VERSION ""

NS_ :

BS_:

BU_: VMCU TPM RCIOM FCIOM FAS ECUspare4 EBS EAS CCIOM BPMU APM

BO_ 1934 Debug6_FCIOM_Chassi: 8 FCIOM
 SG_ Debug_6_FCIOM : 0|64@1+ (1,0) [0|0] "" Vector__XXX

BO_ 1938 Debug6_FAS_Chassi: 8 FAS
 SG_ Debug_6_FAS : 0|64@1+ (1,0) [0|0] "" Vector__XXX

BO_ 1939 Debug6_EAS_Chassi: 8 EAS
 SG_ Debug_6_EAS : 0|64@1+ (1,0) [0|0] "" Vector__XXX

BO_ 1933 Debug6_CCIOM_Chassi: 8 CCIOM
 SG_ Debug_6_CCIOM : 0|64@1+ (1,0) [0|0] "" Vector__XXX

BO_ 1932 Debug6_BPMU_Chassi: 8 BPMU
 SG_ Debug_6_BPMU : 0|64@1+ (1,0) [0|0] "" Vector__XXX

BO_ 1936 Debug6_APM_Chassi: 8 APM
 SG_ Debug_6_APM : 0|64@1+ (1,0) [0|0] "" Vector__XXX

BO_ 1929 Debug5_TPM_Chassi: 8 TPM
 SG_ Debug_5_TPM : 0|64@1+ (1,0) [0|0] "" Vector__XXX

BO_ 1927 Debug5_RCIOM_Chassi: 8 RCIOM
 SG_ Debug_5_RCIOM : 0|64@1+ (1,0) [0|0] "" Vector__XXX

BO_ 1926 Debug5_FCIOM_Chassi: 8 FCIOM
 SG_ Debug_5_FCIOM : 0|64@1+ (1,0) [0|0] "" Vector__XXX

BO_ 1930 Debug5_FAS_Chassi: 8 FAS
 SG_ Debug_5_FAS : 0|64@1+ (1,0) [0|0] "" Vector__XXX

BO_ 1931 Debug5_EAS_Chassi: 8 EAS
 SG_ Debug_5_EAS : 0|64@1+ (1,0) [0|0] "" Vector__XXX

BO_ 1925 Debug5_CCIOM_Chassi: 8 CCIOM
 SG_ Debug_5_CCIOM : 0|64@1+ (1,0) [0|0] "" Vector__XXX

BO_ 1924 Debug5_BPMU_Chassi: 8 BPMU
 SG_ Debug_5_BPMU : 0|64@1+ (1,0) [0|0] "" Vector__XXX

BO_ 1928 Debug5_APM_Chassi: 8 APM
 SG_ Debug_5_APM : 0|64@1+ (1,0) [0|0] "" Vector__XXX

BO_ 1921 Debug4_TPM_Chassi: 8 TPM
 SG_ Debug_4_TPM : 0|64@1+ (1,0) [0|0] "" Vector__XXX

BO_ 1919 Debug4_RCIOM_Chassi: 8 RCIOM
 SG_ Debug_4_RCIOM : 0|64@1+ (1,0) [0|0] "" Vector__XXX

BO_ 1918 Debug4_FCIOM_Chassi: 8 FCIOM
 SG_ Debug_4_FCIOM : 0|64@1+ (1,0) [0|0] "" Vector__XXX

BO_ 1922 Debug4_FAS_Chassi: 8 FAS
 SG_ Debug_4_FAS : 0|64@1+ (1,0) [0|0] "" Vector__XXX

BO_ 1923 Debug4_EAS_Chassi: 8 EAS
 SG_ Debug_4_EAS : 0|64@1+ (1,0) [0|0] "" Vector__XXX

BO_ 1917 Debug4_CCIOM_Chassi: 8 CCIOM
 SG_ Debug_4_CCIOM : 0|64@1+ (1,0) [0|0] "" Vector__XXX

BO_ 1916 Debug4_BPMU_Chassi: 8 BPMU
 SG_ Debug_4_BPMU : 0|64@1+ (1,0) [0|0] "" Vector__XXX

BO_ 1920 Debug4_APM_Chassi: 8 APM
 SG_ Debug_4_APM : 0|64@1+ (1,0) [0|0] "" Vector__XXX

BO_ 1913 Debug3_TPM_Chassi: 8 TPM
 SG_ Debug_3_TPM : 0|64@1+ (1,0) [0|0] "" Vector__XXX

BO_ 1911 Debug3_RCIOM_Chassi: 8 RCIOM
 SG_ Debug_3_RCIOM : 0|64@1+ (1,0) [0|0] "" Vector__XXX

BO_ 1910 Debug3_FCIOM_Chassi: 8 FCIOM
 SG_ Debug_3_FCIOM : 0|64@1+ (1,0) [0|0] "" Vector__XXX

BO_ 1914 Debug3_FAS_Chassi: 8 FAS
 SG_ Debug_3_FAS : 0|64@1+ (1,0) [0|0] "" Vector__XXX

BO_ 1915 Debug3_EAS_Chassi: 8 EAS
 SG_ Debug_3_EAS : 0|64@1+ (1,0) [0|0] "" Vector__XXX

BO_ 1909 Debug3_CCIOM_Chassi: 8 CCIOM
 SG_ Debug_3_CCIOM : 0|64@1+ (1,0) [0|0] "" Vector__XXX

BO_ 1908 Debug3_BPMU_Chassi: 8 BPMU
 SG_ Debug_3_BPMU : 0|64@1+ (1,0) [0|0] "" Vector__XXX

BO_ 1912 Debug3_APM_Chassi: 8 APM
 SG_ Debug_3_APM : 0|64@1+ (1,0) [0|0] "" Vector__XXX

BO_ 1905 Debug2_TPM_Chassi: 8 TPM
 SG_ Debug_2_TPM : 0|64@1+ (1,0) [0|0] "" Vector__XXX

BO_ 1903 Debug2_RCIOM_Chassi: 8 RCIOM
 SG_ Debug_2_RCIOM : 0|64@1+ (1,0) [0|0] "" Vector__XXX

BO_ 1902 Debug2_FCIOM_Chassi: 8 FCIOM
 SG_ Debug_2_FCIOM : 0|64@1+ (1,0) [0|0] "" Vector__XXX

BO_ 1906 Debug2_FAS_Chassi: 8 FAS
 SG_ Debug_2_FAS : 0|64@1+ (1,0) [0|0] "" Vector__XXX

BO_ 1907 Debug2_EAS_Chassi: 8 EAS
 SG_ Debug_2_EAS : 0|64@1+ (1,0) [0|0] "" Vector__XXX

BO_ 1901 Debug2_CCIOM_Chassi: 8 CCIOM
 SG_ Debug_2_CCIOM : 0|64@1+ (1,0) [0|0] "" Vector__XXX

BO_ 1900 Debug2_BPMU_Chassi: 8 BPMU
 SG_ Debug_2_BPMU : 0|64@1+ (1,0) [0|0] "" Vector__XXX

BO_ 1904 Debug2_APM_Chassi: 8 APM
 SG_ Debug_2_APM : 0|64@1+ (1,0) [0|0] "" Vector__XXX

BO_ 1885 Debug21_APM_Chassi: 8 APM
 SG_ Debug_21_APM : 0|64@1+ (1,0) [0|0] "" Vector__XXX

BO_ 1884 Debug20_APM_Chassi: 8 APM
 SG_ Debug_20_APM : 0|64@1+ (1,0) [0|0] "" Vector__XXX

BO_ 1897 Debug1_TPM_Chassi: 8 Vector__XXX
 SG_ Debug_1_TPM : 0|64@1+ (1,0) [0|0] ""  TPM

BO_ 1895 Debug1_RCIOM_Chassi: 8 Vector__XXX
 SG_ Debug_1_RCIOM : 0|64@1+ (1,0) [0|0] ""  RCIOM

BO_ 1894 Debug1_FCIOM_Chassi: 8 Vector__XXX
 SG_ Debug_1_FCIOM : 0|64@1+ (1,0) [0|0] ""  FCIOM

BO_ 1898 Debug1_FAS_Chassi: 8 Vector__XXX
 SG_ Debug_1_FAS : 0|64@1+ (1,0) [0|0] ""  FAS

BO_ 1899 Debug1_EAS_Chassi: 8 Vector__XXX
 SG_ Debug_1_EAS : 0|64@1+ (1,0) [0|0] ""  EAS

BO_ 1893 Debug1_CCIOM_Chassi: 8 Vector__XXX
 SG_ Debug_1_CCIOM : 0|64@1+ (1,0) [0|0] ""  CCIOM

BO_ 1892 Debug1_BPMU_Chassi: 8 Vector__XXX
 SG_ Debug_1_BPMU : 0|64@1+ (1,0) [0|0] ""  BPMU

BO_ 1896 Debug1_APM_Chassi: 8 Vector__XXX
 SG_ Debug_1_APM : 0|64@1+ (1,0) [0|0] ""  APM

BO_ 1883 Debug19_APM_Chassi: 8 APM
 SG_ Debug_19_APM : 0|64@1+ (1,0) [0|0] "" Vector__XXX

BO_ 1882 Debug18_APM_Chassi: 8 APM
 SG_ Debug_18_APM : 0|64@1+ (1,0) [0|0] "" Vector__XXX

BO_ 1881 Debug17_APM_Chassi: 8 APM
 SG_ Debug_17_APM : 0|64@1+ (1,0) [0|0] "" Vector__XXX

BO_ 1959 Debug16_FAS_Chassi: 8 FAS
 SG_ Debug_16_FAS : 0|64@1+ (1,0) [0|0] "" Vector__XXX

BO_ 1880 Debug16_APM_Chassi: 8 APM
 SG_ Debug_16_APM : 0|64@1+ (1,0) [0|0] "" Vector__XXX

BO_ 1891 Debug15_FAS_Chassi: 8 FAS
 SG_ Debug_15_FAS : 0|64@1+ (1,0) [0|0] "" Vector__XXX

BO_ 1983 Debug15_APM_Chassi: 8 APM
 SG_ Debug_15_APM : 0|64@1+ (1,0) [0|0] "" Vector__XXX

BO_ 1890 Debug14_FAS_Chassi: 8 FAS
 SG_ Debug_14_FAS : 0|64@1+ (1,0) [0|0] "" Vector__XXX

BO_ 1982 Debug14_APM_Chassi: 8 APM
 SG_ Debug_14_APM : 0|64@1+ (1,0) [0|0] "" Vector__XXX

BO_ 1889 Debug13_FAS_Chassi: 8 FAS
 SG_ Debug_13_FAS : 0|64@1+ (1,0) [0|0] "" Vector__XXX

BO_ 1981 Debug13_APM_Chassi: 8 APM
 SG_ Debug_13_APM : 0|64@1+ (1,0) [0|0] "" Vector__XXX

BO_ 1888 Debug12_FAS_Chassi: 8 FAS
 SG_ Debug_12_FAS : 0|64@1+ (1,0) [0|0] "" Vector__XXX

BO_ 1963 Debug12_CCIOM_Chassi: 8 CCIOM
 SG_ Debug_12_CCIOM : 0|64@1+ (1,0) [0|0] "" Vector__XXX

BO_ 1964 Debug12_APM_Chassi: 8 APM
 SG_ Debug_12_APM : 0|64@1+ (1,0) [0|0] "" Vector__XXX

BO_ 1961 Debug11_RCIOM_Chassi: 8 RCIOM
 SG_ Debug_11_RCIOM : 0|64@1+ (1,0) [0|0] "" Vector__XXX

BO_ 1887 Debug11_FAS_Chassi: 8 FAS
 SG_ Debug_11_FAS : 0|64@1+ (1,0) [0|0] "" Vector__XXX

BO_ 1960 Debug11_CCIOM_Chassi: 8 CCIOM
 SG_ Debug_11_CCIOM : 0|64@1+ (1,0) [0|0] "" Vector__XXX

BO_ 1962 Debug11_APM_Chassi: 8 APM
 SG_ Debug_11_APM : 0|64@1+ (1,0) [0|0] "" Vector__XXX

BO_ 1957 Debug10_RCIOM_Chassi: 8 RCIOM
 SG_ Debug_10_RCIOM : 0|64@1+ (1,0) [0|0] "" Vector__XXX

BO_ 1886 Debug10_FAS_Chassi: 8 FAS
 SG_ Debug_10_FAS : 0|64@1+ (1,0) [0|0] "" Vector__XXX

BO_ 1956 Debug10_CCIOM_Chassi: 8 CCIOM
 SG_ Debug_10_CCIOM : 0|64@1+ (1,0) [0|0] "" Vector__XXX

BO_ 1955 Debug10_BPMU_Chassi: 8 BPMU
 SG_ Debug_10_BPMU : 0|64@1+ (1,0) [0|0] "" Vector__XXX

BO_ 1958 Debug10_APM_Chassi: 8 APM
 SG_ Debug_10_APM : 0|64@1+ (1,0) [0|0] "" Vector__XXX

BO_ 2041 DSPTesterResp: 8 FAS
 SG_ DSPTesterRespSig : 0|64@1+ (1,0) [0|0] "" Vector__XXX

BO_ 2047 DSPTesterReq: 8 Vector__XXX
 SG_ DSPTesterReqSig : 0|64@1+ (1,0) [0|0] ""  FAS

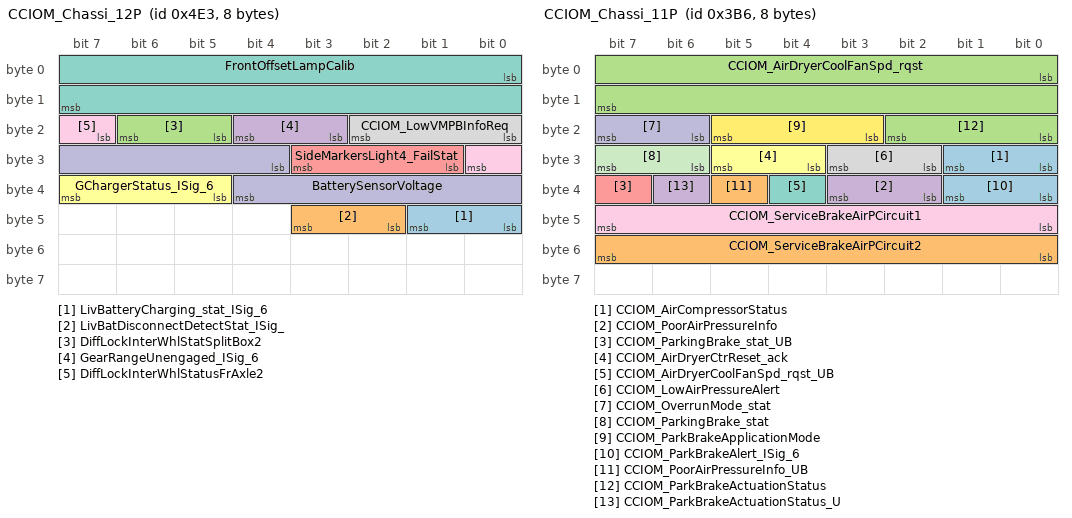
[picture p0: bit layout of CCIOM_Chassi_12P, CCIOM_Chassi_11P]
BO_ 1251 CCIOM_Chassi_12P: 8 CCIOM
 SG_ LivBatteryCharging_stat_ISig_6 : 40|2@1+ (1,0) [0|0] ""  BPMU,VMCU
 SG_ LivBatDisconnectDetectStat_ISig_ : 42|2@1+ (1,0) [0|0] ""  VMCU
 SG_ DiffLockInterWhlStatSplitBox2 : 21|2@1+ (1,0) [0|0] ""  VMCU
 SG_ GearRangeUnengaged_ISig_6 : 19|2@1+ (1,0) [0|0] ""  VMCU
 SG_ SideMarkersLight4_FailStat : 25|3@1+ (1,0) [0|0] ""  VMCU
 SG_ GChargerStatus_ISig_6 : 37|3@1+ (1,0) [0|0] ""  VMCU
 SG_ FrontOffsetLampCalib : 0|16@1+ (0.1,-3200) [-3200|3353.5] "mm"  RCIOM
 SG_ CCIOM_LowVMPBInfoReq : 16|3@1+ (1,0) [0|0] ""  EBS
 SG_ DiffLockInterWhlStatusFrAxle2 : 23|2@1+ (1,0) [0|0] ""  VMCU
 SG_ BatterySensorVoltage : 28|9@1+ (0.1,0) [0|51.1] "V"  BPMU

BO_ 950 CCIOM_Chassi_11P: 8 CCIOM
 SG_ CCIOM_AirCompressorStatus : 24|2@1+ (1,0) [0|0] ""  VMCU
 SG_ CCIOM_ServiceBrakeAirPCircuit2 : 48|8@1+ (8,0) [0|2040] "kPa"  RCIOM,VMCU
 SG_ CCIOM_AirDryerCoolFanSpd_rqst : 0|16@1+ (1,0) [0|65535] "rpm"  VMCU
 SG_ CCIOM_PoorAirPressureInfo : 34|2@1+ (1,0) [0|0] ""  VMCU
 SG_ CCIOM_ParkingBrake_stat_UB : 39|1@1+ (1,0) [0|0] ""  VMCU,RCIOM
 SG_ CCIOM_AirDryerCtrReset_ack : 28|2@1+ (1,0) [0|0] ""  VMCU
 SG_ CCIOM_AirDryerCoolFanSpd_rqst_UB : 36|1@1+ (1,0) [0|0] ""  VMCU
 SG_ CCIOM_LowAirPressureAlert : 26|2@1+ (1,0) [0|0] ""  EBS,VMCU
 SG_ CCIOM_ServiceBrakeAirPCircuit1 : 40|8@1+ (8,0) [0|2040] "kPa"  RCIOM,VMCU
 SG_ CCIOM_OverrunMode_stat : 22|2@1+ (1,0) [0|0] ""  VMCU
 SG_ CCIOM_ParkingBrake_stat : 30|2@1+ (1,0) [0|0] ""  VMCU,RCIOM
 SG_ CCIOM_ParkBrakeApplicationMode : 19|3@1+ (1,0) [0|0] ""  VMCU
 SG_ CCIOM_ParkBrakeAlert_ISig_6 : 32|2@1+ (1,0) [0|0] ""  VMCU
 SG_ CCIOM_PoorAirPressureInfo_UB : 37|1@1+ (1,0) [0|0] ""  VMCU
 SG_ CCIOM_ParkBrakeActuationStatus : 16|3@1+ (1,0) [0|0] ""  EBS,VMCU,RCIOM
 SG_ CCIOM_ParkBrakeActuationStatus_U : 38|1@1+ (1,0) [0|0] ""  EBS,RCIOM,VMCU

BO_ 1495 CCIOM_Chassi_10P: 8 CCIOM
 SG_ CCIOM_AirCtrMileagePrediction : 0|32@1+ (1,0) [0|4294967295] "km"  VMCU
 SG_ CCIOM_AirCtrWearingPercentage : 32|8@1+ (1,0) [0|255] "Percent"  VMCU

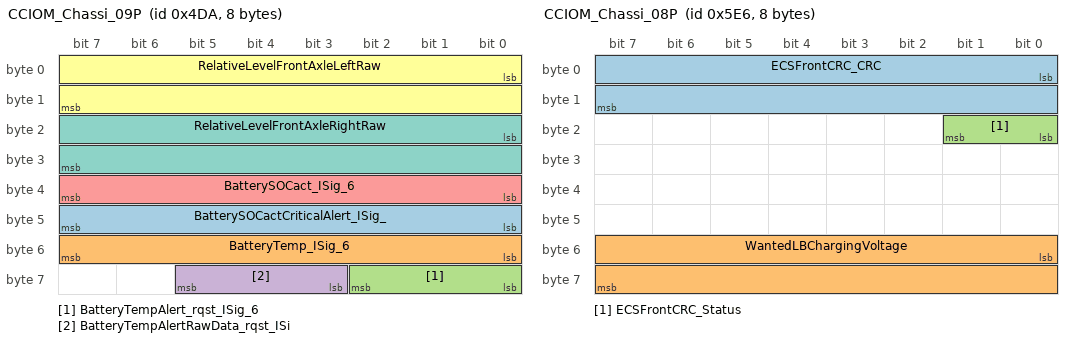
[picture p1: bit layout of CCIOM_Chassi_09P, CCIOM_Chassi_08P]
BO_ 1242 CCIOM_Chassi_09P: 8 CCIOM
 SG_ BatterySOCactCriticalAlert_ISig_ : 40|8@1+ (0.5,0) [0|127.5] "Percent"  VMCU
 SG_ BatteryTemp_ISig_6 : 48|8@1+ (1,-45) [-45|210] "DegreeC"  BPMU,VMCU
 SG_ BatteryTempAlert_rqst_ISig_6 : 56|3@1+ (1,0) [0|0] ""  VMCU
 SG_ BatteryTempAlertRawData_rqst_ISi : 59|3@1+ (1,0) [0|0] ""  VMCU
 SG_ BatterySOCact_ISig_6 : 32|8@1+ (0.5,0) [0|127.5] "Percent"  VMCU
 SG_ RelativeLevelFrontAxleLeftRaw : 0|16@1+ (0.1,-3200) [-3200|3353.5] "mm"  RCIOM
 SG_ RelativeLevelFrontAxleRightRaw : 16|16@1+ (0.1,-3200) [-3200|3353.5] "mm"  RCIOM

BO_ 1510 CCIOM_Chassi_08P: 8 CCIOM
 SG_ ECSFrontCRC_CRC : 0|16@1+ (1,0) [0|65535] ""  RCIOM
 SG_ WantedLBChargingVoltage : 48|16@1+ (0.01,0) [0|655.35] "V"  BPMU
 SG_ ECSFrontCRC_Status : 16|2@1+ (1,0) [0|0] ""  RCIOM

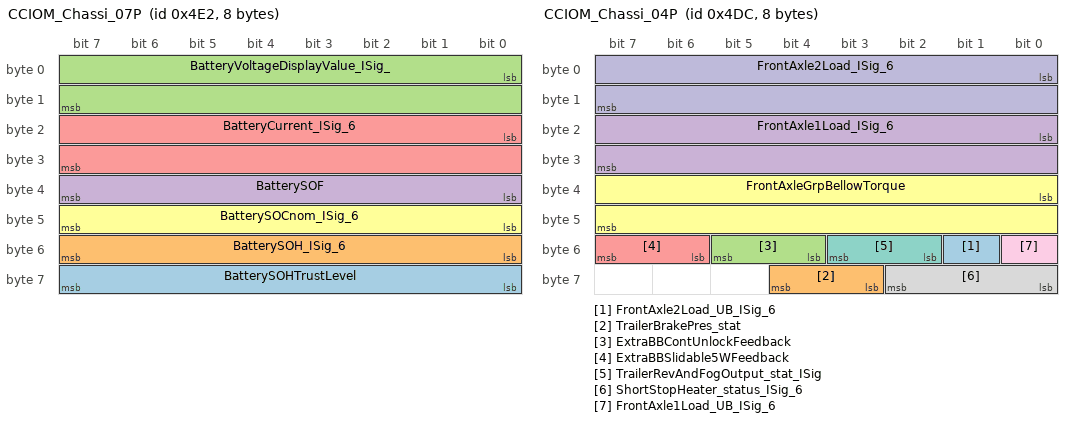
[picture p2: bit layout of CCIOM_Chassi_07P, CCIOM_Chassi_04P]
BO_ 1250 CCIOM_Chassi_07P: 8 CCIOM
 SG_ BatterySOHTrustLevel : 56|8@1+ (0.5,0) [0|127.5] "Percent"  VMCU
 SG_ BatterySOH_ISig_6 : 48|8@1+ (0.5,0) [0|127.5] "Percent"  VMCU
 SG_ BatteryVoltageDisplayValue_ISig_ : 0|16@1+ (0.05,0) [0|3276.75] "V"  VMCU
 SG_ BatterySOF : 32|8@1+ (1,0) [0|255] "h"  VMCU
 SG_ BatteryCurrent_ISig_6 : 16|16@1+ (0.05,-1600) [-1600|1676.75] "A"  VMCU
 SG_ BatterySOCnom_ISig_6 : 40|8@1+ (0.5,0) [0|127.5] "Percent"  BPMU,VMCU

BO_ 823 CCIOM_Chassi_06P: 8 CCIOM
 SG_ FifthWheelLockingInformation_ISi : 12|4@1+ (1,0) [0|0] ""  RCIOM,VMCU
 SG_ DoubleFrontAxleSteeringWarning_I : 2|2@1+ (1,0) [0|0] ""  VMCU
 SG_ DifferentialLockStateFrAxle1_ISi : 6|2@1+ (1,0) [0|0] ""  VMCU
 SG_ ElectricalLoadReduction_rqst_UB_ : 30|1@1+ (1,0) [0|0] ""  RCIOM,VMCU
 SG_ DirInd_MiddleSide_Status : 58|3@1+ (1,0) [0|0] ""  VMCU
 SG_ ExtendedTrailerBrakeValveStat : 61|2@1+ (1,0) [0|0] ""  VMCU
 SG_ DifferentialLockStateFrAxle1_UB_ : 31|1@1+ (1,0) [0|0] ""  VMCU
 SG_ TransmLowRangeSenseSwitch_ISig_6 : 8|2@1+ (1,0) [0|0] ""  VMCU
 SG_ ElectricalLoadReduction_rqst_ISi : 21|3@1+ (1,0) [0|0] ""  RCIOM,VMCU
 SG_ WrknLghtChassisOutpFalr_stat : 48|3@1+ (1,0) [0|0] ""  VMCU
 SG_ ManTransmiOilTemp_ISig_6 : 32|16@1+ (0.03125,-273) [-273|1774.96875] "DegreeC"  VMCU
 SG_ LoadCutOffIndication_cmd_ISig_6 : 4|2@1+ (1,0) [0|0] ""  VMCU
 SG_ TransmReverseDirectionSw_stat_IS : 56|2@1+ (1,0) [0|0] ""  VMCU
 SG_ BatterySOCAlert_rqst_ISig_6 : 16|3@1+ (1,0) [0|0] ""  VMCU
 SG_ GearSplit_Status_UB_ISig_6 : 52|1@1+ (1,0) [0|0] ""  VMCU
 SG_ BatteryCapacity_Ack : 19|2@1+ (1,0) [0|0] ""  VMCU
 SG_ ManTransmiOilTemp_UB_ISig_6 : 51|1@1+ (1,0) [0|0] ""  VMCU
 SG_ FrontLimpHomeTrigger : 24|3@1+ (1,0) [0|0] ""  RCIOM
 SG_ FifthWheelLockingInformation_UB_ : 53|1@1+ (1,0) [0|0] ""  RCIOM,VMCU
 SG_ GearSplit_Status_ISig_6 : 10|2@1+ (1,0) [0|0] ""  VMCU
 SG_ DiffLockInterWhlStatusSplitBox_I : 54|2@1+ (1,0) [0|0] ""  VMCU
 SG_ FifthWheelHandleLock_ind : 27|2@1+ (1,0) [0|0] ""  VMCU
 SG_ DifferentialLockStateCentral_ISi : 0|2@1+ (1,0) [0|0] ""  VMCU

BO_ 1244 CCIOM_Chassi_04P: 8 CCIOM
 SG_ FrontAxle2Load_UB_ISig_6 : 49|1@1+ (1,0) [0|0] ""  VMCU,EBS,FAS,APM,RCIOM
 SG_ TrailerBrakePres_stat : 59|2@1+ (1,0) [0|0] ""  VMCU
 SG_ ExtraBBContUnlockFeedback : 52|2@1+ (1,0) [0|0] ""  VMCU
 SG_ FrontAxle1Load_ISig_6 : 16|16@1+ (0.5,0) [0|32767.5] "kg"  RCIOM,VMCU,EBS,APM,FAS
 SG_ ExtraBBSlidable5WFeedback : 54|2@1+ (1,0) [0|0] ""  VMCU
 SG_ FrontAxleGrpBellowTorque : 32|16@1+ (1000,-10000000) [-10000000|55535000] "Nm"  RCIOM
 SG_ TrailerRevAndFogOutput_stat_ISig : 50|2@1+ (1,0) [0|0] ""  RCIOM,VMCU
 SG_ ShortStopHeater_status_ISig_6 : 56|3@1+ (1,0) [0|0] ""  VMCU
 SG_ FrontAxle1Load_UB_ISig_6 : 48|1@1+ (1,0) [0|0] ""  FAS,VMCU,APM,EBS,RCIOM
 SG_ FrontAxle2Load_ISig_6 : 0|16@1+ (0.5,0) [0|32767.5] "kg"  APM,FAS,VMCU,RCIOM,EBS

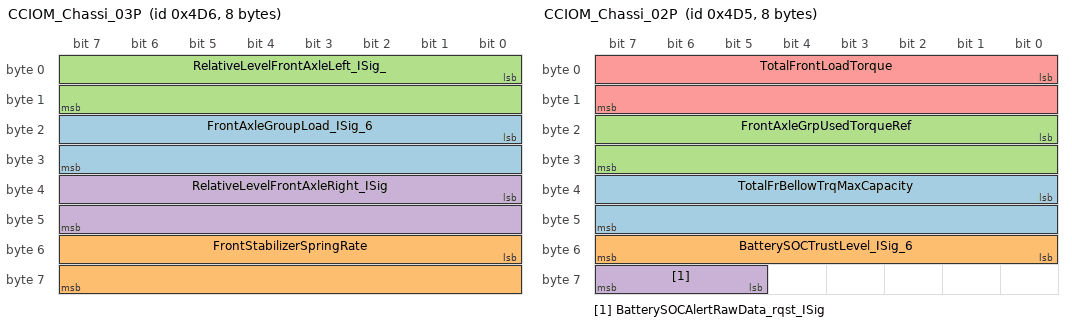
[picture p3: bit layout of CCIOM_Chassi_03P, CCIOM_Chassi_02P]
BO_ 1238 CCIOM_Chassi_03P: 8 CCIOM
 SG_ FrontAxleGroupLoad_ISig_6 : 16|16@1+ (2,0) [0|131070] "kg"  RCIOM,VMCU
 SG_ FrontStabilizerSpringRate : 48|16@1+ (1,0) [0|65535] "kNm_per_rad"  RCIOM
 SG_ RelativeLevelFrontAxleLeft_ISig_ : 0|16@1+ (0.1,-3200) [-3200|3353.5] "mm"  FAS,EBS,VMCU,RCIOM
 SG_ RelativeLevelFrontAxleRight_ISig : 32|16@1+ (0.1,-3200) [-3200|3353.5] "mm"  RCIOM,VMCU,EBS

BO_ 1237 CCIOM_Chassi_02P: 8 CCIOM
 SG_ TotalFrBellowTrqMaxCapacity : 32|16@1+ (1000,-10000000) [-10000000|55535000] "Nm"  RCIOM
 SG_ BatterySOCTrustLevel_ISig_6 : 48|8@1+ (0.5,0) [0|127.5] "Percent"  VMCU
 SG_ FrontAxleGrpUsedTorqueRef : 16|16@1+ (1000,-10000000) [-10000000|55535000] "Nm"  RCIOM
 SG_ BatterySOCAlertRawData_rqst_ISig : 61|3@1+ (1,0) [0|0] ""  BPMU,VMCU
 SG_ TotalFrontLoadTorque : 0|16@1+ (1000,-10000000) [-10000000|55535000] "Nm"  RCIOM

BO_ 774 CCIOM_Chassi_01P: 8 CCIOM
 SG_ FuelVolume_ISig_6 : 0|11@1+ (1,0) [0|2047] "l"  VMCU
 SG_ FuelVolume_UB_ISig_6 : 14|1@1+ (1,0) [0|0] ""  VMCU
 SG_ MainSwitch_Status : 28|2@1+ (1,0) [0|0] ""  APM,BPMU,VMCU
 SG_ Pto1FeedbackStatus_ISig_6 : 26|2@1+ (1,0) [0|0] ""  VMCU
 SG_ SWBrakeSwitch2 : 50|2@1+ (1,0) [0|0] ""  RCIOM
 SG_ ReverseGearEngaged_UB_ISig_6 : 38|1@1+ (1,0) [0|0] ""  FAS,VMCU,APM,RCIOM
 SG_ ReverseGearEngaged_ISig_6 : 36|2@1+ (1,0) [0|0] ""  VMCU,FAS,APM,RCIOM
 SG_ TransmissionNeutralSwitch_UB_ISi : 41|1@1+ (1,0) [0|0] ""  APM,VMCU
 SG_ SecuredNeutralPosition_ISig_6 : 34|2@1+ (1,0) [0|0] ""  VMCU,EBS,APM
 SG_ SecuredNeutralPosition_UB_ISig_6 : 40|1@1+ (1,0) [0|0] ""  APM,EBS,VMCU
 SG_ FuelLevel_ISig_6 : 16|8@1+ (0.4,0) [0|102] "Percent"  VMCU
 SG_ FuelLevel_UB_ISig_6 : 13|1@1+ (1,0) [0|0] ""  VMCU
 SG_ TransmSecuredForCrank_stat : 32|2@1+ (1,0) [0|0] ""  VMCU
 SG_ FrontTargetLevelReached : 11|2@1+ (1,0) [0|0] ""  RCIOM
 SG_ Pto1FeedbackStatus_UB_ISig_6 : 39|1@1+ (1,0) [0|0] ""  VMCU
 SG_ TransmissionNeutralSwitch_ISig_6 : 24|2@1+ (1,0) [0|0] ""  VMCU,APM
 SG_ BrakePressureSensorDemand2 : 42|8@1+ (1,0) [0|255] "Percent"  RCIOM

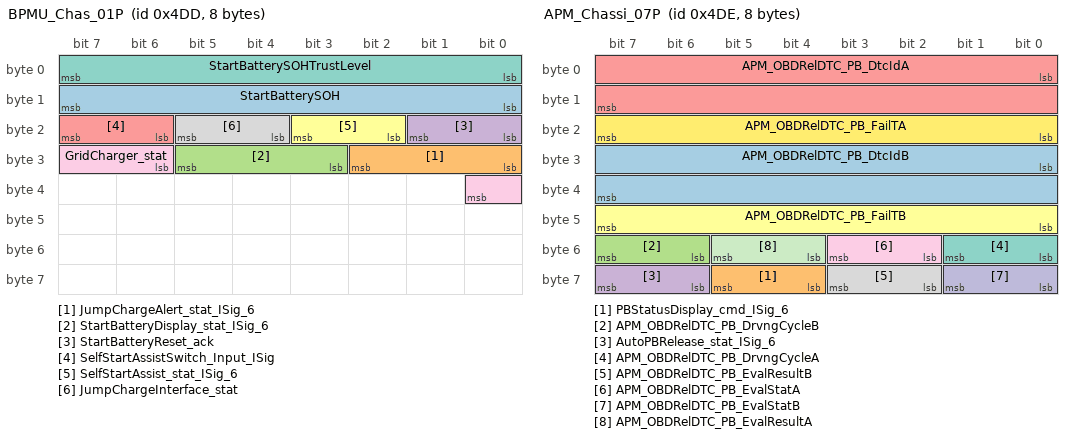
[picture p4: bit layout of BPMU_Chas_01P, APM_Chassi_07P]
BO_ 1245 BPMU_Chas_01P: 8 BPMU
 SG_ StartBatterySOH : 8|8@1+ (0.5,0) [0|127.5] "Percent"  VMCU
 SG_ JumpChargeAlert_stat_ISig_6 : 24|3@1+ (1,0) [0|0] ""  VMCU
 SG_ StartBatteryDisplay_stat_ISig_6 : 27|3@1+ (1,0) [0|0] ""  VMCU
 SG_ StartBatteryReset_ack : 16|2@1+ (1,0) [0|0] ""  VMCU
 SG_ SelfStartAssistSwitch_Input_ISig : 22|2@1+ (1,0) [0|0] ""  VMCU
 SG_ SelfStartAssist_stat_ISig_6 : 18|2@1+ (1,0) [0|0] ""  VMCU
 SG_ StartBatterySOHTrustLevel : 0|8@1+ (0.5,0) [0|127.5] "Percent"  VMCU
 SG_ JumpChargeInterface_stat : 20|2@1+ (1,0) [0|0] ""  CCIOM
 SG_ GridCharger_stat : 30|3@1+ (1,0) [0|0] ""  CCIOM

BO_ 1719 AnmMsg_VMCU_ChassisSubnet: 4 VMCU
 SG_ AnmSig_VMCU_ChassisSubnet : 0|32@1+ (1,0) [0|4294967295] ""  BPMU,RCIOM,APM,FCIOM,ECUspare4,TPM,EBS,CCIOM,EAS,FAS

BO_ 1718 AnmMsg_TPM_ChassisSubnet: 4 TPM
 SG_ AnmSig_TPM_ChassisSubnet : 0|32@1+ (1,0) [0|4294967295] ""  CCIOM,RCIOM,EBS,FCIOM,ECUspare4,FAS,BPMU,APM,EAS,VMCU

BO_ 1717 AnmMsg_RCIOM_ChassisSubnet: 4 RCIOM
 SG_ AnmSig_RCIOM_ChassisSubnet : 0|32@1+ (1,0) [0|4294967295] ""  APM,TPM,EBS,VMCU,BPMU,CCIOM,FAS,EAS,ECUspare4,FCIOM

BO_ 1716 AnmMsg_FCIOM_ChassisSubnet: 4 FCIOM
 SG_ AnmSig_FCIOM_ChassisSubnet : 0|32@1+ (1,0) [0|4294967295] ""  APM,BPMU,EBS,ECUspare4,FAS,RCIOM,CCIOM,VMCU,TPM,EAS

BO_ 1715 AnmMsg_FAS_ChassisSubnet: 4 FAS
 SG_ AnmSig_FAS_ChassisSubnet : 0|32@1+ (1,0) [0|4294967295] ""  ECUspare4,RCIOM,FCIOM,APM,CCIOM,TPM,EAS,EBS,BPMU,VMCU

BO_ 1721 AnmMsg_ECUspare4_ChassisSubnet: 4 ECUspare4
 SG_ AnmSig_ECUspare4_ChassisSubnet : 0|32@1+ (1,0) [0|4294967295] ""  EAS,APM,BPMU,EBS,TPM,FAS,FCIOM,VMCU,RCIOM,CCIOM

BO_ 1714 AnmMsg_EBS_ChassisSubnet: 4 EBS
 SG_ AnmSig_EBS_ChassisSubnet : 0|32@1+ (1,0) [0|4294967295] ""  RCIOM,FAS,ECUspare4,VMCU,EAS,FCIOM,APM,CCIOM,TPM,BPMU

BO_ 1722 AnmMsg_EAS_ChassisSubnet: 4 EAS
 SG_ AnmSig_EAS_ChassisSubnet : 0|32@1+ (1,0) [0|4294967295] ""  ECUspare4,EBS,VMCU,FAS,BPMU,FCIOM,APM,CCIOM,TPM,RCIOM

BO_ 1713 AnmMsg_CCIOM_ChassisSubnet: 4 CCIOM
 SG_ AnmSig_CCIOM_ChassisSubnet : 0|32@1+ (1,0) [0|4294967295] ""  TPM,APM,ECUspare4,RCIOM,FAS,FCIOM,EAS,EBS,BPMU,VMCU

BO_ 1720 AnmMsg_BPMU_ChassisSubnet: 4 BPMU
 SG_ AnmSig_BPMU_ChassisSubnet : 0|32@1+ (1,0) [0|4294967295] ""  CCIOM,APM,ECUspare4,VMCU,EAS,EBS,FCIOM,RCIOM,FAS,TPM

BO_ 1712 AnmMsg_APM_ChassisSubnet: 4 APM
 SG_ AnmSig_APM_ChassisSubnet : 0|32@1+ (1,0) [0|4294967295] ""  CCIOM,RCIOM,EAS,FCIOM,EBS,VMCU,ECUspare4,BPMU,TPM,FAS

BO_ 1246 APM_Chassi_07P: 8 APM
 SG_ APM_OBDRelDTC_PB_DtcIdB : 24|16@1+ (1,0) [0|65535] ""  VMCU
 SG_ PBStatusDisplay_cmd_ISig_6 : 60|2@1+ (1,0) [0|0] ""  VMCU
 SG_ APM_OBDRelDTC_PB_DrvngCycleB : 54|2@1+ (1,0) [0|0] ""  VMCU
 SG_ AutoPBRelease_stat_ISig_6 : 62|2@1+ (1,0) [0|0] ""  VMCU
 SG_ APM_OBDRelDTC_PB_DtcIdA : 0|16@1+ (1,0) [0|65535] ""  VMCU
 SG_ APM_OBDRelDTC_PB_FailTB : 40|8@1+ (1,0) [0|255] ""  VMCU
 SG_ APM_OBDRelDTC_PB_DrvngCycleA : 48|2@1+ (1,0) [0|0] ""  VMCU
 SG_ APM_OBDRelDTC_PB_EvalResultB : 58|2@1+ (1,0) [0|0] ""  VMCU
 SG_ APM_OBDRelDTC_PB_EvalStatA : 50|2@1+ (1,0) [0|0] ""  VMCU
 SG_ APM_OBDRelDTC_PB_EvalStatB : 56|2@1+ (1,0) [0|0] ""  VMCU
 SG_ APM_OBDRelDTC_PB_EvalResultA : 52|2@1+ (1,0) [0|0] ""  VMCU
 SG_ APM_OBDRelDTC_PB_FailTA : 16|8@1+ (1,0) [0|255] ""  VMCU

BO_ 1492 APM_Chassi_06P: 8 APM
 SG_ APM_AirCtrMileagePrediction : 0|32@1+ (1,0) [0|4294967295] "km"  VMCU
 SG_ APM_AirCtrWearingPercentage : 32|8@1+ (1,0) [0|255] "Percent"  VMCU

BO_ 1347 APM_Chassi_05S_FCM: 8 VMCU
 SG_ APM_Chassi_05S_FCS : 0|64@1+ (1,0) [0|0] ""  APM

BO_ 1346 APM_Chassi_05S: 11 APM
 SG_ ECU2VIN_stat_ISig_6 : 0|88@1+ (1,0) [0|0] ""  VMCU

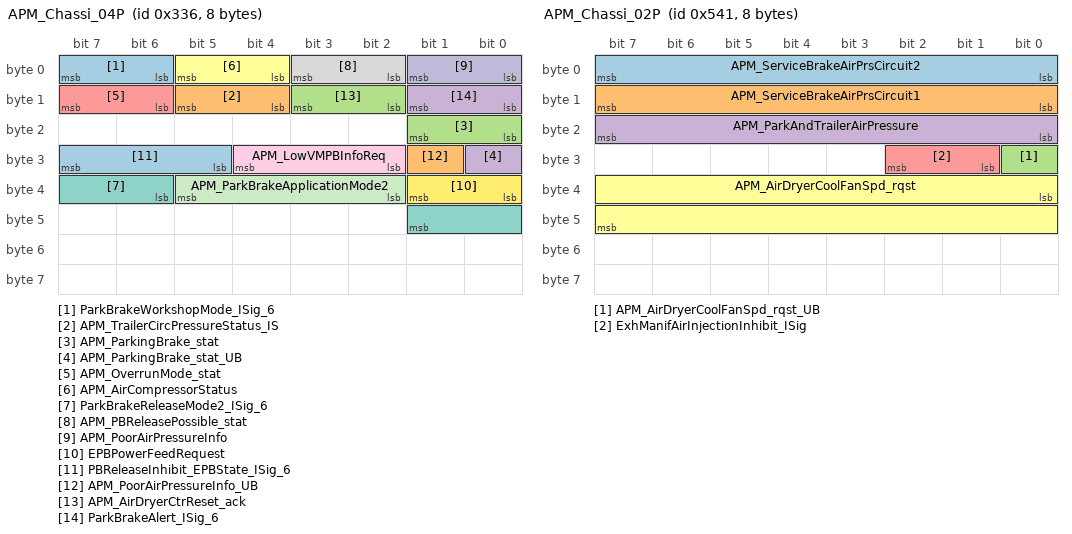
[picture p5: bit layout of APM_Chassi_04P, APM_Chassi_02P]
BO_ 822 APM_Chassi_04P: 8 APM
 SG_ ParkBrakeWorkshopMode_ISig_6 : 6|2@1+ (1,0) [0|0] ""  VMCU
 SG_ APM_TrailerCircPressureStatus_IS : 12|2@1+ (1,0) [0|0] ""  EBS,VMCU
 SG_ APM_ParkingBrake_stat : 16|2@1+ (1,0) [0|0] ""  EBS,VMCU,RCIOM,FAS
 SG_ APM_ParkingBrake_stat_UB : 24|1@1+ (1,0) [0|0] ""  EBS,RCIOM,FAS,VMCU
 SG_ APM_OverrunMode_stat : 14|2@1+ (1,0) [0|0] ""  VMCU
 SG_ APM_AirCompressorStatus : 4|2@1+ (1,0) [0|0] ""  VMCU
 SG_ ParkBrakeReleaseMode2_ISig_6 : 38|4@1+ (1,0) [0|0] ""  EBS,VMCU
 SG_ APM_PBReleasePossible_stat : 2|2@1+ (1,0) [0|0] ""  VMCU
 SG_ APM_LowVMPBInfoReq : 26|3@1+ (1,0) [0|0] ""  EBS
 SG_ APM_PoorAirPressureInfo : 0|2@1+ (1,0) [0|0] ""  VMCU
 SG_ APM_ParkBrakeApplicationMode2 : 34|4@1+ (1,0) [0|0] ""  VMCU,EBS
 SG_ EPBPowerFeedRequest : 32|2@1+ (1,0) [0|0] ""  CCIOM
 SG_ PBReleaseInhibit_EPBState_ISig_6 : 29|3@1+ (1,0) [0|0] ""  VMCU
 SG_ APM_PoorAirPressureInfo_UB : 25|1@1+ (1,0) [0|0] ""  VMCU
 SG_ APM_AirDryerCtrReset_ack : 10|2@1+ (1,0) [0|0] ""  VMCU
 SG_ ParkBrakeAlert_ISig_6 : 8|2@1+ (1,0) [0|0] ""  VMCU

BO_ 1345 APM_Chassi_02P: 8 APM
 SG_ APM_ServiceBrakeAirPrsCircuit2 : 0|8@1+ (8,0) [0|2040] "kPa"  RCIOM,EAS,VMCU
 SG_ APM_ServiceBrakeAirPrsCircuit1 : 8|8@1+ (8,0) [0|2040] "kPa"  RCIOM,VMCU,EAS
 SG_ APM_AirDryerCoolFanSpd_rqst_UB : 24|1@1+ (1,0) [0|0] ""  VMCU
 SG_ APM_ParkAndTrailerAirPressure : 16|8@1+ (8,0) [0|2040] "kPa"  VMCU
 SG_ ExhManifAirInjectionInhibit_ISig : 25|2@1+ (1,0) [0|0] ""  VMCU
 SG_ APM_AirDryerCoolFanSpd_rqst : 32|16@1+ (1,0) [0|65535] "rpm"  VMCU

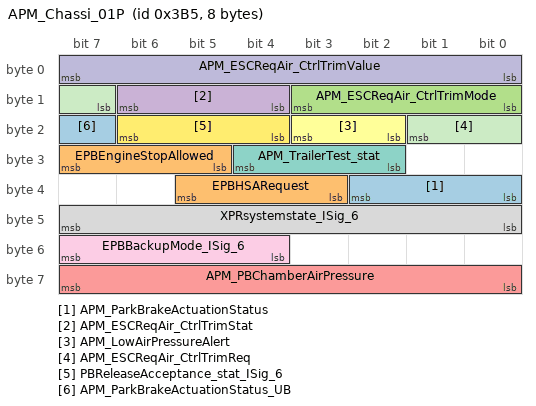
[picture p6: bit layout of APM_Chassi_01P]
BO_ 949 APM_Chassi_01P: 8 APM
 SG_ APM_ParkBrakeActuationStatus : 32|3@1+ (1,0) [0|0] ""  CCIOM,VMCU,RCIOM,EBS,EAS
 SG_ EPBEngineStopAllowed : 29|3@1+ (1,0) [0|0] ""  VMCU
 SG_ APM_ESCReqAir_CtrlTrimMode : 8|4@1+ (1,0) [0|0] ""  VMCU
 SG_ APM_ESCReqAir_CtrlTrimStat : 12|3@1+ (1,0) [0|0] ""  VMCU
 SG_ APM_PBChamberAirPressure : 56|8@1+ (8,0) [0|2040] "kPa"  EBS
 SG_ APM_LowAirPressureAlert : 18|2@1+ (1,0) [0|0] ""  VMCU,EBS
 SG_ APM_TrailerTest_stat : 26|3@1+ (1,0) [0|0] ""  VMCU
 SG_ XPRsystemstate_ISig_6 : 40|8@1+ (1,0) [0|255] "NotApplicable"  EBS,VMCU
 SG_ EPBBackupMode_ISig_6 : 52|4@1+ (1,0) [0|0] ""  CCIOM,VMCU
 SG_ APM_ESCReqAir_CtrlTrimValue : 0|8@1+ (10,0) [0|2550] ""  VMCU
 SG_ APM_ESCReqAir_CtrlTrimReq : 15|3@1+ (1,0) [0|0] ""  VMCU
 SG_ PBReleaseAcceptance_stat_ISig_6 : 20|3@1+ (1,0) [0|0] ""  VMCU
 SG_ APM_ParkBrakeActuationStatus_UB : 23|1@1+ (1,0) [0|0] ""  EAS,CCIOM,VMCU,RCIOM,EBS
 SG_ EPBHSARequest : 35|3@1+ (1,0) [0|0] ""  EBS

CM_ BO_ 2041 "This message is used only for supplier production test.";
CM_ BO_ 2047 "This message is used only for supplier production test.";
CM_ SG_ 1250 BatterySOHTrustLevel "254 Error ; 255 Not available";
CM_ SG_ 1250 BatterySOH_ISig_6 "254 Error ; 255 Not available";
CM_ SG_ 1250 BatteryVoltageDisplayValue_ISig_ "65024 - 65279 Error ; 65280 - 65535 Not available";
CM_ SG_ 1250 BatterySOF "254 Error ; 255 Not Available";
CM_ SG_ 1250 BatteryCurrent_ISig_6 "65024 - 65279 Error ; 65280 - 65535 Not available";
CM_ SG_ 1250 BatterySOCnom_ISig_6 "254 Error ; 255 Not available";
CM_ SG_ 823 ManTransmiOilTemp_ISig_6 "65024 - 65279 Error ; 65280 - 65535 Not available";
CM_ SG_ 1244 FrontAxle1Load_ISig_6 "65024 - 65279 Error ; 65280 - 65535 Not available";
CM_ SG_ 1244 FrontAxleGrpBellowTorque "65024 - 65279 Error ; 65280 - 65535 Not Available";
CM_ SG_ 1244 FrontAxle2Load_ISig_6 "65024 - 65279 Error ; 65280 - 65535 Not available";
CM_ SG_ 1238 FrontAxleGroupLoad_ISig_6 "65024 - 65279 Error ; 65280 - 65535 Not available";
CM_ SG_ 1238 FrontStabilizerSpringRate "65024 - 65279 Error ; 65280 - 65535 Not available";
CM_ SG_ 1238 RelativeLevelFrontAxleLeft_ISig_ "65024 - 65279 Error ; 65280 - 65535 Not available";
CM_ SG_ 1238 RelativeLevelFrontAxleRight_ISig "65024 - 65279 Error ; 65280 - 65535 Not available";
CM_ SG_ 1237 TotalFrBellowTrqMaxCapacity "65024-65279 Error ; 65280-65535 Not Available";
CM_ SG_ 1237 TotalFrontLoadTorque "65024-65279 Error ; 65280-65535 Not Available";
CM_ SG_ 774 FuelLevel_ISig_6 "254 Error ; 255 Not available";
BA_DEF_ BO_  "GenMsgStartDelayTime" INT 0 0;
BA_DEF_ BO_  "GenMsgDelayTime" INT 0 0;
BA_DEF_ BO_  "GenMsgCycleTime" INT 0 0;
BA_DEF_ BO_  "GenMsgSendType" ENUM  "Cyclic","NotUsed","NotUsed","NotUsed","NotUsed","NotUsed","NotUsed","IfActive","NoMsgSendType","NotUsed";
BA_DEF_ SG_  "GenSigStartValue" INT 0 0;
BA_DEF_ SG_  "GenSigInactiveValue" INT 0 0;
BA_DEF_ SG_  "GenSigCycleTimeActive" INT 0 0;
BA_DEF_ SG_  "GenSigCycleTime" INT 0 0;
BA_DEF_ SG_  "GenSigSendType" ENUM  "Cyclic","OnWrite","OnWriteWithRepetition","OnChange","OnChangeWithRepetition","IfActive","IfActiveWithRepetition","NoSigSendType","NotUsed","NotUsed","NotUsed","NotUsed","NotUsed";
BA_DEF_ BO_  "VFrameFormat" ENUM  "StandardCAN","ExtendedCAN","reserved","J1939PG";
BA_DEF_ SG_  "SigType" ENUM  "Default","Range","RangeSigned","ASCII","Discrete","Control","ReferencePGN","DTC","StringDelimiter","StringLength","StringLengthControl";
BA_DEF_ SG_  "SeToolVersion_SIGNAL" STRING ;
BA_DEF_ SG_  "SeToolUniqueID_SIGNAL" STRING ;
BA_DEF_ SG_  "SeToolName_SIGNAL" STRING ;
BA_DEF_ SG_  "SeToolItemID_SIGNAL" STRING ;
BA_DEF_ SG_  "SeToolAncestorID_SIGNAL" STRING ;
BA_DEF_ SG_  "Platform_VMCU1_Sig" ENUM  "No","Yes";
BA_DEF_ BO_  "NmAsrMessage" ENUM  "No","Yes";
BA_DEF_ SG_  "NeedsUpdateBit" ENUM  "No","Yes";
BA_DEF_ SG_  "MmAnSignal" ENUM  "No","Yes";
BA_DEF_ SG_  "GenSigMaxLatency" INT 0 65535;
BA_DEF_ SG_  "GenSigILSupport" ENUM  "Yes","No";
BA_DEF_ BO_  "GenMsgRequestable" INT 0 1;
BA_DEF_ BO_  "GenMsgILSupport" ENUM  "No","Yes";
BA_DEF_ BO_  "DiagUUDTResponse" ENUM  "No","Yes";
BA_DEF_ BO_  "DiagState" ENUM  "No","Yes";
BA_DEF_ BO_  "DiagResponse" ENUM  "No","Yes";
BA_DEF_ BO_  "DiagRequest" ENUM  "No","Yes";
BA_DEF_ BO_  "DiagConnection" HEX 0 65535;
BA_DEF_ BO_  "CanTpFcFrameId" HEX 0 2147483647;
BA_DEF_ BO_  "CanTpBs" INT 0 255;
BA_DEF_ SG_  "SystemSignalLongSymbol" STRING ;
BA_DEF_REL_ BU_SG_REL_  "GenSigTimeoutTime" INT 0 65535;
BA_DEF_REL_ BU_SG_REL_  "GenSigFirstTimeoutTime" INT 0 65535;
BA_DEF_DEF_  "GenMsgStartDelayTime" 0;
BA_DEF_DEF_  "GenMsgDelayTime" 0;
BA_DEF_DEF_  "GenMsgCycleTime" 0;
BA_DEF_DEF_  "GenMsgSendType" "Cyclic";
BA_DEF_DEF_  "GenSigStartValue" 0;
BA_DEF_DEF_  "GenSigInactiveValue" 0;
BA_DEF_DEF_  "GenSigCycleTimeActive" 0;
BA_DEF_DEF_  "GenSigCycleTime" 0;
BA_DEF_DEF_  "GenSigSendType" "Cyclic";
BA_DEF_DEF_  "VFrameFormat" "ExtendedCAN";
BA_DEF_DEF_  "SigType" "Default";
BA_DEF_DEF_  "SeToolVersion_SIGNAL" "";
BA_DEF_DEF_  "SeToolUniqueID_SIGNAL" "";
BA_DEF_DEF_  "SeToolName_SIGNAL" "";
BA_DEF_DEF_  "SeToolItemID_SIGNAL" "";
BA_DEF_DEF_  "SeToolAncestorID_SIGNAL" "";
BA_DEF_DEF_  "Platform_VMCU1_Sig" "No";
BA_DEF_DEF_  "NmAsrMessage" "No";
BA_DEF_DEF_  "NeedsUpdateBit" "No";
BA_DEF_DEF_  "MmAnSignal" "No";
BA_DEF_DEF_  "GenSigMaxLatency" 0;
BA_DEF_DEF_  "GenSigILSupport" "Yes";
BA_DEF_DEF_  "GenMsgRequestable" 1;
BA_DEF_DEF_  "GenMsgILSupport" "Yes";
BA_DEF_DEF_  "DiagUUDTResponse" "No";
BA_DEF_DEF_  "DiagState" "No";
BA_DEF_DEF_  "DiagResponse" "No";
BA_DEF_DEF_  "DiagRequest" "No";
BA_DEF_DEF_  "DiagConnection" 0;
BA_DEF_DEF_  "CanTpFcFrameId" 2147483647;
BA_DEF_DEF_  "CanTpBs" 255;
BA_DEF_DEF_REL_ "GenSigTimeoutTime" 0;
BA_DEF_DEF_REL_ "GenSigFirstTimeoutTime" 0;
BA_DEF_DEF_  "SystemSignalLongSymbol" "";
BA_ "VFrameFormat" BO_ 1934 0;
BA_ "GenMsgSendType" BO_ 1934 8;
BA_ "GenMsgDelayTime" BO_ 1934 50;
BA_ "GenMsgStartDelayTime" BO_ 1934 50;
BA_ "VFrameFormat" BO_ 1938 0;
BA_ "GenMsgSendType" BO_ 1938 8;
BA_ "GenMsgDelayTime" BO_ 1938 50;
BA_ "GenMsgStartDelayTime" BO_ 1938 50;
BA_ "VFrameFormat" BO_ 1939 0;
BA_ "GenMsgSendType" BO_ 1939 8;
BA_ "GenMsgDelayTime" BO_ 1939 50;
BA_ "VFrameFormat" BO_ 1933 0;
BA_ "GenMsgSendType" BO_ 1933 8;
BA_ "GenMsgDelayTime" BO_ 1933 50;
BA_ "GenMsgStartDelayTime" BO_ 1933 50;
BA_ "VFrameFormat" BO_ 1932 0;
BA_ "GenMsgSendType" BO_ 1932 8;
BA_ "VFrameFormat" BO_ 1936 0;
BA_ "GenMsgSendType" BO_ 1936 8;
BA_ "GenMsgDelayTime" BO_ 1936 50;
BA_ "GenMsgStartDelayTime" BO_ 1936 50;
BA_ "VFrameFormat" BO_ 1929 0;
BA_ "GenMsgSendType" BO_ 1929 8;
BA_ "GenMsgDelayTime" BO_ 1929 50;
BA_ "GenMsgStartDelayTime" BO_ 1929 50;
BA_ "VFrameFormat" BO_ 1927 0;
BA_ "GenMsgSendType" BO_ 1927 8;
BA_ "GenMsgDelayTime" BO_ 1927 50;
BA_ "GenMsgStartDelayTime" BO_ 1927 50;
BA_ "VFrameFormat" BO_ 1926 0;
BA_ "GenMsgSendType" BO_ 1926 8;
BA_ "GenMsgDelayTime" BO_ 1926 50;
BA_ "GenMsgStartDelayTime" BO_ 1926 50;
BA_ "VFrameFormat" BO_ 1930 0;
BA_ "GenMsgSendType" BO_ 1930 8;
BA_ "VFrameFormat" BO_ 1931 0;
BA_ "GenMsgSendType" BO_ 1931 8;
BA_ "GenMsgDelayTime" BO_ 1931 50;
BA_ "VFrameFormat" BO_ 1925 0;
BA_ "GenMsgSendType" BO_ 1925 8;
BA_ "GenMsgDelayTime" BO_ 1925 50;
BA_ "GenMsgStartDelayTime" BO_ 1925 50;
BA_ "VFrameFormat" BO_ 1924 0;
BA_ "GenMsgSendType" BO_ 1924 8;
BA_ "VFrameFormat" BO_ 1928 0;
BA_ "GenMsgSendType" BO_ 1928 8;
BA_ "GenMsgDelayTime" BO_ 1928 50;
BA_ "GenMsgStartDelayTime" BO_ 1928 50;
BA_ "VFrameFormat" BO_ 1921 0;
BA_ "GenMsgSendType" BO_ 1921 8;
BA_ "GenMsgDelayTime" BO_ 1921 50;
BA_ "GenMsgStartDelayTime" BO_ 1921 50;
BA_ "VFrameFormat" BO_ 1919 0;
BA_ "GenMsgSendType" BO_ 1919 8;
BA_ "GenMsgDelayTime" BO_ 1919 50;
BA_ "GenMsgStartDelayTime" BO_ 1919 50;
BA_ "VFrameFormat" BO_ 1918 0;
BA_ "GenMsgSendType" BO_ 1918 8;
BA_ "GenMsgDelayTime" BO_ 1918 50;
BA_ "GenMsgStartDelayTime" BO_ 1918 50;
BA_ "VFrameFormat" BO_ 1922 0;
BA_ "GenMsgSendType" BO_ 1922 8;
BA_ "VFrameFormat" BO_ 1923 0;
BA_ "GenMsgSendType" BO_ 1923 8;
BA_ "GenMsgDelayTime" BO_ 1923 50;
BA_ "VFrameFormat" BO_ 1917 0;
BA_ "GenMsgSendType" BO_ 1917 8;
BA_ "GenMsgDelayTime" BO_ 1917 50;
BA_ "GenMsgStartDelayTime" BO_ 1917 50;
BA_ "VFrameFormat" BO_ 1916 0;
BA_ "GenMsgSendType" BO_ 1916 8;
BA_ "VFrameFormat" BO_ 1920 0;
BA_ "GenMsgSendType" BO_ 1920 8;
BA_ "GenMsgDelayTime" BO_ 1920 50;
BA_ "GenMsgStartDelayTime" BO_ 1920 50;
BA_ "VFrameFormat" BO_ 1913 0;
BA_ "GenMsgSendType" BO_ 1913 8;
BA_ "GenMsgDelayTime" BO_ 1913 50;
BA_ "GenMsgStartDelayTime" BO_ 1913 50;
BA_ "VFrameFormat" BO_ 1911 0;
BA_ "GenMsgSendType" BO_ 1911 8;
BA_ "GenMsgDelayTime" BO_ 1911 10;
BA_ "GenMsgStartDelayTime" BO_ 1911 50;
BA_ "VFrameFormat" BO_ 1910 0;
BA_ "GenMsgSendType" BO_ 1910 8;
BA_ "GenMsgDelayTime" BO_ 1910 50;
BA_ "GenMsgStartDelayTime" BO_ 1910 50;
BA_ "VFrameFormat" BO_ 1914 0;
BA_ "GenMsgSendType" BO_ 1914 8;
BA_ "VFrameFormat" BO_ 1915 0;
BA_ "GenMsgSendType" BO_ 1915 8;
BA_ "GenMsgDelayTime" BO_ 1915 50;
BA_ "VFrameFormat" BO_ 1909 0;
BA_ "GenMsgSendType" BO_ 1909 8;
BA_ "GenMsgDelayTime" BO_ 1909 10;
BA_ "GenMsgStartDelayTime" BO_ 1909 50;
BA_ "VFrameFormat" BO_ 1908 0;
BA_ "GenMsgSendType" BO_ 1908 8;
BA_ "VFrameFormat" BO_ 1912 0;
BA_ "GenMsgSendType" BO_ 1912 8;
BA_ "GenMsgDelayTime" BO_ 1912 50;
BA_ "GenMsgStartDelayTime" BO_ 1912 50;
BA_ "VFrameFormat" BO_ 1905 0;
BA_ "GenMsgSendType" BO_ 1905 8;
BA_ "GenMsgDelayTime" BO_ 1905 50;
BA_ "GenMsgStartDelayTime" BO_ 1905 50;
BA_ "VFrameFormat" BO_ 1903 0;
BA_ "GenMsgSendType" BO_ 1903 8;
BA_ "GenMsgDelayTime" BO_ 1903 10;
BA_ "GenMsgStartDelayTime" BO_ 1903 50;
BA_ "VFrameFormat" BO_ 1902 0;
BA_ "GenMsgSendType" BO_ 1902 8;
BA_ "GenMsgDelayTime" BO_ 1902 50;
BA_ "GenMsgStartDelayTime" BO_ 1902 50;
BA_ "VFrameFormat" BO_ 1906 0;
BA_ "GenMsgSendType" BO_ 1906 8;
BA_ "VFrameFormat" BO_ 1907 0;
BA_ "GenMsgSendType" BO_ 1907 8;
BA_ "GenMsgDelayTime" BO_ 1907 50;
BA_ "VFrameFormat" BO_ 1901 0;
BA_ "GenMsgSendType" BO_ 1901 8;
BA_ "GenMsgDelayTime" BO_ 1901 10;
BA_ "GenMsgStartDelayTime" BO_ 1901 50;
BA_ "VFrameFormat" BO_ 1900 0;
BA_ "GenMsgSendType" BO_ 1900 8;
BA_ "VFrameFormat" BO_ 1904 0;
BA_ "GenMsgSendType" BO_ 1904 8;
BA_ "GenMsgDelayTime" BO_ 1904 50;
BA_ "GenMsgStartDelayTime" BO_ 1904 50;
BA_ "VFrameFormat" BO_ 1885 0;
BA_ "GenMsgSendType" BO_ 1885 8;
BA_ "GenMsgDelayTime" BO_ 1885 50;
BA_ "VFrameFormat" BO_ 1884 0;
BA_ "GenMsgSendType" BO_ 1884 8;
BA_ "GenMsgDelayTime" BO_ 1884 50;
BA_ "VFrameFormat" BO_ 1897 0;
BA_ "VFrameFormat" BO_ 1895 0;
BA_ "VFrameFormat" BO_ 1894 0;
BA_ "VFrameFormat" BO_ 1898 0;
BA_ "VFrameFormat" BO_ 1899 0;
BA_ "VFrameFormat" BO_ 1893 0;
BA_ "VFrameFormat" BO_ 1892 0;
BA_ "VFrameFormat" BO_ 1896 0;
BA_ "VFrameFormat" BO_ 1883 0;
BA_ "GenMsgSendType" BO_ 1883 8;
BA_ "GenMsgDelayTime" BO_ 1883 50;
BA_ "VFrameFormat" BO_ 1882 0;
BA_ "GenMsgSendType" BO_ 1882 8;
BA_ "GenMsgDelayTime" BO_ 1882 50;
BA_ "VFrameFormat" BO_ 1881 0;
BA_ "GenMsgSendType" BO_ 1881 8;
BA_ "GenMsgDelayTime" BO_ 1881 50;
BA_ "VFrameFormat" BO_ 1959 0;
BA_ "GenMsgSendType" BO_ 1959 8;
BA_ "VFrameFormat" BO_ 1880 0;
BA_ "GenMsgSendType" BO_ 1880 8;
BA_ "GenMsgDelayTime" BO_ 1880 50;
BA_ "VFrameFormat" BO_ 1891 0;
BA_ "GenMsgSendType" BO_ 1891 8;
BA_ "VFrameFormat" BO_ 1983 0;
BA_ "GenMsgSendType" BO_ 1983 8;
BA_ "GenMsgDelayTime" BO_ 1983 50;
BA_ "VFrameFormat" BO_ 1890 0;
BA_ "GenMsgSendType" BO_ 1890 8;
BA_ "VFrameFormat" BO_ 1982 0;
BA_ "GenMsgSendType" BO_ 1982 8;
BA_ "GenMsgDelayTime" BO_ 1982 50;
BA_ "VFrameFormat" BO_ 1889 0;
BA_ "GenMsgSendType" BO_ 1889 8;
BA_ "VFrameFormat" BO_ 1981 0;
BA_ "GenMsgSendType" BO_ 1981 8;
BA_ "GenMsgDelayTime" BO_ 1981 50;
BA_ "VFrameFormat" BO_ 1888 0;
BA_ "GenMsgSendType" BO_ 1888 8;
BA_ "VFrameFormat" BO_ 1963 0;
BA_ "GenMsgSendType" BO_ 1963 8;
BA_ "GenMsgDelayTime" BO_ 1963 10;
BA_ "GenMsgStartDelayTime" BO_ 1963 50;
BA_ "VFrameFormat" BO_ 1964 0;
BA_ "GenMsgSendType" BO_ 1964 8;
BA_ "GenMsgDelayTime" BO_ 1964 50;
BA_ "VFrameFormat" BO_ 1961 0;
BA_ "GenMsgSendType" BO_ 1961 8;
BA_ "GenMsgDelayTime" BO_ 1961 50;
BA_ "GenMsgStartDelayTime" BO_ 1961 50;
BA_ "VFrameFormat" BO_ 1887 0;
BA_ "GenMsgSendType" BO_ 1887 8;
BA_ "VFrameFormat" BO_ 1960 0;
BA_ "GenMsgSendType" BO_ 1960 8;
BA_ "GenMsgDelayTime" BO_ 1960 50;
BA_ "GenMsgStartDelayTime" BO_ 1960 50;
BA_ "VFrameFormat" BO_ 1962 0;
BA_ "GenMsgSendType" BO_ 1962 8;
BA_ "GenMsgDelayTime" BO_ 1962 50;
BA_ "GenMsgStartDelayTime" BO_ 1962 50;
BA_ "VFrameFormat" BO_ 1957 0;
BA_ "GenMsgSendType" BO_ 1957 8;
BA_ "GenMsgDelayTime" BO_ 1957 50;
BA_ "GenMsgStartDelayTime" BO_ 1957 50;
BA_ "VFrameFormat" BO_ 1886 0;
BA_ "GenMsgSendType" BO_ 1886 8;
BA_ "GenMsgStartDelayTime" BO_ 1886 50;
BA_ "VFrameFormat" BO_ 1956 0;
BA_ "GenMsgSendType" BO_ 1956 8;
BA_ "GenMsgDelayTime" BO_ 1956 50;
BA_ "GenMsgStartDelayTime" BO_ 1956 50;
BA_ "VFrameFormat" BO_ 1955 0;
BA_ "GenMsgSendType" BO_ 1955 8;
BA_ "VFrameFormat" BO_ 1958 0;
BA_ "GenMsgSendType" BO_ 1958 8;
BA_ "GenMsgDelayTime" BO_ 1958 50;
BA_ "GenMsgStartDelayTime" BO_ 1958 50;
BA_ "VFrameFormat" BO_ 2041 0;
BA_ "GenMsgSendType" BO_ 2041 8;
BA_ "GenMsgDelayTime" BO_ 2041 50;
BA_ "GenMsgStartDelayTime" BO_ 2041 50;
BA_ "VFrameFormat" BO_ 2047 0;
BA_ "VFrameFormat" BO_ 1251 0;
BA_ "GenMsgCycleTime" BO_ 1251 100;
BA_ "GenMsgStartDelayTime" BO_ 1251 40;
BA_ "VFrameFormat" BO_ 950 0;
BA_ "GenMsgCycleTime" BO_ 950 50;
BA_ "GenMsgStartDelayTime" BO_ 950 10;
BA_ "VFrameFormat" BO_ 1495 0;
BA_ "GenMsgCycleTime" BO_ 1495 2000;
BA_ "GenMsgStartDelayTime" BO_ 1495 345;
BA_ "VFrameFormat" BO_ 1242 0;
BA_ "GenMsgCycleTime" BO_ 1242 50;
BA_ "GenMsgStartDelayTime" BO_ 1242 25;
BA_ "VFrameFormat" BO_ 1510 0;
BA_ "GenMsgCycleTime" BO_ 1510 2000;
BA_ "GenMsgStartDelayTime" BO_ 1510 230;
BA_ "VFrameFormat" BO_ 1250 0;
BA_ "GenMsgCycleTime" BO_ 1250 100;
BA_ "GenMsgStartDelayTime" BO_ 1250 30;
BA_ "VFrameFormat" BO_ 823 0;
BA_ "GenMsgCycleTime" BO_ 823 30;
BA_ "VFrameFormat" BO_ 1244 0;
BA_ "GenMsgCycleTime" BO_ 1244 100;
BA_ "GenMsgStartDelayTime" BO_ 1244 10;
BA_ "VFrameFormat" BO_ 1238 0;
BA_ "GenMsgCycleTime" BO_ 1238 50;
BA_ "GenMsgStartDelayTime" BO_ 1238 15;
BA_ "VFrameFormat" BO_ 1237 0;
BA_ "GenMsgCycleTime" BO_ 1237 50;
BA_ "GenMsgStartDelayTime" BO_ 1237 5;
BA_ "VFrameFormat" BO_ 774 0;
BA_ "GenMsgCycleTime" BO_ 774 25;
BA_ "GenMsgStartDelayTime" BO_ 774 5;
BA_ "VFrameFormat" BO_ 1245 0;
BA_ "GenMsgCycleTime" BO_ 1245 100;
BA_ "GenMsgStartDelayTime" BO_ 1245 5;
BA_ "VFrameFormat" BO_ 1719 0;
BA_ "GenMsgCycleTime" BO_ 1719 100;
BA_ "VFrameFormat" BO_ 1718 0;
BA_ "GenMsgCycleTime" BO_ 1718 100;
BA_ "VFrameFormat" BO_ 1717 0;
BA_ "GenMsgCycleTime" BO_ 1717 100;
BA_ "VFrameFormat" BO_ 1716 0;
BA_ "GenMsgCycleTime" BO_ 1716 100;
BA_ "VFrameFormat" BO_ 1715 0;
BA_ "GenMsgCycleTime" BO_ 1715 100;
BA_ "VFrameFormat" BO_ 1721 0;
BA_ "GenMsgCycleTime" BO_ 1721 100;
BA_ "VFrameFormat" BO_ 1714 0;
BA_ "GenMsgCycleTime" BO_ 1714 100;
BA_ "GenMsgStartDelayTime" BO_ 1714 25;
BA_ "VFrameFormat" BO_ 1722 0;
BA_ "GenMsgCycleTime" BO_ 1722 100;
BA_ "GenMsgStartDelayTime" BO_ 1722 5;
BA_ "VFrameFormat" BO_ 1713 0;
BA_ "GenMsgCycleTime" BO_ 1713 100;
BA_ "VFrameFormat" BO_ 1720 0;
BA_ "GenMsgCycleTime" BO_ 1720 100;
BA_ "VFrameFormat" BO_ 1712 0;
BA_ "GenMsgCycleTime" BO_ 1712 100;
BA_ "VFrameFormat" BO_ 1246 0;
BA_ "GenMsgCycleTime" BO_ 1246 100;
BA_ "VFrameFormat" BO_ 1492 0;
BA_ "GenMsgCycleTime" BO_ 1492 2000;
BA_ "GenMsgILSupport" BO_ 1347 0;
BA_ "VFrameFormat" BO_ 1347 0;
BA_ "GenMsgSendType" BO_ 1347 8;
BA_ "CanTpFcFrameId" BO_ 1346 1347;
BA_ "VFrameFormat" BO_ 1346 0;
BA_ "GenMsgSendType" BO_ 1346 8;
BA_ "GenMsgDelayTime" BO_ 1346 75;
BA_ "VFrameFormat" BO_ 822 0;
BA_ "GenMsgCycleTime" BO_ 822 30;
BA_ "VFrameFormat" BO_ 1345 0;
BA_ "GenMsgCycleTime" BO_ 1345 250;
BA_ "GenMsgStartDelayTime" BO_ 1345 20;
BA_ "VFrameFormat" BO_ 949 0;
BA_ "GenMsgCycleTime" BO_ 949 50;
BA_ "GenMsgStartDelayTime" BO_ 949 10;
BA_ "GenSigSendType" SG_ 1934 Debug_6_FCIOM 1;
BA_ "GenSigMaxLatency" SG_ 1934 Debug_6_FCIOM 58;
BA_ "Platform_VMCU1_Sig" SG_ 1934 Debug_6_FCIOM 1;
BA_ "GenSigSendType" SG_ 1938 Debug_6_FAS 1;
BA_ "GenSigMaxLatency" SG_ 1938 Debug_6_FAS 59;
BA_ "Platform_VMCU1_Sig" SG_ 1938 Debug_6_FAS 1;
BA_ "GenSigSendType" SG_ 1939 Debug_6_EAS 1;
BA_ "Platform_VMCU1_Sig" SG_ 1939 Debug_6_EAS 1;
BA_ "GenSigSendType" SG_ 1933 Debug_6_CCIOM 1;
BA_ "GenSigMaxLatency" SG_ 1933 Debug_6_CCIOM 58;
BA_ "Platform_VMCU1_Sig" SG_ 1933 Debug_6_CCIOM 1;
BA_ "GenSigSendType" SG_ 1932 Debug_6_BPMU 1;
BA_ "Platform_VMCU1_Sig" SG_ 1932 Debug_6_BPMU 1;
BA_ "GenSigSendType" SG_ 1936 Debug_6_APM 1;
BA_ "GenSigMaxLatency" SG_ 1936 Debug_6_APM 58;
BA_ "Platform_VMCU1_Sig" SG_ 1936 Debug_6_APM 1;
BA_ "GenSigSendType" SG_ 1929 Debug_5_TPM 1;
BA_ "GenSigMaxLatency" SG_ 1929 Debug_5_TPM 59;
BA_ "Platform_VMCU1_Sig" SG_ 1929 Debug_5_TPM 1;
BA_ "GenSigSendType" SG_ 1927 Debug_5_RCIOM 1;
BA_ "GenSigMaxLatency" SG_ 1927 Debug_5_RCIOM 58;
BA_ "Platform_VMCU1_Sig" SG_ 1927 Debug_5_RCIOM 1;
BA_ "GenSigSendType" SG_ 1926 Debug_5_FCIOM 1;
BA_ "GenSigMaxLatency" SG_ 1926 Debug_5_FCIOM 58;
BA_ "Platform_VMCU1_Sig" SG_ 1926 Debug_5_FCIOM 1;
BA_ "GenSigSendType" SG_ 1930 Debug_5_FAS 1;
BA_ "GenSigMaxLatency" SG_ 1930 Debug_5_FAS 59;
BA_ "Platform_VMCU1_Sig" SG_ 1930 Debug_5_FAS 1;
BA_ "GenSigSendType" SG_ 1931 Debug_5_EAS 1;
BA_ "Platform_VMCU1_Sig" SG_ 1931 Debug_5_EAS 1;
BA_ "GenSigSendType" SG_ 1925 Debug_5_CCIOM 1;
BA_ "GenSigMaxLatency" SG_ 1925 Debug_5_CCIOM 58;
BA_ "Platform_VMCU1_Sig" SG_ 1925 Debug_5_CCIOM 1;
BA_ "GenSigSendType" SG_ 1924 Debug_5_BPMU 1;
BA_ "Platform_VMCU1_Sig" SG_ 1924 Debug_5_BPMU 1;
BA_ "GenSigSendType" SG_ 1928 Debug_5_APM 1;
BA_ "GenSigMaxLatency" SG_ 1928 Debug_5_APM 58;
BA_ "Platform_VMCU1_Sig" SG_ 1928 Debug_5_APM 1;
BA_ "GenSigSendType" SG_ 1921 Debug_4_TPM 1;
BA_ "GenSigMaxLatency" SG_ 1921 Debug_4_TPM 59;
BA_ "Platform_VMCU1_Sig" SG_ 1921 Debug_4_TPM 1;
BA_ "GenSigSendType" SG_ 1919 Debug_4_RCIOM 1;
BA_ "GenSigMaxLatency" SG_ 1919 Debug_4_RCIOM 58;
BA_ "Platform_VMCU1_Sig" SG_ 1919 Debug_4_RCIOM 1;
BA_ "GenSigSendType" SG_ 1918 Debug_4_FCIOM 1;
BA_ "GenSigMaxLatency" SG_ 1918 Debug_4_FCIOM 58;
BA_ "Platform_VMCU1_Sig" SG_ 1918 Debug_4_FCIOM 1;
BA_ "GenSigSendType" SG_ 1922 Debug_4_FAS 1;
BA_ "GenSigMaxLatency" SG_ 1922 Debug_4_FAS 59;
BA_ "Platform_VMCU1_Sig" SG_ 1922 Debug_4_FAS 1;
BA_ "GenSigSendType" SG_ 1923 Debug_4_EAS 1;
BA_ "Platform_VMCU1_Sig" SG_ 1923 Debug_4_EAS 1;
BA_ "GenSigSendType" SG_ 1917 Debug_4_CCIOM 1;
BA_ "GenSigMaxLatency" SG_ 1917 Debug_4_CCIOM 58;
BA_ "Platform_VMCU1_Sig" SG_ 1917 Debug_4_CCIOM 1;
BA_ "GenSigSendType" SG_ 1916 Debug_4_BPMU 1;
BA_ "Platform_VMCU1_Sig" SG_ 1916 Debug_4_BPMU 1;
BA_ "GenSigSendType" SG_ 1920 Debug_4_APM 1;
BA_ "GenSigMaxLatency" SG_ 1920 Debug_4_APM 58;
BA_ "Platform_VMCU1_Sig" SG_ 1920 Debug_4_APM 1;
BA_ "GenSigSendType" SG_ 1913 Debug_3_TPM 1;
BA_ "GenSigMaxLatency" SG_ 1913 Debug_3_TPM 59;
BA_ "Platform_VMCU1_Sig" SG_ 1913 Debug_3_TPM 1;
BA_ "GenSigSendType" SG_ 1911 Debug_3_RCIOM 1;
BA_ "GenSigMaxLatency" SG_ 1911 Debug_3_RCIOM 58;
BA_ "Platform_VMCU1_Sig" SG_ 1911 Debug_3_RCIOM 1;
BA_ "GenSigSendType" SG_ 1910 Debug_3_FCIOM 1;
BA_ "GenSigMaxLatency" SG_ 1910 Debug_3_FCIOM 58;
BA_ "Platform_VMCU1_Sig" SG_ 1910 Debug_3_FCIOM 1;
BA_ "GenSigSendType" SG_ 1914 Debug_3_FAS 1;
BA_ "GenSigMaxLatency" SG_ 1914 Debug_3_FAS 59;
BA_ "Platform_VMCU1_Sig" SG_ 1914 Debug_3_FAS 1;
BA_ "GenSigSendType" SG_ 1915 Debug_3_EAS 1;
BA_ "Platform_VMCU1_Sig" SG_ 1915 Debug_3_EAS 1;
BA_ "GenSigSendType" SG_ 1909 Debug_3_CCIOM 1;
BA_ "GenSigMaxLatency" SG_ 1909 Debug_3_CCIOM 58;
BA_ "Platform_VMCU1_Sig" SG_ 1909 Debug_3_CCIOM 1;
BA_ "GenSigSendType" SG_ 1908 Debug_3_BPMU 1;
BA_ "Platform_VMCU1_Sig" SG_ 1908 Debug_3_BPMU 1;
BA_ "GenSigSendType" SG_ 1912 Debug_3_APM 1;
BA_ "GenSigMaxLatency" SG_ 1912 Debug_3_APM 58;
BA_ "Platform_VMCU1_Sig" SG_ 1912 Debug_3_APM 1;
BA_ "GenSigSendType" SG_ 1905 Debug_2_TPM 1;
BA_ "GenSigMaxLatency" SG_ 1905 Debug_2_TPM 59;
BA_ "Platform_VMCU1_Sig" SG_ 1905 Debug_2_TPM 1;
BA_ "GenSigSendType" SG_ 1903 Debug_2_RCIOM 1;
BA_ "GenSigMaxLatency" SG_ 1903 Debug_2_RCIOM 58;
BA_ "Platform_VMCU1_Sig" SG_ 1903 Debug_2_RCIOM 1;
BA_ "GenSigSendType" SG_ 1902 Debug_2_FCIOM 1;
BA_ "GenSigMaxLatency" SG_ 1902 Debug_2_FCIOM 58;
BA_ "Platform_VMCU1_Sig" SG_ 1902 Debug_2_FCIOM 1;
BA_ "GenSigSendType" SG_ 1906 Debug_2_FAS 1;
BA_ "GenSigMaxLatency" SG_ 1906 Debug_2_FAS 59;
BA_ "Platform_VMCU1_Sig" SG_ 1906 Debug_2_FAS 1;
BA_ "GenSigSendType" SG_ 1907 Debug_2_EAS 1;
BA_ "Platform_VMCU1_Sig" SG_ 1907 Debug_2_EAS 1;
BA_ "GenSigSendType" SG_ 1901 Debug_2_CCIOM 1;
BA_ "GenSigMaxLatency" SG_ 1901 Debug_2_CCIOM 58;
BA_ "Platform_VMCU1_Sig" SG_ 1901 Debug_2_CCIOM 1;
BA_ "GenSigSendType" SG_ 1900 Debug_2_BPMU 1;
BA_ "Platform_VMCU1_Sig" SG_ 1900 Debug_2_BPMU 1;
BA_ "GenSigSendType" SG_ 1904 Debug_2_APM 1;
BA_ "GenSigMaxLatency" SG_ 1904 Debug_2_APM 58;
BA_ "Platform_VMCU1_Sig" SG_ 1904 Debug_2_APM 1;
BA_ "GenSigSendType" SG_ 1885 Debug_21_APM 1;
BA_ "Platform_VMCU1_Sig" SG_ 1885 Debug_21_APM 1;
BA_ "GenSigSendType" SG_ 1884 Debug_20_APM 1;
BA_ "Platform_VMCU1_Sig" SG_ 1884 Debug_20_APM 1;
BA_ "GenSigSendType" SG_ 1897 Debug_1_TPM 1;
BA_ "Platform_VMCU1_Sig" SG_ 1897 Debug_1_TPM 1;
BA_ "GenSigSendType" SG_ 1895 Debug_1_RCIOM 1;
BA_ "Platform_VMCU1_Sig" SG_ 1895 Debug_1_RCIOM 1;
BA_ "GenSigSendType" SG_ 1894 Debug_1_FCIOM 1;
BA_ "Platform_VMCU1_Sig" SG_ 1894 Debug_1_FCIOM 1;
BA_ "GenSigSendType" SG_ 1898 Debug_1_FAS 1;
BA_ "Platform_VMCU1_Sig" SG_ 1898 Debug_1_FAS 1;
BA_ "GenSigSendType" SG_ 1899 Debug_1_EAS 1;
BA_ "Platform_VMCU1_Sig" SG_ 1899 Debug_1_EAS 1;
BA_ "GenSigSendType" SG_ 1893 Debug_1_CCIOM 1;
BA_ "Platform_VMCU1_Sig" SG_ 1893 Debug_1_CCIOM 1;
BA_ "GenSigSendType" SG_ 1892 Debug_1_BPMU 1;
BA_ "Platform_VMCU1_Sig" SG_ 1892 Debug_1_BPMU 1;
BA_ "GenSigSendType" SG_ 1896 Debug_1_APM 1;
BA_ "Platform_VMCU1_Sig" SG_ 1896 Debug_1_APM 1;
BA_ "GenSigSendType" SG_ 1883 Debug_19_APM 1;
BA_ "Platform_VMCU1_Sig" SG_ 1883 Debug_19_APM 1;
BA_ "GenSigSendType" SG_ 1882 Debug_18_APM 1;
BA_ "Platform_VMCU1_Sig" SG_ 1882 Debug_18_APM 1;
BA_ "GenSigSendType" SG_ 1881 Debug_17_APM 1;
BA_ "Platform_VMCU1_Sig" SG_ 1881 Debug_17_APM 1;
BA_ "GenSigSendType" SG_ 1959 Debug_16_FAS 1;
BA_ "GenSigCycleTime" SG_ 1959 Debug_16_FAS 100;
BA_ "GenSigCycleTimeActive" SG_ 1959 Debug_16_FAS 100;
BA_ "Platform_VMCU1_Sig" SG_ 1959 Debug_16_FAS 1;
BA_ "GenSigSendType" SG_ 1880 Debug_16_APM 1;
BA_ "Platform_VMCU1_Sig" SG_ 1880 Debug_16_APM 1;
BA_ "GenSigSendType" SG_ 1891 Debug_15_FAS 1;
BA_ "GenSigCycleTime" SG_ 1891 Debug_15_FAS 100;
BA_ "GenSigCycleTimeActive" SG_ 1891 Debug_15_FAS 100;
BA_ "Platform_VMCU1_Sig" SG_ 1891 Debug_15_FAS 1;
BA_ "GenSigSendType" SG_ 1983 Debug_15_APM 1;
BA_ "Platform_VMCU1_Sig" SG_ 1983 Debug_15_APM 1;
BA_ "GenSigSendType" SG_ 1890 Debug_14_FAS 1;
BA_ "GenSigCycleTime" SG_ 1890 Debug_14_FAS 100;
BA_ "GenSigCycleTimeActive" SG_ 1890 Debug_14_FAS 100;
BA_ "Platform_VMCU1_Sig" SG_ 1890 Debug_14_FAS 1;
BA_ "GenSigSendType" SG_ 1982 Debug_14_APM 1;
BA_ "Platform_VMCU1_Sig" SG_ 1982 Debug_14_APM 1;
BA_ "GenSigSendType" SG_ 1889 Debug_13_FAS 1;
BA_ "GenSigCycleTime" SG_ 1889 Debug_13_FAS 100;
BA_ "GenSigCycleTimeActive" SG_ 1889 Debug_13_FAS 100;
BA_ "Platform_VMCU1_Sig" SG_ 1889 Debug_13_FAS 1;
BA_ "GenSigSendType" SG_ 1981 Debug_13_APM 1;
BA_ "Platform_VMCU1_Sig" SG_ 1981 Debug_13_APM 1;
BA_ "GenSigSendType" SG_ 1888 Debug_12_FAS 1;
BA_ "GenSigCycleTime" SG_ 1888 Debug_12_FAS 100;
BA_ "GenSigCycleTimeActive" SG_ 1888 Debug_12_FAS 100;
BA_ "Platform_VMCU1_Sig" SG_ 1888 Debug_12_FAS 1;
BA_ "GenSigSendType" SG_ 1963 Debug_12_CCIOM 1;
BA_ "GenSigMaxLatency" SG_ 1963 Debug_12_CCIOM 59;
BA_ "Platform_VMCU1_Sig" SG_ 1963 Debug_12_CCIOM 1;
BA_ "GenSigSendType" SG_ 1964 Debug_12_APM 1;
BA_ "Platform_VMCU1_Sig" SG_ 1964 Debug_12_APM 1;
BA_ "GenSigSendType" SG_ 1961 Debug_11_RCIOM 1;
BA_ "GenSigMaxLatency" SG_ 1961 Debug_11_RCIOM 59;
BA_ "Platform_VMCU1_Sig" SG_ 1961 Debug_11_RCIOM 1;
BA_ "GenSigSendType" SG_ 1887 Debug_11_FAS 1;
BA_ "GenSigCycleTime" SG_ 1887 Debug_11_FAS 100;
BA_ "GenSigCycleTimeActive" SG_ 1887 Debug_11_FAS 100;
BA_ "Platform_VMCU1_Sig" SG_ 1887 Debug_11_FAS 1;
BA_ "GenSigSendType" SG_ 1960 Debug_11_CCIOM 1;
BA_ "GenSigMaxLatency" SG_ 1960 Debug_11_CCIOM 59;
BA_ "Platform_VMCU1_Sig" SG_ 1960 Debug_11_CCIOM 1;
BA_ "GenSigSendType" SG_ 1962 Debug_11_APM 1;
BA_ "GenSigMaxLatency" SG_ 1962 Debug_11_APM 55;
BA_ "Platform_VMCU1_Sig" SG_ 1962 Debug_11_APM 1;
BA_ "GenSigSendType" SG_ 1957 Debug_10_RCIOM 1;
BA_ "GenSigMaxLatency" SG_ 1957 Debug_10_RCIOM 59;
BA_ "Platform_VMCU1_Sig" SG_ 1957 Debug_10_RCIOM 1;
BA_ "GenSigSendType" SG_ 1886 Debug_10_FAS 1;
BA_ "GenSigCycleTime" SG_ 1886 Debug_10_FAS 100;
BA_ "GenSigCycleTimeActive" SG_ 1886 Debug_10_FAS 100;
BA_ "Platform_VMCU1_Sig" SG_ 1886 Debug_10_FAS 1;
BA_ "GenSigSendType" SG_ 1956 Debug_10_CCIOM 1;
BA_ "GenSigMaxLatency" SG_ 1956 Debug_10_CCIOM 59;
BA_ "Platform_VMCU1_Sig" SG_ 1956 Debug_10_CCIOM 1;
BA_ "GenSigSendType" SG_ 1955 Debug_10_BPMU 1;
BA_ "Platform_VMCU1_Sig" SG_ 1955 Debug_10_BPMU 1;
BA_ "GenSigSendType" SG_ 1958 Debug_10_APM 1;
BA_ "GenSigMaxLatency" SG_ 1958 Debug_10_APM 55;
BA_ "Platform_VMCU1_Sig" SG_ 1958 Debug_10_APM 1;
BA_ "GenSigSendType" SG_ 2041 DSPTesterRespSig 1;
BA_ "GenSigCycleTimeActive" SG_ 2041 DSPTesterRespSig 100;
BA_ "Platform_VMCU1_Sig" SG_ 2041 DSPTesterRespSig 1;
BA_ "GenSigSendType" SG_ 2047 DSPTesterReqSig 1;
BA_ "GenSigCycleTime" SG_ 2047 DSPTesterReqSig 100;
BA_ "GenSigCycleTimeActive" SG_ 2047 DSPTesterReqSig 100;
BA_ "Platform_VMCU1_Sig" SG_ 2047 DSPTesterReqSig 1;
BA_ "GenSigCycleTime" SG_ 1251 LivBatteryCharging_stat_ISig_6 100;
BA_ "GenSigCycleTimeActive" SG_ 1251 LivBatteryCharging_stat_ISig_6 100;
BA_ "GenSigStartValue" SG_ 1251 LivBatteryCharging_stat_ISig_6 3;
BA_ "GenSigCycleTime" SG_ 1251 LivBatDisconnectDetectStat_ISig_ 100;
BA_ "GenSigCycleTimeActive" SG_ 1251 LivBatDisconnectDetectStat_ISig_ 100;
BA_ "GenSigStartValue" SG_ 1251 LivBatDisconnectDetectStat_ISig_ 3;
BA_ "SystemSignalLongSymbol" SG_ 1251 LivBatDisconnectDetectStat_ISig_ "LivBatDisconnectDetectStat_ISig_6";
BA_ "GenSigCycleTime" SG_ 1251 DiffLockInterWhlStatSplitBox2 100;
BA_ "GenSigCycleTimeActive" SG_ 1251 DiffLockInterWhlStatSplitBox2 100;
BA_ "GenSigStartValue" SG_ 1251 DiffLockInterWhlStatSplitBox2 3;
BA_ "Platform_VMCU1_Sig" SG_ 1251 DiffLockInterWhlStatSplitBox2 1;
BA_ "GenSigCycleTime" SG_ 1251 GearRangeUnengaged_ISig_6 100;
BA_ "GenSigCycleTimeActive" SG_ 1251 GearRangeUnengaged_ISig_6 100;
BA_ "GenSigStartValue" SG_ 1251 GearRangeUnengaged_ISig_6 3;
BA_ "Platform_VMCU1_Sig" SG_ 1251 GearRangeUnengaged_ISig_6 1;
BA_ "GenSigCycleTime" SG_ 1251 SideMarkersLight4_FailStat 100;
BA_ "GenSigCycleTimeActive" SG_ 1251 SideMarkersLight4_FailStat 100;
BA_ "GenSigStartValue" SG_ 1251 SideMarkersLight4_FailStat 7;
BA_ "Platform_VMCU1_Sig" SG_ 1251 SideMarkersLight4_FailStat 1;
BA_ "GenSigCycleTime" SG_ 1251 GChargerStatus_ISig_6 100;
BA_ "GenSigCycleTimeActive" SG_ 1251 GChargerStatus_ISig_6 100;
BA_ "GenSigStartValue" SG_ 1251 GChargerStatus_ISig_6 7;
BA_ "GenSigCycleTime" SG_ 1251 FrontOffsetLampCalib 100;
BA_ "GenSigCycleTimeActive" SG_ 1251 FrontOffsetLampCalib 100;
BA_ "GenSigStartValue" SG_ 1251 FrontOffsetLampCalib 65535;
BA_ "Platform_VMCU1_Sig" SG_ 1251 FrontOffsetLampCalib 1;
BA_ "GenSigCycleTime" SG_ 1251 CCIOM_LowVMPBInfoReq 100;
BA_ "GenSigCycleTimeActive" SG_ 1251 CCIOM_LowVMPBInfoReq 100;
BA_ "GenSigStartValue" SG_ 1251 CCIOM_LowVMPBInfoReq 7;
BA_ "Platform_VMCU1_Sig" SG_ 1251 CCIOM_LowVMPBInfoReq 1;
BA_ "GenSigCycleTime" SG_ 1251 DiffLockInterWhlStatusFrAxle2 100;
BA_ "GenSigCycleTimeActive" SG_ 1251 DiffLockInterWhlStatusFrAxle2 100;
BA_ "GenSigStartValue" SG_ 1251 DiffLockInterWhlStatusFrAxle2 3;
BA_ "Platform_VMCU1_Sig" SG_ 1251 DiffLockInterWhlStatusFrAxle2 1;
BA_ "GenSigCycleTime" SG_ 1251 BatterySensorVoltage 100;
BA_ "GenSigCycleTimeActive" SG_ 1251 BatterySensorVoltage 100;
BA_ "GenSigStartValue" SG_ 1251 BatterySensorVoltage 511;
BA_ "GenSigCycleTime" SG_ 950 CCIOM_AirCompressorStatus 100;
BA_ "GenSigCycleTimeActive" SG_ 950 CCIOM_AirCompressorStatus 100;
BA_ "GenSigStartValue" SG_ 950 CCIOM_AirCompressorStatus 3;
BA_ "Platform_VMCU1_Sig" SG_ 950 CCIOM_AirCompressorStatus 1;
BA_ "GenSigCycleTime" SG_ 950 CCIOM_ServiceBrakeAirPCircuit2 100;
BA_ "GenSigCycleTimeActive" SG_ 950 CCIOM_ServiceBrakeAirPCircuit2 100;
BA_ "GenSigStartValue" SG_ 950 CCIOM_ServiceBrakeAirPCircuit2 255;
BA_ "Platform_VMCU1_Sig" SG_ 950 CCIOM_ServiceBrakeAirPCircuit2 1;
BA_ "GenSigCycleTime" SG_ 950 CCIOM_AirDryerCoolFanSpd_rqst 100;
BA_ "GenSigCycleTimeActive" SG_ 950 CCIOM_AirDryerCoolFanSpd_rqst 100;
BA_ "GenSigStartValue" SG_ 950 CCIOM_AirDryerCoolFanSpd_rqst 65535;
BA_ "NeedsUpdateBit" SG_ 950 CCIOM_AirDryerCoolFanSpd_rqst 1;
BA_ "Platform_VMCU1_Sig" SG_ 950 CCIOM_AirDryerCoolFanSpd_rqst 1;
BA_ "GenSigCycleTime" SG_ 950 CCIOM_PoorAirPressureInfo 100;
BA_ "GenSigCycleTimeActive" SG_ 950 CCIOM_PoorAirPressureInfo 100;
BA_ "GenSigStartValue" SG_ 950 CCIOM_PoorAirPressureInfo 3;
BA_ "NeedsUpdateBit" SG_ 950 CCIOM_PoorAirPressureInfo 1;
BA_ "Platform_VMCU1_Sig" SG_ 950 CCIOM_PoorAirPressureInfo 1;
BA_ "GenSigSendType" SG_ 950 CCIOM_ParkingBrake_stat_UB 7;
BA_ "GenSigCycleTime" SG_ 950 CCIOM_ParkingBrake_stat_UB 100;
BA_ "GenSigCycleTimeActive" SG_ 950 CCIOM_ParkingBrake_stat_UB 100;
BA_ "Platform_VMCU1_Sig" SG_ 950 CCIOM_ParkingBrake_stat_UB 1;
BA_ "GenSigCycleTime" SG_ 950 CCIOM_AirDryerCtrReset_ack 100;
BA_ "GenSigCycleTimeActive" SG_ 950 CCIOM_AirDryerCtrReset_ack 100;
BA_ "GenSigStartValue" SG_ 950 CCIOM_AirDryerCtrReset_ack 3;
BA_ "Platform_VMCU1_Sig" SG_ 950 CCIOM_AirDryerCtrReset_ack 1;
BA_ "GenSigSendType" SG_ 950 CCIOM_AirDryerCoolFanSpd_rqst_UB 7;
BA_ "GenSigCycleTime" SG_ 950 CCIOM_AirDryerCoolFanSpd_rqst_UB 100;
BA_ "GenSigCycleTimeActive" SG_ 950 CCIOM_AirDryerCoolFanSpd_rqst_UB 100;
BA_ "Platform_VMCU1_Sig" SG_ 950 CCIOM_AirDryerCoolFanSpd_rqst_UB 1;
BA_ "GenSigCycleTime" SG_ 950 CCIOM_LowAirPressureAlert 100;
BA_ "GenSigCycleTimeActive" SG_ 950 CCIOM_LowAirPressureAlert 100;
BA_ "GenSigStartValue" SG_ 950 CCIOM_LowAirPressureAlert 3;
BA_ "Platform_VMCU1_Sig" SG_ 950 CCIOM_LowAirPressureAlert 1;
BA_ "GenSigCycleTime" SG_ 950 CCIOM_ServiceBrakeAirPCircuit1 100;
BA_ "GenSigCycleTimeActive" SG_ 950 CCIOM_ServiceBrakeAirPCircuit1 100;
BA_ "GenSigStartValue" SG_ 950 CCIOM_ServiceBrakeAirPCircuit1 255;
BA_ "Platform_VMCU1_Sig" SG_ 950 CCIOM_ServiceBrakeAirPCircuit1 1;
BA_ "GenSigCycleTime" SG_ 950 CCIOM_OverrunMode_stat 100;
BA_ "GenSigCycleTimeActive" SG_ 950 CCIOM_OverrunMode_stat 100;
BA_ "GenSigStartValue" SG_ 950 CCIOM_OverrunMode_stat 3;
BA_ "Platform_VMCU1_Sig" SG_ 950 CCIOM_OverrunMode_stat 1;
BA_ "GenSigCycleTime" SG_ 950 CCIOM_ParkingBrake_stat 100;
BA_ "GenSigCycleTimeActive" SG_ 950 CCIOM_ParkingBrake_stat 100;
BA_ "GenSigStartValue" SG_ 950 CCIOM_ParkingBrake_stat 3;
BA_ "NeedsUpdateBit" SG_ 950 CCIOM_ParkingBrake_stat 1;
BA_ "Platform_VMCU1_Sig" SG_ 950 CCIOM_ParkingBrake_stat 1;
BA_ "GenSigCycleTime" SG_ 950 CCIOM_ParkBrakeApplicationMode 100;
BA_ "GenSigCycleTimeActive" SG_ 950 CCIOM_ParkBrakeApplicationMode 100;
BA_ "GenSigStartValue" SG_ 950 CCIOM_ParkBrakeApplicationMode 7;
BA_ "Platform_VMCU1_Sig" SG_ 950 CCIOM_ParkBrakeApplicationMode 1;
BA_ "GenSigCycleTime" SG_ 950 CCIOM_ParkBrakeAlert_ISig_6 100;
BA_ "GenSigCycleTimeActive" SG_ 950 CCIOM_ParkBrakeAlert_ISig_6 100;
BA_ "GenSigStartValue" SG_ 950 CCIOM_ParkBrakeAlert_ISig_6 3;
BA_ "Platform_VMCU1_Sig" SG_ 950 CCIOM_ParkBrakeAlert_ISig_6 1;
BA_ "GenSigSendType" SG_ 950 CCIOM_PoorAirPressureInfo_UB 7;
BA_ "GenSigCycleTime" SG_ 950 CCIOM_PoorAirPressureInfo_UB 100;
BA_ "GenSigCycleTimeActive" SG_ 950 CCIOM_PoorAirPressureInfo_UB 100;
BA_ "Platform_VMCU1_Sig" SG_ 950 CCIOM_PoorAirPressureInfo_UB 1;
BA_ "GenSigCycleTime" SG_ 950 CCIOM_ParkBrakeActuationStatus 100;
BA_ "GenSigCycleTimeActive" SG_ 950 CCIOM_ParkBrakeActuationStatus 100;
BA_ "GenSigStartValue" SG_ 950 CCIOM_ParkBrakeActuationStatus 7;
BA_ "NeedsUpdateBit" SG_ 950 CCIOM_ParkBrakeActuationStatus 1;
BA_ "Platform_VMCU1_Sig" SG_ 950 CCIOM_ParkBrakeActuationStatus 1;
BA_ "GenSigSendType" SG_ 950 CCIOM_ParkBrakeActuationStatus_U 7;
BA_ "GenSigCycleTime" SG_ 950 CCIOM_ParkBrakeActuationStatus_U 100;
BA_ "GenSigCycleTimeActive" SG_ 950 CCIOM_ParkBrakeActuationStatus_U 100;
BA_ "Platform_VMCU1_Sig" SG_ 950 CCIOM_ParkBrakeActuationStatus_U 1;
BA_ "SystemSignalLongSymbol" SG_ 950 CCIOM_ParkBrakeActuationStatus_U "CCIOM_ParkBrakeActuationStatus_UB";
BA_ "GenSigCycleTime" SG_ 1495 CCIOM_AirCtrMileagePrediction 100;
BA_ "GenSigCycleTimeActive" SG_ 1495 CCIOM_AirCtrMileagePrediction 100;
BA_ "GenSigStartValue" SG_ 1495 CCIOM_AirCtrMileagePrediction 4294967295;
BA_ "Platform_VMCU1_Sig" SG_ 1495 CCIOM_AirCtrMileagePrediction 1;
BA_ "GenSigCycleTime" SG_ 1495 CCIOM_AirCtrWearingPercentage 100;
BA_ "GenSigCycleTimeActive" SG_ 1495 CCIOM_AirCtrWearingPercentage 100;
BA_ "GenSigStartValue" SG_ 1495 CCIOM_AirCtrWearingPercentage 255;
BA_ "Platform_VMCU1_Sig" SG_ 1495 CCIOM_AirCtrWearingPercentage 1;
BA_ "GenSigCycleTime" SG_ 1242 BatterySOCactCriticalAlert_ISig_ 100;
BA_ "GenSigCycleTimeActive" SG_ 1242 BatterySOCactCriticalAlert_ISig_ 100;
BA_ "GenSigStartValue" SG_ 1242 BatterySOCactCriticalAlert_ISig_ 255;
BA_ "Platform_VMCU1_Sig" SG_ 1242 BatterySOCactCriticalAlert_ISig_ 1;
BA_ "SystemSignalLongSymbol" SG_ 1242 BatterySOCactCriticalAlert_ISig_ "BatterySOCactCriticalAlert_ISig_6";
BA_ "GenSigCycleTime" SG_ 1242 BatteryTemp_ISig_6 100;
BA_ "GenSigCycleTimeActive" SG_ 1242 BatteryTemp_ISig_6 100;
BA_ "GenSigStartValue" SG_ 1242 BatteryTemp_ISig_6 255;
BA_ "Platform_VMCU1_Sig" SG_ 1242 BatteryTemp_ISig_6 1;
BA_ "GenSigCycleTime" SG_ 1242 BatteryTempAlert_rqst_ISig_6 100;
BA_ "GenSigCycleTimeActive" SG_ 1242 BatteryTempAlert_rqst_ISig_6 100;
BA_ "GenSigStartValue" SG_ 1242 BatteryTempAlert_rqst_ISig_6 7;
BA_ "Platform_VMCU1_Sig" SG_ 1242 BatteryTempAlert_rqst_ISig_6 1;
BA_ "GenSigCycleTime" SG_ 1242 BatteryTempAlertRawData_rqst_ISi 100;
BA_ "GenSigCycleTimeActive" SG_ 1242 BatteryTempAlertRawData_rqst_ISi 100;
BA_ "GenSigStartValue" SG_ 1242 BatteryTempAlertRawData_rqst_ISi 7;
BA_ "Platform_VMCU1_Sig" SG_ 1242 BatteryTempAlertRawData_rqst_ISi 1;
BA_ "SystemSignalLongSymbol" SG_ 1242 BatteryTempAlertRawData_rqst_ISi "BatteryTempAlertRawData_rqst_ISig_6";
BA_ "GenSigCycleTime" SG_ 1242 BatterySOCact_ISig_6 100;
BA_ "GenSigCycleTimeActive" SG_ 1242 BatterySOCact_ISig_6 100;
BA_ "GenSigStartValue" SG_ 1242 BatterySOCact_ISig_6 255;
BA_ "Platform_VMCU1_Sig" SG_ 1242 BatterySOCact_ISig_6 1;
BA_ "GenSigCycleTime" SG_ 1242 RelativeLevelFrontAxleLeftRaw 100;
BA_ "GenSigCycleTimeActive" SG_ 1242 RelativeLevelFrontAxleLeftRaw 100;
BA_ "GenSigStartValue" SG_ 1242 RelativeLevelFrontAxleLeftRaw 65535;
BA_ "Platform_VMCU1_Sig" SG_ 1242 RelativeLevelFrontAxleLeftRaw 1;
BA_ "GenSigCycleTime" SG_ 1242 RelativeLevelFrontAxleRightRaw 100;
BA_ "GenSigCycleTimeActive" SG_ 1242 RelativeLevelFrontAxleRightRaw 100;
BA_ "GenSigStartValue" SG_ 1242 RelativeLevelFrontAxleRightRaw 65535;
BA_ "Platform_VMCU1_Sig" SG_ 1242 RelativeLevelFrontAxleRightRaw 1;
BA_ "GenSigCycleTime" SG_ 1510 ECSFrontCRC_CRC 100;
BA_ "GenSigCycleTimeActive" SG_ 1510 ECSFrontCRC_CRC 100;
BA_ "GenSigStartValue" SG_ 1510 ECSFrontCRC_CRC 65535;
BA_ "Platform_VMCU1_Sig" SG_ 1510 ECSFrontCRC_CRC 1;
BA_ "GenSigCycleTime" SG_ 1510 WantedLBChargingVoltage 100;
BA_ "GenSigCycleTimeActive" SG_ 1510 WantedLBChargingVoltage 100;
BA_ "GenSigStartValue" SG_ 1510 WantedLBChargingVoltage 65535;
BA_ "Platform_VMCU1_Sig" SG_ 1510 WantedLBChargingVoltage 1;
BA_ "GenSigCycleTime" SG_ 1510 ECSFrontCRC_Status 100;
BA_ "GenSigCycleTimeActive" SG_ 1510 ECSFrontCRC_Status 100;
BA_ "GenSigStartValue" SG_ 1510 ECSFrontCRC_Status 3;
BA_ "Platform_VMCU1_Sig" SG_ 1510 ECSFrontCRC_Status 1;
BA_ "GenSigCycleTime" SG_ 1250 BatterySOHTrustLevel 100;
BA_ "GenSigCycleTimeActive" SG_ 1250 BatterySOHTrustLevel 100;
BA_ "GenSigStartValue" SG_ 1250 BatterySOHTrustLevel 255;
BA_ "GenSigMaxLatency" SG_ 1250 BatterySOHTrustLevel 35;
BA_ "Platform_VMCU1_Sig" SG_ 1250 BatterySOHTrustLevel 1;
BA_ "SeToolAncestorID_SIGNAL" SG_ 1250 BatterySOHTrustLevel "x0000001D04387DD4";
BA_ "SeToolItemID_SIGNAL" SG_ 1250 BatterySOHTrustLevel "x0000001D04387DD4";
BA_ "SeToolName_SIGNAL" SG_ 1250 BatterySOHTrustLevel "BatterySOHTrustLevel";
BA_ "SeToolVersion_SIGNAL" SG_ 1250 BatterySOHTrustLevel "1";
BA_ "GenSigCycleTime" SG_ 1250 BatterySOH_ISig_6 100;
BA_ "GenSigCycleTimeActive" SG_ 1250 BatterySOH_ISig_6 100;
BA_ "GenSigStartValue" SG_ 1250 BatterySOH_ISig_6 255;
BA_ "GenSigMaxLatency" SG_ 1250 BatterySOH_ISig_6 35;
BA_ "Platform_VMCU1_Sig" SG_ 1250 BatterySOH_ISig_6 1;
BA_ "SeToolAncestorID_SIGNAL" SG_ 1250 BatterySOH_ISig_6 "x0000001D041491DF";
BA_ "SeToolItemID_SIGNAL" SG_ 1250 BatterySOH_ISig_6 "x0000001D041491DF";
BA_ "SeToolName_SIGNAL" SG_ 1250 BatterySOH_ISig_6 "BatterySOH";
BA_ "SeToolVersion_SIGNAL" SG_ 1250 BatterySOH_ISig_6 "1";
BA_ "GenSigCycleTime" SG_ 1250 BatteryVoltageDisplayValue_ISig_ 100;
BA_ "GenSigCycleTimeActive" SG_ 1250 BatteryVoltageDisplayValue_ISig_ 100;
BA_ "GenSigStartValue" SG_ 1250 BatteryVoltageDisplayValue_ISig_ 65535;
BA_ "GenSigMaxLatency" SG_ 1250 BatteryVoltageDisplayValue_ISig_ 35;
BA_ "Platform_VMCU1_Sig" SG_ 1250 BatteryVoltageDisplayValue_ISig_ 1;
BA_ "SystemSignalLongSymbol" SG_ 1250 BatteryVoltageDisplayValue_ISig_ "BatteryVoltageDisplayValue_ISig_6";
BA_ "GenSigCycleTime" SG_ 1250 BatterySOF 100;
BA_ "GenSigCycleTimeActive" SG_ 1250 BatterySOF 100;
BA_ "GenSigStartValue" SG_ 1250 BatterySOF 255;
BA_ "Platform_VMCU1_Sig" SG_ 1250 BatterySOF 1;
BA_ "GenSigCycleTime" SG_ 1250 BatteryCurrent_ISig_6 100;
BA_ "GenSigCycleTimeActive" SG_ 1250 BatteryCurrent_ISig_6 100;
BA_ "GenSigStartValue" SG_ 1250 BatteryCurrent_ISig_6 65535;
BA_ "GenSigMaxLatency" SG_ 1250 BatteryCurrent_ISig_6 35;
BA_ "Platform_VMCU1_Sig" SG_ 1250 BatteryCurrent_ISig_6 1;
BA_ "SeToolAncestorID_SIGNAL" SG_ 1250 BatteryCurrent_ISig_6 "x0000001D041491E4";
BA_ "SeToolItemID_SIGNAL" SG_ 1250 BatteryCurrent_ISig_6 "x0000001D042E2456";
BA_ "SeToolName_SIGNAL" SG_ 1250 BatteryCurrent_ISig_6 "BatteryCurrent";
BA_ "SeToolVersion_SIGNAL" SG_ 1250 BatteryCurrent_ISig_6 "2";
BA_ "GenSigCycleTime" SG_ 1250 BatterySOCnom_ISig_6 100;
BA_ "GenSigCycleTimeActive" SG_ 1250 BatterySOCnom_ISig_6 100;
BA_ "GenSigStartValue" SG_ 1250 BatterySOCnom_ISig_6 255;
BA_ "GenSigMaxLatency" SG_ 1250 BatterySOCnom_ISig_6 35;
BA_ "Platform_VMCU1_Sig" SG_ 1250 BatterySOCnom_ISig_6 1;
BA_ "SeToolAncestorID_SIGNAL" SG_ 1250 BatterySOCnom_ISig_6 "x0000001D0431FB91";
BA_ "SeToolItemID_SIGNAL" SG_ 1250 BatterySOCnom_ISig_6 "x0000001D0431FB91";
BA_ "SeToolName_SIGNAL" SG_ 1250 BatterySOCnom_ISig_6 "BatterySOCnom";
BA_ "SeToolVersion_SIGNAL" SG_ 1250 BatterySOCnom_ISig_6 "1";
BA_ "GenSigCycleTime" SG_ 823 FifthWheelLockingInformation_ISi 100;
BA_ "GenSigCycleTimeActive" SG_ 823 FifthWheelLockingInformation_ISi 100;
BA_ "GenSigStartValue" SG_ 823 FifthWheelLockingInformation_ISi 15;
BA_ "GenSigMaxLatency" SG_ 823 FifthWheelLockingInformation_ISi 35;
BA_ "NeedsUpdateBit" SG_ 823 FifthWheelLockingInformation_ISi 1;
BA_ "Platform_VMCU1_Sig" SG_ 823 FifthWheelLockingInformation_ISi 1;
BA_ "SystemSignalLongSymbol" SG_ 823 FifthWheelLockingInformation_ISi "FifthWheelLockingInformation_ISig_6";
BA_ "GenSigCycleTime" SG_ 823 DoubleFrontAxleSteeringWarning_I 100;
BA_ "GenSigCycleTimeActive" SG_ 823 DoubleFrontAxleSteeringWarning_I 100;
BA_ "GenSigStartValue" SG_ 823 DoubleFrontAxleSteeringWarning_I 3;
BA_ "SystemSignalLongSymbol" SG_ 823 DoubleFrontAxleSteeringWarning_I "DoubleFrontAxleSteeringWarning_ISig_6";
BA_ "GenSigCycleTime" SG_ 823 DifferentialLockStateFrAxle1_ISi 100;
BA_ "GenSigCycleTimeActive" SG_ 823 DifferentialLockStateFrAxle1_ISi 100;
BA_ "GenSigStartValue" SG_ 823 DifferentialLockStateFrAxle1_ISi 3;
BA_ "GenSigMaxLatency" SG_ 823 DifferentialLockStateFrAxle1_ISi 35;
BA_ "NeedsUpdateBit" SG_ 823 DifferentialLockStateFrAxle1_ISi 1;
BA_ "Platform_VMCU1_Sig" SG_ 823 DifferentialLockStateFrAxle1_ISi 1;
BA_ "SystemSignalLongSymbol" SG_ 823 DifferentialLockStateFrAxle1_ISi "DifferentialLockStateFrAxle1_ISig_6";
BA_ "GenSigSendType" SG_ 823 ElectricalLoadReduction_rqst_UB_ 7;
BA_ "Platform_VMCU1_Sig" SG_ 823 ElectricalLoadReduction_rqst_UB_ 1;
BA_ "SystemSignalLongSymbol" SG_ 823 ElectricalLoadReduction_rqst_UB_ "ElectricalLoadReduction_rqst_UB_ISig_6";
BA_ "GenSigCycleTime" SG_ 823 DirInd_MiddleSide_Status 100;
BA_ "GenSigCycleTimeActive" SG_ 823 DirInd_MiddleSide_Status 100;
BA_ "GenSigStartValue" SG_ 823 DirInd_MiddleSide_Status 7;
BA_ "Platform_VMCU1_Sig" SG_ 823 DirInd_MiddleSide_Status 1;
BA_ "GenSigCycleTime" SG_ 823 ExtendedTrailerBrakeValveStat 100;
BA_ "GenSigCycleTimeActive" SG_ 823 ExtendedTrailerBrakeValveStat 100;
BA_ "GenSigStartValue" SG_ 823 ExtendedTrailerBrakeValveStat 3;
BA_ "GenSigSendType" SG_ 823 DifferentialLockStateFrAxle1_UB_ 7;
BA_ "Platform_VMCU1_Sig" SG_ 823 DifferentialLockStateFrAxle1_UB_ 1;
BA_ "SystemSignalLongSymbol" SG_ 823 DifferentialLockStateFrAxle1_UB_ "DifferentialLockStateFrAxle1_UB_ISig_6";
BA_ "GenSigCycleTime" SG_ 823 TransmLowRangeSenseSwitch_ISig_6 100;
BA_ "GenSigCycleTimeActive" SG_ 823 TransmLowRangeSenseSwitch_ISig_6 100;
BA_ "GenSigStartValue" SG_ 823 TransmLowRangeSenseSwitch_ISig_6 3;
BA_ "GenSigMaxLatency" SG_ 823 TransmLowRangeSenseSwitch_ISig_6 35;
BA_ "Platform_VMCU1_Sig" SG_ 823 TransmLowRangeSenseSwitch_ISig_6 1;
BA_ "GenSigCycleTime" SG_ 823 ElectricalLoadReduction_rqst_ISi 100;
BA_ "GenSigCycleTimeActive" SG_ 823 ElectricalLoadReduction_rqst_ISi 100;
BA_ "GenSigInactiveValue" SG_ 823 ElectricalLoadReduction_rqst_ISi 7;
BA_ "GenSigStartValue" SG_ 823 ElectricalLoadReduction_rqst_ISi 7;
BA_ "GenSigMaxLatency" SG_ 823 ElectricalLoadReduction_rqst_ISi 35;
BA_ "NeedsUpdateBit" SG_ 823 ElectricalLoadReduction_rqst_ISi 1;
BA_ "Platform_VMCU1_Sig" SG_ 823 ElectricalLoadReduction_rqst_ISi 1;
BA_ "SystemSignalLongSymbol" SG_ 823 ElectricalLoadReduction_rqst_ISi "ElectricalLoadReduction_rqst_ISig_6";
BA_ "GenSigCycleTime" SG_ 823 WrknLghtChassisOutpFalr_stat 100;
BA_ "GenSigCycleTimeActive" SG_ 823 WrknLghtChassisOutpFalr_stat 100;
BA_ "GenSigInactiveValue" SG_ 823 WrknLghtChassisOutpFalr_stat 7;
BA_ "GenSigStartValue" SG_ 823 WrknLghtChassisOutpFalr_stat 7;
BA_ "GenSigMaxLatency" SG_ 823 WrknLghtChassisOutpFalr_stat 35;
BA_ "Platform_VMCU1_Sig" SG_ 823 WrknLghtChassisOutpFalr_stat 1;
BA_ "GenSigCycleTime" SG_ 823 ManTransmiOilTemp_ISig_6 100;
BA_ "GenSigCycleTimeActive" SG_ 823 ManTransmiOilTemp_ISig_6 100;
BA_ "GenSigStartValue" SG_ 823 ManTransmiOilTemp_ISig_6 65535;
BA_ "GenSigMaxLatency" SG_ 823 ManTransmiOilTemp_ISig_6 35;
BA_ "NeedsUpdateBit" SG_ 823 ManTransmiOilTemp_ISig_6 1;
BA_ "Platform_VMCU1_Sig" SG_ 823 ManTransmiOilTemp_ISig_6 1;
BA_ "GenSigCycleTime" SG_ 823 LoadCutOffIndication_cmd_ISig_6 100;
BA_ "GenSigCycleTimeActive" SG_ 823 LoadCutOffIndication_cmd_ISig_6 100;
BA_ "GenSigStartValue" SG_ 823 LoadCutOffIndication_cmd_ISig_6 3;
BA_ "GenSigMaxLatency" SG_ 823 LoadCutOffIndication_cmd_ISig_6 35;
BA_ "Platform_VMCU1_Sig" SG_ 823 LoadCutOffIndication_cmd_ISig_6 1;
BA_ "GenSigCycleTime" SG_ 823 TransmReverseDirectionSw_stat_IS 100;
BA_ "GenSigCycleTimeActive" SG_ 823 TransmReverseDirectionSw_stat_IS 100;
BA_ "GenSigStartValue" SG_ 823 TransmReverseDirectionSw_stat_IS 3;
BA_ "Platform_VMCU1_Sig" SG_ 823 TransmReverseDirectionSw_stat_IS 1;
BA_ "SystemSignalLongSymbol" SG_ 823 TransmReverseDirectionSw_stat_IS "TransmReverseDirectionSw_stat_ISig_6";
BA_ "GenSigCycleTime" SG_ 823 BatterySOCAlert_rqst_ISig_6 100;
BA_ "GenSigCycleTimeActive" SG_ 823 BatterySOCAlert_rqst_ISig_6 100;
BA_ "GenSigStartValue" SG_ 823 BatterySOCAlert_rqst_ISig_6 7;
BA_ "GenSigMaxLatency" SG_ 823 BatterySOCAlert_rqst_ISig_6 35;
BA_ "Platform_VMCU1_Sig" SG_ 823 BatterySOCAlert_rqst_ISig_6 1;
BA_ "GenSigSendType" SG_ 823 GearSplit_Status_UB_ISig_6 7;
BA_ "Platform_VMCU1_Sig" SG_ 823 GearSplit_Status_UB_ISig_6 1;
BA_ "GenSigCycleTime" SG_ 823 BatteryCapacity_Ack 100;
BA_ "GenSigCycleTimeActive" SG_ 823 BatteryCapacity_Ack 100;
BA_ "GenSigStartValue" SG_ 823 BatteryCapacity_Ack 3;
BA_ "GenSigMaxLatency" SG_ 823 BatteryCapacity_Ack 35;
BA_ "Platform_VMCU1_Sig" SG_ 823 BatteryCapacity_Ack 1;
BA_ "GenSigSendType" SG_ 823 ManTransmiOilTemp_UB_ISig_6 7;
BA_ "Platform_VMCU1_Sig" SG_ 823 ManTransmiOilTemp_UB_ISig_6 1;
BA_ "GenSigCycleTime" SG_ 823 FrontLimpHomeTrigger 100;
BA_ "GenSigCycleTimeActive" SG_ 823 FrontLimpHomeTrigger 100;
BA_ "GenSigStartValue" SG_ 823 FrontLimpHomeTrigger 7;
BA_ "GenSigMaxLatency" SG_ 823 FrontLimpHomeTrigger 35;
BA_ "Platform_VMCU1_Sig" SG_ 823 FrontLimpHomeTrigger 1;
BA_ "GenSigSendType" SG_ 823 FifthWheelLockingInformation_UB_ 7;
BA_ "Platform_VMCU1_Sig" SG_ 823 FifthWheelLockingInformation_UB_ 1;
BA_ "SystemSignalLongSymbol" SG_ 823 FifthWheelLockingInformation_UB_ "FifthWheelLockingInformation_UB_ISig_6";
BA_ "GenSigCycleTime" SG_ 823 GearSplit_Status_ISig_6 100;
BA_ "GenSigCycleTimeActive" SG_ 823 GearSplit_Status_ISig_6 100;
BA_ "GenSigStartValue" SG_ 823 GearSplit_Status_ISig_6 3;
BA_ "GenSigMaxLatency" SG_ 823 GearSplit_Status_ISig_6 35;
BA_ "NeedsUpdateBit" SG_ 823 GearSplit_Status_ISig_6 1;
BA_ "Platform_VMCU1_Sig" SG_ 823 GearSplit_Status_ISig_6 1;
BA_ "GenSigCycleTime" SG_ 823 DiffLockInterWhlStatusSplitBox_I 100;
BA_ "GenSigCycleTimeActive" SG_ 823 DiffLockInterWhlStatusSplitBox_I 100;
BA_ "GenSigStartValue" SG_ 823 DiffLockInterWhlStatusSplitBox_I 3;
BA_ "Platform_VMCU1_Sig" SG_ 823 DiffLockInterWhlStatusSplitBox_I 1;
BA_ "SystemSignalLongSymbol" SG_ 823 DiffLockInterWhlStatusSplitBox_I "DiffLockInterWhlStatusSplitBox_ISig_6";
BA_ "GenSigCycleTime" SG_ 823 FifthWheelHandleLock_ind 100;
BA_ "GenSigCycleTimeActive" SG_ 823 FifthWheelHandleLock_ind 100;
BA_ "GenSigStartValue" SG_ 823 FifthWheelHandleLock_ind 3;
BA_ "Platform_VMCU1_Sig" SG_ 823 FifthWheelHandleLock_ind 1;
BA_ "GenSigCycleTime" SG_ 823 DifferentialLockStateCentral_ISi 100;
BA_ "GenSigCycleTimeActive" SG_ 823 DifferentialLockStateCentral_ISi 100;
BA_ "GenSigStartValue" SG_ 823 DifferentialLockStateCentral_ISi 3;
BA_ "GenSigMaxLatency" SG_ 823 DifferentialLockStateCentral_ISi 35;
BA_ "Platform_VMCU1_Sig" SG_ 823 DifferentialLockStateCentral_ISi 1;
BA_ "SystemSignalLongSymbol" SG_ 823 DifferentialLockStateCentral_ISi "DifferentialLockStateCentral_ISig_6";
BA_ "GenSigSendType" SG_ 1244 FrontAxle2Load_UB_ISig_6 7;
BA_ "Platform_VMCU1_Sig" SG_ 1244 FrontAxle2Load_UB_ISig_6 1;
BA_ "GenSigCycleTime" SG_ 1244 TrailerBrakePres_stat 100;
BA_ "GenSigCycleTimeActive" SG_ 1244 TrailerBrakePres_stat 100;
BA_ "GenSigStartValue" SG_ 1244 TrailerBrakePres_stat 3;
BA_ "Platform_VMCU1_Sig" SG_ 1244 TrailerBrakePres_stat 1;
BA_ "GenSigCycleTime" SG_ 1244 ExtraBBContUnlockFeedback 100;
BA_ "GenSigCycleTimeActive" SG_ 1244 ExtraBBContUnlockFeedback 100;
BA_ "GenSigStartValue" SG_ 1244 ExtraBBContUnlockFeedback 3;
BA_ "Platform_VMCU1_Sig" SG_ 1244 ExtraBBContUnlockFeedback 1;
BA_ "GenSigCycleTime" SG_ 1244 FrontAxle1Load_ISig_6 100;
BA_ "GenSigCycleTimeActive" SG_ 1244 FrontAxle1Load_ISig_6 100;
BA_ "GenSigStartValue" SG_ 1244 FrontAxle1Load_ISig_6 65535;
BA_ "GenSigMaxLatency" SG_ 1244 FrontAxle1Load_ISig_6 255;
BA_ "NeedsUpdateBit" SG_ 1244 FrontAxle1Load_ISig_6 1;
BA_ "Platform_VMCU1_Sig" SG_ 1244 FrontAxle1Load_ISig_6 1;
BA_ "SeToolAncestorID_SIGNAL" SG_ 1244 FrontAxle1Load_ISig_6 "x0000001D0412EB1E";
BA_ "SeToolItemID_SIGNAL" SG_ 1244 FrontAxle1Load_ISig_6 "x0000001D04274C69";
BA_ "SeToolName_SIGNAL" SG_ 1244 FrontAxle1Load_ISig_6 "FrontAxle1Load";
BA_ "SeToolVersion_SIGNAL" SG_ 1244 FrontAxle1Load_ISig_6 "3";
BA_ "GenSigCycleTime" SG_ 1244 ExtraBBSlidable5WFeedback 100;
BA_ "GenSigCycleTimeActive" SG_ 1244 ExtraBBSlidable5WFeedback 100;
BA_ "GenSigStartValue" SG_ 1244 ExtraBBSlidable5WFeedback 3;
BA_ "Platform_VMCU1_Sig" SG_ 1244 ExtraBBSlidable5WFeedback 1;
BA_ "GenSigCycleTime" SG_ 1244 FrontAxleGrpBellowTorque 100;
BA_ "GenSigCycleTimeActive" SG_ 1244 FrontAxleGrpBellowTorque 100;
BA_ "GenSigStartValue" SG_ 1244 FrontAxleGrpBellowTorque 65535;
BA_ "Platform_VMCU1_Sig" SG_ 1244 FrontAxleGrpBellowTorque 1;
BA_ "GenSigCycleTime" SG_ 1244 TrailerRevAndFogOutput_stat_ISig 100;
BA_ "GenSigCycleTimeActive" SG_ 1244 TrailerRevAndFogOutput_stat_ISig 100;
BA_ "GenSigStartValue" SG_ 1244 TrailerRevAndFogOutput_stat_ISig 3;
BA_ "Platform_VMCU1_Sig" SG_ 1244 TrailerRevAndFogOutput_stat_ISig 1;
BA_ "SystemSignalLongSymbol" SG_ 1244 TrailerRevAndFogOutput_stat_ISig "TrailerRevAndFogOutput_stat_ISig_6";
BA_ "GenSigCycleTime" SG_ 1244 ShortStopHeater_status_ISig_6 100;
BA_ "GenSigCycleTimeActive" SG_ 1244 ShortStopHeater_status_ISig_6 100;
BA_ "GenSigStartValue" SG_ 1244 ShortStopHeater_status_ISig_6 7;
BA_ "Platform_VMCU1_Sig" SG_ 1244 ShortStopHeater_status_ISig_6 1;
BA_ "GenSigSendType" SG_ 1244 FrontAxle1Load_UB_ISig_6 7;
BA_ "Platform_VMCU1_Sig" SG_ 1244 FrontAxle1Load_UB_ISig_6 1;
BA_ "GenSigCycleTime" SG_ 1244 FrontAxle2Load_ISig_6 100;
BA_ "GenSigCycleTimeActive" SG_ 1244 FrontAxle2Load_ISig_6 100;
BA_ "GenSigStartValue" SG_ 1244 FrontAxle2Load_ISig_6 65535;
BA_ "GenSigMaxLatency" SG_ 1244 FrontAxle2Load_ISig_6 255;
BA_ "NeedsUpdateBit" SG_ 1244 FrontAxle2Load_ISig_6 1;
BA_ "Platform_VMCU1_Sig" SG_ 1244 FrontAxle2Load_ISig_6 1;
BA_ "SeToolAncestorID_SIGNAL" SG_ 1244 FrontAxle2Load_ISig_6 "x0000001D0412EB1E";
BA_ "SeToolItemID_SIGNAL" SG_ 1244 FrontAxle2Load_ISig_6 "x0000001D04274C69";
BA_ "SeToolName_SIGNAL" SG_ 1244 FrontAxle2Load_ISig_6 "FrontAxle2Load";
BA_ "SeToolVersion_SIGNAL" SG_ 1244 FrontAxle2Load_ISig_6 "3";
BA_ "GenSigCycleTime" SG_ 1238 FrontAxleGroupLoad_ISig_6 100;
BA_ "GenSigCycleTimeActive" SG_ 1238 FrontAxleGroupLoad_ISig_6 100;
BA_ "GenSigStartValue" SG_ 1238 FrontAxleGroupLoad_ISig_6 65535;
BA_ "GenSigMaxLatency" SG_ 1238 FrontAxleGroupLoad_ISig_6 108;
BA_ "Platform_VMCU1_Sig" SG_ 1238 FrontAxleGroupLoad_ISig_6 1;
BA_ "SeToolAncestorID_SIGNAL" SG_ 1238 FrontAxleGroupLoad_ISig_6 "x0000001D04343A74";
BA_ "SeToolItemID_SIGNAL" SG_ 1238 FrontAxleGroupLoad_ISig_6 "x0000001D04343A74";
BA_ "SeToolName_SIGNAL" SG_ 1238 FrontAxleGroupLoad_ISig_6 "FrontAxleGroupLoad";
BA_ "SeToolVersion_SIGNAL" SG_ 1238 FrontAxleGroupLoad_ISig_6 "1";
BA_ "GenSigCycleTime" SG_ 1238 FrontStabilizerSpringRate 100;
BA_ "GenSigCycleTimeActive" SG_ 1238 FrontStabilizerSpringRate 100;
BA_ "GenSigStartValue" SG_ 1238 FrontStabilizerSpringRate 65535;
BA_ "GenSigMaxLatency" SG_ 1238 FrontStabilizerSpringRate 108;
BA_ "Platform_VMCU1_Sig" SG_ 1238 FrontStabilizerSpringRate 1;
BA_ "SeToolAncestorID_SIGNAL" SG_ 1238 FrontStabilizerSpringRate "x0000001D0433A493";
BA_ "SeToolItemID_SIGNAL" SG_ 1238 FrontStabilizerSpringRate "x0000001D0433A493";
BA_ "SeToolName_SIGNAL" SG_ 1238 FrontStabilizerSpringRate "FrontStabilizerSpringRate";
BA_ "SeToolVersion_SIGNAL" SG_ 1238 FrontStabilizerSpringRate "1";
BA_ "GenSigCycleTime" SG_ 1238 RelativeLevelFrontAxleLeft_ISig_ 100;
BA_ "GenSigCycleTimeActive" SG_ 1238 RelativeLevelFrontAxleLeft_ISig_ 100;
BA_ "GenSigStartValue" SG_ 1238 RelativeLevelFrontAxleLeft_ISig_ 65535;
BA_ "GenSigMaxLatency" SG_ 1238 RelativeLevelFrontAxleLeft_ISig_ 108;
BA_ "Platform_VMCU1_Sig" SG_ 1238 RelativeLevelFrontAxleLeft_ISig_ 1;
BA_ "SeToolAncestorID_SIGNAL" SG_ 1238 RelativeLevelFrontAxleLeft_ISig_ "x0000001D0412EE39";
BA_ "SeToolItemID_SIGNAL" SG_ 1238 RelativeLevelFrontAxleLeft_ISig_ "x0000001D04384DFD";
BA_ "SeToolName_SIGNAL" SG_ 1238 RelativeLevelFrontAxleLeft_ISig_ "RelativeLevelFrontAxleLeft";
BA_ "SeToolVersion_SIGNAL" SG_ 1238 RelativeLevelFrontAxleLeft_ISig_ "2";
BA_ "SystemSignalLongSymbol" SG_ 1238 RelativeLevelFrontAxleLeft_ISig_ "RelativeLevelFrontAxleLeft_ISig_6";
BA_ "GenSigCycleTime" SG_ 1238 RelativeLevelFrontAxleRight_ISig 100;
BA_ "GenSigCycleTimeActive" SG_ 1238 RelativeLevelFrontAxleRight_ISig 100;
BA_ "GenSigStartValue" SG_ 1238 RelativeLevelFrontAxleRight_ISig 65535;
BA_ "GenSigMaxLatency" SG_ 1238 RelativeLevelFrontAxleRight_ISig 108;
BA_ "Platform_VMCU1_Sig" SG_ 1238 RelativeLevelFrontAxleRight_ISig 1;
BA_ "SeToolAncestorID_SIGNAL" SG_ 1238 RelativeLevelFrontAxleRight_ISig "x0000001D0412EE3C";
BA_ "SeToolItemID_SIGNAL" SG_ 1238 RelativeLevelFrontAxleRight_ISig "x0000001D04384E33";
BA_ "SeToolName_SIGNAL" SG_ 1238 RelativeLevelFrontAxleRight_ISig "RelativeLevelFrontAxleRight";
BA_ "SeToolVersion_SIGNAL" SG_ 1238 RelativeLevelFrontAxleRight_ISig "2";
BA_ "SystemSignalLongSymbol" SG_ 1238 RelativeLevelFrontAxleRight_ISig "RelativeLevelFrontAxleRight_ISig_6";
BA_ "GenSigCycleTime" SG_ 1237 TotalFrBellowTrqMaxCapacity 100;
BA_ "GenSigCycleTimeActive" SG_ 1237 TotalFrBellowTrqMaxCapacity 100;
BA_ "GenSigStartValue" SG_ 1237 TotalFrBellowTrqMaxCapacity 65535;
BA_ "GenSigMaxLatency" SG_ 1237 TotalFrBellowTrqMaxCapacity 107;
BA_ "Platform_VMCU1_Sig" SG_ 1237 TotalFrBellowTrqMaxCapacity 1;
BA_ "SeToolAncestorID_SIGNAL" SG_ 1237 TotalFrBellowTrqMaxCapacity "x0000001D0414B288";
BA_ "SeToolItemID_SIGNAL" SG_ 1237 TotalFrBellowTrqMaxCapacity "x0000001D04384364";
BA_ "SeToolName_SIGNAL" SG_ 1237 TotalFrBellowTrqMaxCapacity "TotalFrontBellowTorqueMaxCapacity";
BA_ "SeToolVersion_SIGNAL" SG_ 1237 TotalFrBellowTrqMaxCapacity "2";
BA_ "GenSigCycleTime" SG_ 1237 BatterySOCTrustLevel_ISig_6 100;
BA_ "GenSigCycleTimeActive" SG_ 1237 BatterySOCTrustLevel_ISig_6 100;
BA_ "GenSigStartValue" SG_ 1237 BatterySOCTrustLevel_ISig_6 255;
BA_ "Platform_VMCU1_Sig" SG_ 1237 BatterySOCTrustLevel_ISig_6 1;
BA_ "GenSigCycleTime" SG_ 1237 FrontAxleGrpUsedTorqueRef 100;
BA_ "GenSigCycleTimeActive" SG_ 1237 FrontAxleGrpUsedTorqueRef 100;
BA_ "GenSigStartValue" SG_ 1237 FrontAxleGrpUsedTorqueRef 65535;
BA_ "Platform_VMCU1_Sig" SG_ 1237 FrontAxleGrpUsedTorqueRef 1;
BA_ "GenSigCycleTime" SG_ 1237 BatterySOCAlertRawData_rqst_ISig 100;
BA_ "GenSigCycleTimeActive" SG_ 1237 BatterySOCAlertRawData_rqst_ISig 100;
BA_ "GenSigStartValue" SG_ 1237 BatterySOCAlertRawData_rqst_ISig 7;
BA_ "Platform_VMCU1_Sig" SG_ 1237 BatterySOCAlertRawData_rqst_ISig 1;
BA_ "SystemSignalLongSymbol" SG_ 1237 BatterySOCAlertRawData_rqst_ISig "BatterySOCAlertRawData_rqst_ISig_6";
BA_ "GenSigCycleTime" SG_ 1237 TotalFrontLoadTorque 100;
BA_ "GenSigCycleTimeActive" SG_ 1237 TotalFrontLoadTorque 100;
BA_ "GenSigStartValue" SG_ 1237 TotalFrontLoadTorque 65535;
BA_ "GenSigMaxLatency" SG_ 1237 TotalFrontLoadTorque 107;
BA_ "Platform_VMCU1_Sig" SG_ 1237 TotalFrontLoadTorque 1;
BA_ "SeToolAncestorID_SIGNAL" SG_ 1237 TotalFrontLoadTorque "x0000001D0414B288";
BA_ "SeToolItemID_SIGNAL" SG_ 1237 TotalFrontLoadTorque "x0000001D04384364";
BA_ "SeToolName_SIGNAL" SG_ 1237 TotalFrontLoadTorque "TotalFrontLoadTorque";
BA_ "SeToolVersion_SIGNAL" SG_ 1237 TotalFrontLoadTorque "2";
BA_ "GenSigCycleTime" SG_ 774 FuelVolume_ISig_6 100;
BA_ "GenSigCycleTimeActive" SG_ 774 FuelVolume_ISig_6 100;
BA_ "GenSigStartValue" SG_ 774 FuelVolume_ISig_6 2047;
BA_ "NeedsUpdateBit" SG_ 774 FuelVolume_ISig_6 1;
BA_ "Platform_VMCU1_Sig" SG_ 774 FuelVolume_ISig_6 1;
BA_ "GenSigSendType" SG_ 774 FuelVolume_UB_ISig_6 7;
BA_ "Platform_VMCU1_Sig" SG_ 774 FuelVolume_UB_ISig_6 1;
BA_ "GenSigCycleTime" SG_ 774 MainSwitch_Status 100;
BA_ "GenSigCycleTimeActive" SG_ 774 MainSwitch_Status 100;
BA_ "GenSigStartValue" SG_ 774 MainSwitch_Status 3;
BA_ "GenSigMaxLatency" SG_ 774 MainSwitch_Status 27;
BA_ "Platform_VMCU1_Sig" SG_ 774 MainSwitch_Status 1;
BA_ "SeToolAncestorID_SIGNAL" SG_ 774 MainSwitch_Status "x0000001D04407911";
BA_ "SeToolItemID_SIGNAL" SG_ 774 MainSwitch_Status "x0000001D04407911";
BA_ "SeToolName_SIGNAL" SG_ 774 MainSwitch_Status "MainSwitch_Status";
BA_ "SeToolVersion_SIGNAL" SG_ 774 MainSwitch_Status "1";
BA_ "GenSigCycleTime" SG_ 774 Pto1FeedbackStatus_ISig_6 100;
BA_ "GenSigCycleTimeActive" SG_ 774 Pto1FeedbackStatus_ISig_6 100;
BA_ "GenSigStartValue" SG_ 774 Pto1FeedbackStatus_ISig_6 3;
BA_ "GenSigMaxLatency" SG_ 774 Pto1FeedbackStatus_ISig_6 27;
BA_ "NeedsUpdateBit" SG_ 774 Pto1FeedbackStatus_ISig_6 1;
BA_ "Platform_VMCU1_Sig" SG_ 774 Pto1FeedbackStatus_ISig_6 1;
BA_ "SeToolAncestorID_SIGNAL" SG_ 774 Pto1FeedbackStatus_ISig_6 "x0000001D041538D8";
BA_ "SeToolItemID_SIGNAL" SG_ 774 Pto1FeedbackStatus_ISig_6 "x0000001D041538D8";
BA_ "SeToolName_SIGNAL" SG_ 774 Pto1FeedbackStatus_ISig_6 "Pto1FeedbackStatus";
BA_ "SeToolVersion_SIGNAL" SG_ 774 Pto1FeedbackStatus_ISig_6 "1";
BA_ "GenSigCycleTime" SG_ 774 SWBrakeSwitch2 100;
BA_ "GenSigCycleTimeActive" SG_ 774 SWBrakeSwitch2 100;
BA_ "GenSigStartValue" SG_ 774 SWBrakeSwitch2 3;
BA_ "Platform_VMCU1_Sig" SG_ 774 SWBrakeSwitch2 1;
BA_ "GenSigSendType" SG_ 774 ReverseGearEngaged_UB_ISig_6 7;
BA_ "Platform_VMCU1_Sig" SG_ 774 ReverseGearEngaged_UB_ISig_6 1;
BA_ "GenSigCycleTime" SG_ 774 ReverseGearEngaged_ISig_6 100;
BA_ "GenSigCycleTimeActive" SG_ 774 ReverseGearEngaged_ISig_6 100;
BA_ "GenSigStartValue" SG_ 774 ReverseGearEngaged_ISig_6 3;
BA_ "GenSigMaxLatency" SG_ 774 ReverseGearEngaged_ISig_6 27;
BA_ "NeedsUpdateBit" SG_ 774 ReverseGearEngaged_ISig_6 1;
BA_ "Platform_VMCU1_Sig" SG_ 774 ReverseGearEngaged_ISig_6 1;
BA_ "SeToolAncestorID_SIGNAL" SG_ 774 ReverseGearEngaged_ISig_6 "x0000001D0413A2F1";
BA_ "SeToolItemID_SIGNAL" SG_ 774 ReverseGearEngaged_ISig_6 "x0000001D0413A2F1";
BA_ "SeToolName_SIGNAL" SG_ 774 ReverseGearEngaged_ISig_6 "ReverseGearEngaged";
BA_ "SeToolVersion_SIGNAL" SG_ 774 ReverseGearEngaged_ISig_6 "1";
BA_ "GenSigSendType" SG_ 774 TransmissionNeutralSwitch_UB_ISi 7;
BA_ "Platform_VMCU1_Sig" SG_ 774 TransmissionNeutralSwitch_UB_ISi 1;
BA_ "SystemSignalLongSymbol" SG_ 774 TransmissionNeutralSwitch_UB_ISi "TransmissionNeutralSwitch_UB_ISig_6";
BA_ "GenSigCycleTime" SG_ 774 SecuredNeutralPosition_ISig_6 100;
BA_ "GenSigCycleTimeActive" SG_ 774 SecuredNeutralPosition_ISig_6 100;
BA_ "GenSigStartValue" SG_ 774 SecuredNeutralPosition_ISig_6 3;
BA_ "GenSigMaxLatency" SG_ 774 SecuredNeutralPosition_ISig_6 27;
BA_ "NeedsUpdateBit" SG_ 774 SecuredNeutralPosition_ISig_6 1;
BA_ "Platform_VMCU1_Sig" SG_ 774 SecuredNeutralPosition_ISig_6 1;
BA_ "SeToolAncestorID_SIGNAL" SG_ 774 SecuredNeutralPosition_ISig_6 "x0000001D04127A25";
BA_ "SeToolItemID_SIGNAL" SG_ 774 SecuredNeutralPosition_ISig_6 "x0000001D043C813E";
BA_ "SeToolName_SIGNAL" SG_ 774 SecuredNeutralPosition_ISig_6 "SecuredNeutralPosition";
BA_ "SeToolVersion_SIGNAL" SG_ 774 SecuredNeutralPosition_ISig_6 "2";
BA_ "GenSigSendType" SG_ 774 SecuredNeutralPosition_UB_ISig_6 7;
BA_ "Platform_VMCU1_Sig" SG_ 774 SecuredNeutralPosition_UB_ISig_6 1;
BA_ "GenSigCycleTime" SG_ 774 FuelLevel_ISig_6 100;
BA_ "GenSigCycleTimeActive" SG_ 774 FuelLevel_ISig_6 100;
BA_ "GenSigStartValue" SG_ 774 FuelLevel_ISig_6 255;
BA_ "GenSigMaxLatency" SG_ 774 FuelLevel_ISig_6 27;
BA_ "NeedsUpdateBit" SG_ 774 FuelLevel_ISig_6 1;
BA_ "Platform_VMCU1_Sig" SG_ 774 FuelLevel_ISig_6 1;
BA_ "SeToolAncestorID_SIGNAL" SG_ 774 FuelLevel_ISig_6 "x0000001D0416974D";
BA_ "SeToolItemID_SIGNAL" SG_ 774 FuelLevel_ISig_6 "x0000001D0416974D";
BA_ "SeToolName_SIGNAL" SG_ 774 FuelLevel_ISig_6 "FuelLevel";
BA_ "SeToolVersion_SIGNAL" SG_ 774 FuelLevel_ISig_6 "1";
BA_ "GenSigSendType" SG_ 774 FuelLevel_UB_ISig_6 7;
BA_ "Platform_VMCU1_Sig" SG_ 774 FuelLevel_UB_ISig_6 1;
BA_ "GenSigCycleTime" SG_ 774 TransmSecuredForCrank_stat 100;
BA_ "GenSigCycleTimeActive" SG_ 774 TransmSecuredForCrank_stat 100;
BA_ "GenSigStartValue" SG_ 774 TransmSecuredForCrank_stat 3;
BA_ "GenSigMaxLatency" SG_ 774 TransmSecuredForCrank_stat 27;
BA_ "Platform_VMCU1_Sig" SG_ 774 TransmSecuredForCrank_stat 1;
BA_ "SeToolAncestorID_SIGNAL" SG_ 774 TransmSecuredForCrank_stat "x0000001D041F4F32";
BA_ "SeToolItemID_SIGNAL" SG_ 774 TransmSecuredForCrank_stat "x0000001D041F4F32";
BA_ "SeToolName_SIGNAL" SG_ 774 TransmSecuredForCrank_stat "TransmissionSecuredForCrank_stat";
BA_ "SeToolVersion_SIGNAL" SG_ 774 TransmSecuredForCrank_stat "1";
BA_ "GenSigCycleTime" SG_ 774 FrontTargetLevelReached 100;
BA_ "GenSigCycleTimeActive" SG_ 774 FrontTargetLevelReached 100;
BA_ "GenSigStartValue" SG_ 774 FrontTargetLevelReached 3;
BA_ "GenSigMaxLatency" SG_ 774 FrontTargetLevelReached 27;
BA_ "Platform_VMCU1_Sig" SG_ 774 FrontTargetLevelReached 1;
BA_ "SeToolAncestorID_SIGNAL" SG_ 774 FrontTargetLevelReached "x0000001D04344C6D";
BA_ "SeToolItemID_SIGNAL" SG_ 774 FrontTargetLevelReached "x0000001D04344C6D";
BA_ "SeToolName_SIGNAL" SG_ 774 FrontTargetLevelReached "FrontTargetLevelReached";
BA_ "SeToolVersion_SIGNAL" SG_ 774 FrontTargetLevelReached "1";
BA_ "GenSigSendType" SG_ 774 Pto1FeedbackStatus_UB_ISig_6 7;
BA_ "Platform_VMCU1_Sig" SG_ 774 Pto1FeedbackStatus_UB_ISig_6 1;
BA_ "GenSigCycleTime" SG_ 774 TransmissionNeutralSwitch_ISig_6 100;
BA_ "GenSigCycleTimeActive" SG_ 774 TransmissionNeutralSwitch_ISig_6 100;
BA_ "GenSigStartValue" SG_ 774 TransmissionNeutralSwitch_ISig_6 3;
BA_ "GenSigMaxLatency" SG_ 774 TransmissionNeutralSwitch_ISig_6 27;
BA_ "NeedsUpdateBit" SG_ 774 TransmissionNeutralSwitch_ISig_6 1;
BA_ "Platform_VMCU1_Sig" SG_ 774 TransmissionNeutralSwitch_ISig_6 1;
BA_ "SeToolAncestorID_SIGNAL" SG_ 774 TransmissionNeutralSwitch_ISig_6 "x0000001D0412E2B6";
BA_ "SeToolItemID_SIGNAL" SG_ 774 TransmissionNeutralSwitch_ISig_6 "x0000001D042FD0C5";
BA_ "SeToolName_SIGNAL" SG_ 774 TransmissionNeutralSwitch_ISig_6 "TransmissionNeutralSwitch";
BA_ "SeToolVersion_SIGNAL" SG_ 774 TransmissionNeutralSwitch_ISig_6 "2";
BA_ "GenSigCycleTime" SG_ 774 BrakePressureSensorDemand2 100;
BA_ "GenSigCycleTimeActive" SG_ 774 BrakePressureSensorDemand2 100;
BA_ "GenSigStartValue" SG_ 774 BrakePressureSensorDemand2 255;
BA_ "Platform_VMCU1_Sig" SG_ 774 BrakePressureSensorDemand2 1;
BA_ "GenSigCycleTime" SG_ 1245 StartBatterySOH 100;
BA_ "GenSigCycleTimeActive" SG_ 1245 StartBatterySOH 100;
BA_ "GenSigStartValue" SG_ 1245 StartBatterySOH 255;
BA_ "GenSigMaxLatency" SG_ 1245 StartBatterySOH 100;
BA_ "Platform_VMCU1_Sig" SG_ 1245 StartBatterySOH 1;
BA_ "GenSigCycleTime" SG_ 1245 JumpChargeAlert_stat_ISig_6 100;
BA_ "GenSigCycleTimeActive" SG_ 1245 JumpChargeAlert_stat_ISig_6 100;
BA_ "GenSigStartValue" SG_ 1245 JumpChargeAlert_stat_ISig_6 7;
BA_ "GenSigMaxLatency" SG_ 1245 JumpChargeAlert_stat_ISig_6 100;
BA_ "Platform_VMCU1_Sig" SG_ 1245 JumpChargeAlert_stat_ISig_6 1;
BA_ "GenSigCycleTime" SG_ 1245 StartBatteryDisplay_stat_ISig_6 100;
BA_ "GenSigCycleTimeActive" SG_ 1245 StartBatteryDisplay_stat_ISig_6 100;
BA_ "GenSigStartValue" SG_ 1245 StartBatteryDisplay_stat_ISig_6 7;
BA_ "GenSigMaxLatency" SG_ 1245 StartBatteryDisplay_stat_ISig_6 100;
BA_ "Platform_VMCU1_Sig" SG_ 1245 StartBatteryDisplay_stat_ISig_6 1;
BA_ "GenSigCycleTime" SG_ 1245 StartBatteryReset_ack 100;
BA_ "GenSigCycleTimeActive" SG_ 1245 StartBatteryReset_ack 100;
BA_ "GenSigStartValue" SG_ 1245 StartBatteryReset_ack 3;
BA_ "GenSigMaxLatency" SG_ 1245 StartBatteryReset_ack 100;
BA_ "Platform_VMCU1_Sig" SG_ 1245 StartBatteryReset_ack 1;
BA_ "GenSigCycleTime" SG_ 1245 SelfStartAssistSwitch_Input_ISig 100;
BA_ "GenSigCycleTimeActive" SG_ 1245 SelfStartAssistSwitch_Input_ISig 100;
BA_ "GenSigStartValue" SG_ 1245 SelfStartAssistSwitch_Input_ISig 3;
BA_ "SystemSignalLongSymbol" SG_ 1245 SelfStartAssistSwitch_Input_ISig "SelfStartAssistSwitch_Input_ISig_6";
BA_ "GenSigCycleTime" SG_ 1245 SelfStartAssist_stat_ISig_6 100;
BA_ "GenSigCycleTimeActive" SG_ 1245 SelfStartAssist_stat_ISig_6 100;
BA_ "GenSigStartValue" SG_ 1245 SelfStartAssist_stat_ISig_6 3;
BA_ "GenSigMaxLatency" SG_ 1245 SelfStartAssist_stat_ISig_6 100;
BA_ "Platform_VMCU1_Sig" SG_ 1245 SelfStartAssist_stat_ISig_6 1;
BA_ "GenSigCycleTime" SG_ 1245 StartBatterySOHTrustLevel 100;
BA_ "GenSigCycleTimeActive" SG_ 1245 StartBatterySOHTrustLevel 100;
BA_ "GenSigStartValue" SG_ 1245 StartBatterySOHTrustLevel 255;
BA_ "GenSigMaxLatency" SG_ 1245 StartBatterySOHTrustLevel 100;
BA_ "Platform_VMCU1_Sig" SG_ 1245 StartBatterySOHTrustLevel 1;
BA_ "GenSigCycleTime" SG_ 1245 JumpChargeInterface_stat 100;
BA_ "GenSigCycleTimeActive" SG_ 1245 JumpChargeInterface_stat 100;
BA_ "GenSigStartValue" SG_ 1245 JumpChargeInterface_stat 3;
BA_ "GenSigMaxLatency" SG_ 1245 JumpChargeInterface_stat 100;
BA_ "Platform_VMCU1_Sig" SG_ 1245 JumpChargeInterface_stat 1;
BA_ "GenSigCycleTime" SG_ 1245 GridCharger_stat 100;
BA_ "GenSigCycleTimeActive" SG_ 1245 GridCharger_stat 100;
BA_ "GenSigStartValue" SG_ 1245 GridCharger_stat 7;
BA_ "GenSigMaxLatency" SG_ 1245 GridCharger_stat 100;
BA_ "Platform_VMCU1_Sig" SG_ 1245 GridCharger_stat 1;
BA_ "GenSigSendType" SG_ 1719 AnmSig_VMCU_ChassisSubnet 1;
BA_ "GenSigCycleTime" SG_ 1719 AnmSig_VMCU_ChassisSubnet 100;
BA_ "GenSigCycleTimeActive" SG_ 1719 AnmSig_VMCU_ChassisSubnet 100;
BA_ "MmAnSignal" SG_ 1719 AnmSig_VMCU_ChassisSubnet 1;
BA_ "Platform_VMCU1_Sig" SG_ 1719 AnmSig_VMCU_ChassisSubnet 1;
BA_ "GenSigSendType" SG_ 1718 AnmSig_TPM_ChassisSubnet 1;
BA_ "GenSigCycleTime" SG_ 1718 AnmSig_TPM_ChassisSubnet 100;
BA_ "GenSigCycleTimeActive" SG_ 1718 AnmSig_TPM_ChassisSubnet 100;
BA_ "MmAnSignal" SG_ 1718 AnmSig_TPM_ChassisSubnet 1;
BA_ "Platform_VMCU1_Sig" SG_ 1718 AnmSig_TPM_ChassisSubnet 1;
BA_ "GenSigSendType" SG_ 1717 AnmSig_RCIOM_ChassisSubnet 1;
BA_ "GenSigCycleTime" SG_ 1717 AnmSig_RCIOM_ChassisSubnet 100;
BA_ "GenSigCycleTimeActive" SG_ 1717 AnmSig_RCIOM_ChassisSubnet 100;
BA_ "MmAnSignal" SG_ 1717 AnmSig_RCIOM_ChassisSubnet 1;
BA_ "Platform_VMCU1_Sig" SG_ 1717 AnmSig_RCIOM_ChassisSubnet 1;
BA_ "GenSigSendType" SG_ 1716 AnmSig_FCIOM_ChassisSubnet 1;
BA_ "GenSigCycleTime" SG_ 1716 AnmSig_FCIOM_ChassisSubnet 100;
BA_ "GenSigCycleTimeActive" SG_ 1716 AnmSig_FCIOM_ChassisSubnet 100;
BA_ "MmAnSignal" SG_ 1716 AnmSig_FCIOM_ChassisSubnet 1;
BA_ "Platform_VMCU1_Sig" SG_ 1716 AnmSig_FCIOM_ChassisSubnet 1;
BA_ "GenSigSendType" SG_ 1715 AnmSig_FAS_ChassisSubnet 1;
BA_ "GenSigCycleTime" SG_ 1715 AnmSig_FAS_ChassisSubnet 100;
BA_ "GenSigCycleTimeActive" SG_ 1715 AnmSig_FAS_ChassisSubnet 100;
BA_ "MmAnSignal" SG_ 1715 AnmSig_FAS_ChassisSubnet 1;
BA_ "Platform_VMCU1_Sig" SG_ 1715 AnmSig_FAS_ChassisSubnet 1;
BA_ "GenSigSendType" SG_ 1721 AnmSig_ECUspare4_ChassisSubnet 1;
BA_ "GenSigCycleTime" SG_ 1721 AnmSig_ECUspare4_ChassisSubnet 100;
BA_ "GenSigCycleTimeActive" SG_ 1721 AnmSig_ECUspare4_ChassisSubnet 100;
BA_ "MmAnSignal" SG_ 1721 AnmSig_ECUspare4_ChassisSubnet 1;
BA_ "Platform_VMCU1_Sig" SG_ 1721 AnmSig_ECUspare4_ChassisSubnet 1;
BA_ "GenSigSendType" SG_ 1714 AnmSig_EBS_ChassisSubnet 1;
BA_ "GenSigCycleTime" SG_ 1714 AnmSig_EBS_ChassisSubnet 100;
BA_ "GenSigCycleTimeActive" SG_ 1714 AnmSig_EBS_ChassisSubnet 100;
BA_ "MmAnSignal" SG_ 1714 AnmSig_EBS_ChassisSubnet 1;
BA_ "Platform_VMCU1_Sig" SG_ 1714 AnmSig_EBS_ChassisSubnet 1;
BA_ "GenSigSendType" SG_ 1722 AnmSig_EAS_ChassisSubnet 1;
BA_ "GenSigCycleTime" SG_ 1722 AnmSig_EAS_ChassisSubnet 100;
BA_ "GenSigCycleTimeActive" SG_ 1722 AnmSig_EAS_ChassisSubnet 100;
BA_ "MmAnSignal" SG_ 1722 AnmSig_EAS_ChassisSubnet 1;
BA_ "Platform_VMCU1_Sig" SG_ 1722 AnmSig_EAS_ChassisSubnet 1;
BA_ "GenSigSendType" SG_ 1713 AnmSig_CCIOM_ChassisSubnet 1;
BA_ "GenSigCycleTime" SG_ 1713 AnmSig_CCIOM_ChassisSubnet 100;
BA_ "GenSigCycleTimeActive" SG_ 1713 AnmSig_CCIOM_ChassisSubnet 100;
BA_ "MmAnSignal" SG_ 1713 AnmSig_CCIOM_ChassisSubnet 1;
BA_ "Platform_VMCU1_Sig" SG_ 1713 AnmSig_CCIOM_ChassisSubnet 1;
BA_ "GenSigSendType" SG_ 1720 AnmSig_BPMU_ChassisSubnet 1;
BA_ "GenSigCycleTime" SG_ 1720 AnmSig_BPMU_ChassisSubnet 100;
BA_ "GenSigCycleTimeActive" SG_ 1720 AnmSig_BPMU_ChassisSubnet 100;
BA_ "MmAnSignal" SG_ 1720 AnmSig_BPMU_ChassisSubnet 1;
BA_ "Platform_VMCU1_Sig" SG_ 1720 AnmSig_BPMU_ChassisSubnet 1;
BA_ "GenSigSendType" SG_ 1712 AnmSig_APM_ChassisSubnet 1;
BA_ "GenSigCycleTime" SG_ 1712 AnmSig_APM_ChassisSubnet 100;
BA_ "GenSigCycleTimeActive" SG_ 1712 AnmSig_APM_ChassisSubnet 100;
BA_ "MmAnSignal" SG_ 1712 AnmSig_APM_ChassisSubnet 1;
BA_ "Platform_VMCU1_Sig" SG_ 1712 AnmSig_APM_ChassisSubnet 1;
BA_ "GenSigCycleTime" SG_ 1246 APM_OBDRelDTC_PB_DtcIdB 100;
BA_ "GenSigCycleTimeActive" SG_ 1246 APM_OBDRelDTC_PB_DtcIdB 100;
BA_ "Platform_VMCU1_Sig" SG_ 1246 APM_OBDRelDTC_PB_DtcIdB 1;
BA_ "GenSigCycleTime" SG_ 1246 PBStatusDisplay_cmd_ISig_6 100;
BA_ "GenSigCycleTimeActive" SG_ 1246 PBStatusDisplay_cmd_ISig_6 100;
BA_ "GenSigStartValue" SG_ 1246 PBStatusDisplay_cmd_ISig_6 3;
BA_ "Platform_VMCU1_Sig" SG_ 1246 PBStatusDisplay_cmd_ISig_6 1;
BA_ "GenSigCycleTime" SG_ 1246 APM_OBDRelDTC_PB_DrvngCycleB 100;
BA_ "GenSigCycleTimeActive" SG_ 1246 APM_OBDRelDTC_PB_DrvngCycleB 100;
BA_ "GenSigStartValue" SG_ 1246 APM_OBDRelDTC_PB_DrvngCycleB 3;
BA_ "Platform_VMCU1_Sig" SG_ 1246 APM_OBDRelDTC_PB_DrvngCycleB 1;
BA_ "GenSigCycleTime" SG_ 1246 AutoPBRelease_stat_ISig_6 100;
BA_ "GenSigCycleTimeActive" SG_ 1246 AutoPBRelease_stat_ISig_6 100;
BA_ "GenSigStartValue" SG_ 1246 AutoPBRelease_stat_ISig_6 3;
BA_ "SeToolAncestorID_SIGNAL" SG_ 1246 AutoPBRelease_stat_ISig_6 "x0000001D042E42B1";
BA_ "SeToolItemID_SIGNAL" SG_ 1246 AutoPBRelease_stat_ISig_6 "x0000001D042E42B1";
BA_ "SeToolName_SIGNAL" SG_ 1246 AutoPBRelease_stat_ISig_6 "AutoPBRelease_stat";
BA_ "SeToolVersion_SIGNAL" SG_ 1246 AutoPBRelease_stat_ISig_6 "1";
BA_ "GenSigCycleTime" SG_ 1246 APM_OBDRelDTC_PB_DtcIdA 100;
BA_ "GenSigCycleTimeActive" SG_ 1246 APM_OBDRelDTC_PB_DtcIdA 100;
BA_ "Platform_VMCU1_Sig" SG_ 1246 APM_OBDRelDTC_PB_DtcIdA 1;
BA_ "GenSigCycleTime" SG_ 1246 APM_OBDRelDTC_PB_FailTB 100;
BA_ "GenSigCycleTimeActive" SG_ 1246 APM_OBDRelDTC_PB_FailTB 100;
BA_ "Platform_VMCU1_Sig" SG_ 1246 APM_OBDRelDTC_PB_FailTB 1;
BA_ "GenSigCycleTime" SG_ 1246 APM_OBDRelDTC_PB_DrvngCycleA 100;
BA_ "GenSigCycleTimeActive" SG_ 1246 APM_OBDRelDTC_PB_DrvngCycleA 100;
BA_ "GenSigStartValue" SG_ 1246 APM_OBDRelDTC_PB_DrvngCycleA 3;
BA_ "Platform_VMCU1_Sig" SG_ 1246 APM_OBDRelDTC_PB_DrvngCycleA 1;
BA_ "GenSigCycleTime" SG_ 1246 APM_OBDRelDTC_PB_EvalResultB 100;
BA_ "GenSigCycleTimeActive" SG_ 1246 APM_OBDRelDTC_PB_EvalResultB 100;
BA_ "GenSigStartValue" SG_ 1246 APM_OBDRelDTC_PB_EvalResultB 3;
BA_ "Platform_VMCU1_Sig" SG_ 1246 APM_OBDRelDTC_PB_EvalResultB 1;
BA_ "GenSigCycleTime" SG_ 1246 APM_OBDRelDTC_PB_EvalStatA 100;
BA_ "GenSigCycleTimeActive" SG_ 1246 APM_OBDRelDTC_PB_EvalStatA 100;
BA_ "GenSigStartValue" SG_ 1246 APM_OBDRelDTC_PB_EvalStatA 3;
BA_ "Platform_VMCU1_Sig" SG_ 1246 APM_OBDRelDTC_PB_EvalStatA 1;
BA_ "GenSigCycleTime" SG_ 1246 APM_OBDRelDTC_PB_EvalStatB 100;
BA_ "GenSigCycleTimeActive" SG_ 1246 APM_OBDRelDTC_PB_EvalStatB 100;
BA_ "GenSigStartValue" SG_ 1246 APM_OBDRelDTC_PB_EvalStatB 3;
BA_ "Platform_VMCU1_Sig" SG_ 1246 APM_OBDRelDTC_PB_EvalStatB 1;
BA_ "GenSigCycleTime" SG_ 1246 APM_OBDRelDTC_PB_EvalResultA 100;
BA_ "GenSigCycleTimeActive" SG_ 1246 APM_OBDRelDTC_PB_EvalResultA 100;
BA_ "GenSigStartValue" SG_ 1246 APM_OBDRelDTC_PB_EvalResultA 3;
BA_ "Platform_VMCU1_Sig" SG_ 1246 APM_OBDRelDTC_PB_EvalResultA 1;
BA_ "GenSigCycleTime" SG_ 1246 APM_OBDRelDTC_PB_FailTA 100;
BA_ "GenSigCycleTimeActive" SG_ 1246 APM_OBDRelDTC_PB_FailTA 100;
BA_ "Platform_VMCU1_Sig" SG_ 1246 APM_OBDRelDTC_PB_FailTA 1;
BA_ "GenSigCycleTime" SG_ 1492 APM_AirCtrMileagePrediction 100;
BA_ "GenSigCycleTimeActive" SG_ 1492 APM_AirCtrMileagePrediction 100;
BA_ "GenSigStartValue" SG_ 1492 APM_AirCtrMileagePrediction 4294967295;
BA_ "Platform_VMCU1_Sig" SG_ 1492 APM_AirCtrMileagePrediction 1;
BA_ "GenSigCycleTime" SG_ 1492 APM_AirCtrWearingPercentage 100;
BA_ "GenSigCycleTimeActive" SG_ 1492 APM_AirCtrWearingPercentage 100;
BA_ "GenSigStartValue" SG_ 1492 APM_AirCtrWearingPercentage 255;
BA_ "Platform_VMCU1_Sig" SG_ 1492 APM_AirCtrWearingPercentage 1;
BA_ "GenSigSendType" SG_ 1347 APM_Chassi_05S_FCS 7;
BA_ "Platform_VMCU1_Sig" SG_ 1347 APM_Chassi_05S_FCS 1;
BA_ "GenSigSendType" SG_ 1346 ECU2VIN_stat_ISig_6 1;
BA_ "GenSigMaxLatency" SG_ 1346 ECU2VIN_stat_ISig_6 137;
BA_ "Platform_VMCU1_Sig" SG_ 1346 ECU2VIN_stat_ISig_6 1;
BA_ "GenSigCycleTime" SG_ 822 ParkBrakeWorkshopMode_ISig_6 100;
BA_ "GenSigCycleTimeActive" SG_ 822 ParkBrakeWorkshopMode_ISig_6 100;
BA_ "GenSigStartValue" SG_ 822 ParkBrakeWorkshopMode_ISig_6 3;
BA_ "GenSigMaxLatency" SG_ 822 ParkBrakeWorkshopMode_ISig_6 35;
BA_ "Platform_VMCU1_Sig" SG_ 822 ParkBrakeWorkshopMode_ISig_6 1;
BA_ "GenSigCycleTime" SG_ 822 APM_TrailerCircPressureStatus_IS 100;
BA_ "GenSigCycleTimeActive" SG_ 822 APM_TrailerCircPressureStatus_IS 100;
BA_ "GenSigStartValue" SG_ 822 APM_TrailerCircPressureStatus_IS 3;
BA_ "Platform_VMCU1_Sig" SG_ 822 APM_TrailerCircPressureStatus_IS 1;
BA_ "SystemSignalLongSymbol" SG_ 822 APM_TrailerCircPressureStatus_IS "APM_TrailerCircPressureStatus_ISig_6";
BA_ "GenSigCycleTime" SG_ 822 APM_ParkingBrake_stat 100;
BA_ "GenSigCycleTimeActive" SG_ 822 APM_ParkingBrake_stat 100;
BA_ "GenSigStartValue" SG_ 822 APM_ParkingBrake_stat 3;
BA_ "NeedsUpdateBit" SG_ 822 APM_ParkingBrake_stat 1;
BA_ "Platform_VMCU1_Sig" SG_ 822 APM_ParkingBrake_stat 1;
BA_ "GenSigSendType" SG_ 822 APM_ParkingBrake_stat_UB 7;
BA_ "GenSigCycleTime" SG_ 822 APM_ParkingBrake_stat_UB 100;
BA_ "GenSigCycleTimeActive" SG_ 822 APM_ParkingBrake_stat_UB 100;
BA_ "Platform_VMCU1_Sig" SG_ 822 APM_ParkingBrake_stat_UB 1;
BA_ "GenSigCycleTime" SG_ 822 APM_OverrunMode_stat 100;
BA_ "GenSigCycleTimeActive" SG_ 822 APM_OverrunMode_stat 100;
BA_ "GenSigStartValue" SG_ 822 APM_OverrunMode_stat 3;
BA_ "Platform_VMCU1_Sig" SG_ 822 APM_OverrunMode_stat 1;
BA_ "GenSigCycleTime" SG_ 822 APM_AirCompressorStatus 100;
BA_ "GenSigCycleTimeActive" SG_ 822 APM_AirCompressorStatus 100;
BA_ "GenSigStartValue" SG_ 822 APM_AirCompressorStatus 3;
BA_ "Platform_VMCU1_Sig" SG_ 822 APM_AirCompressorStatus 1;
BA_ "GenSigCycleTime" SG_ 822 ParkBrakeReleaseMode2_ISig_6 100;
BA_ "GenSigCycleTimeActive" SG_ 822 ParkBrakeReleaseMode2_ISig_6 100;
BA_ "GenSigStartValue" SG_ 822 ParkBrakeReleaseMode2_ISig_6 15;
BA_ "GenSigCycleTime" SG_ 822 APM_PBReleasePossible_stat 100;
BA_ "GenSigCycleTimeActive" SG_ 822 APM_PBReleasePossible_stat 100;
BA_ "GenSigStartValue" SG_ 822 APM_PBReleasePossible_stat 3;
BA_ "Platform_VMCU1_Sig" SG_ 822 APM_PBReleasePossible_stat 1;
BA_ "GenSigCycleTime" SG_ 822 APM_LowVMPBInfoReq 100;
BA_ "GenSigCycleTimeActive" SG_ 822 APM_LowVMPBInfoReq 100;
BA_ "GenSigStartValue" SG_ 822 APM_LowVMPBInfoReq 7;
BA_ "Platform_VMCU1_Sig" SG_ 822 APM_LowVMPBInfoReq 1;
BA_ "GenSigCycleTime" SG_ 822 APM_PoorAirPressureInfo 100;
BA_ "GenSigCycleTimeActive" SG_ 822 APM_PoorAirPressureInfo 100;
BA_ "GenSigStartValue" SG_ 822 APM_PoorAirPressureInfo 3;
BA_ "NeedsUpdateBit" SG_ 822 APM_PoorAirPressureInfo 1;
BA_ "Platform_VMCU1_Sig" SG_ 822 APM_PoorAirPressureInfo 1;
BA_ "GenSigCycleTime" SG_ 822 APM_ParkBrakeApplicationMode2 100;
BA_ "GenSigCycleTimeActive" SG_ 822 APM_ParkBrakeApplicationMode2 100;
BA_ "GenSigStartValue" SG_ 822 APM_ParkBrakeApplicationMode2 15;
BA_ "GenSigCycleTime" SG_ 822 EPBPowerFeedRequest 100;
BA_ "GenSigCycleTimeActive" SG_ 822 EPBPowerFeedRequest 100;
BA_ "GenSigStartValue" SG_ 822 EPBPowerFeedRequest 3;
BA_ "Platform_VMCU1_Sig" SG_ 822 EPBPowerFeedRequest 1;
BA_ "GenSigCycleTime" SG_ 822 PBReleaseInhibit_EPBState_ISig_6 100;
BA_ "GenSigCycleTimeActive" SG_ 822 PBReleaseInhibit_EPBState_ISig_6 100;
BA_ "GenSigStartValue" SG_ 822 PBReleaseInhibit_EPBState_ISig_6 7;
BA_ "Platform_VMCU1_Sig" SG_ 822 PBReleaseInhibit_EPBState_ISig_6 1;
BA_ "GenSigSendType" SG_ 822 APM_PoorAirPressureInfo_UB 7;
BA_ "GenSigCycleTime" SG_ 822 APM_PoorAirPressureInfo_UB 100;
BA_ "GenSigCycleTimeActive" SG_ 822 APM_PoorAirPressureInfo_UB 100;
BA_ "Platform_VMCU1_Sig" SG_ 822 APM_PoorAirPressureInfo_UB 1;
BA_ "GenSigCycleTime" SG_ 822 APM_AirDryerCtrReset_ack 100;
BA_ "GenSigCycleTimeActive" SG_ 822 APM_AirDryerCtrReset_ack 100;
BA_ "GenSigStartValue" SG_ 822 APM_AirDryerCtrReset_ack 3;
BA_ "Platform_VMCU1_Sig" SG_ 822 APM_AirDryerCtrReset_ack 1;
BA_ "GenSigCycleTime" SG_ 822 ParkBrakeAlert_ISig_6 100;
BA_ "GenSigCycleTimeActive" SG_ 822 ParkBrakeAlert_ISig_6 100;
BA_ "GenSigStartValue" SG_ 822 ParkBrakeAlert_ISig_6 3;
BA_ "GenSigMaxLatency" SG_ 822 ParkBrakeAlert_ISig_6 35;
BA_ "Platform_VMCU1_Sig" SG_ 822 ParkBrakeAlert_ISig_6 1;
BA_ "GenSigCycleTime" SG_ 1345 APM_ServiceBrakeAirPrsCircuit2 100;
BA_ "GenSigCycleTimeActive" SG_ 1345 APM_ServiceBrakeAirPrsCircuit2 100;
BA_ "GenSigStartValue" SG_ 1345 APM_ServiceBrakeAirPrsCircuit2 255;
BA_ "Platform_VMCU1_Sig" SG_ 1345 APM_ServiceBrakeAirPrsCircuit2 1;
BA_ "GenSigCycleTime" SG_ 1345 APM_ServiceBrakeAirPrsCircuit1 100;
BA_ "GenSigCycleTimeActive" SG_ 1345 APM_ServiceBrakeAirPrsCircuit1 100;
BA_ "GenSigStartValue" SG_ 1345 APM_ServiceBrakeAirPrsCircuit1 255;
BA_ "Platform_VMCU1_Sig" SG_ 1345 APM_ServiceBrakeAirPrsCircuit1 1;
BA_ "GenSigSendType" SG_ 1345 APM_AirDryerCoolFanSpd_rqst_UB 7;
BA_ "Platform_VMCU1_Sig" SG_ 1345 APM_AirDryerCoolFanSpd_rqst_UB 1;
BA_ "GenSigCycleTime" SG_ 1345 APM_ParkAndTrailerAirPressure 100;
BA_ "GenSigCycleTimeActive" SG_ 1345 APM_ParkAndTrailerAirPressure 100;
BA_ "GenSigStartValue" SG_ 1345 APM_ParkAndTrailerAirPressure 255;
BA_ "Platform_VMCU1_Sig" SG_ 1345 APM_ParkAndTrailerAirPressure 1;
BA_ "GenSigCycleTime" SG_ 1345 ExhManifAirInjectionInhibit_ISig 100;
BA_ "GenSigCycleTimeActive" SG_ 1345 ExhManifAirInjectionInhibit_ISig 100;
BA_ "GenSigStartValue" SG_ 1345 ExhManifAirInjectionInhibit_ISig 3;
BA_ "SystemSignalLongSymbol" SG_ 1345 ExhManifAirInjectionInhibit_ISig "ExhManifAirInjectionInhibit_ISig_6";
BA_ "GenSigCycleTime" SG_ 1345 APM_AirDryerCoolFanSpd_rqst 100;
BA_ "GenSigCycleTimeActive" SG_ 1345 APM_AirDryerCoolFanSpd_rqst 100;
BA_ "GenSigStartValue" SG_ 1345 APM_AirDryerCoolFanSpd_rqst 65535;
BA_ "NeedsUpdateBit" SG_ 1345 APM_AirDryerCoolFanSpd_rqst 1;
BA_ "Platform_VMCU1_Sig" SG_ 1345 APM_AirDryerCoolFanSpd_rqst 1;
BA_ "GenSigCycleTime" SG_ 949 APM_ParkBrakeActuationStatus 100;
BA_ "GenSigCycleTimeActive" SG_ 949 APM_ParkBrakeActuationStatus 100;
BA_ "GenSigStartValue" SG_ 949 APM_ParkBrakeActuationStatus 7;
BA_ "NeedsUpdateBit" SG_ 949 APM_ParkBrakeActuationStatus 1;
BA_ "Platform_VMCU1_Sig" SG_ 949 APM_ParkBrakeActuationStatus 1;
BA_ "GenSigCycleTime" SG_ 949 EPBEngineStopAllowed 100;
BA_ "GenSigCycleTimeActive" SG_ 949 EPBEngineStopAllowed 100;
BA_ "GenSigStartValue" SG_ 949 EPBEngineStopAllowed 7;
BA_ "Platform_VMCU1_Sig" SG_ 949 EPBEngineStopAllowed 1;
BA_ "GenSigCycleTime" SG_ 949 APM_ESCReqAir_CtrlTrimMode 100;
BA_ "GenSigCycleTimeActive" SG_ 949 APM_ESCReqAir_CtrlTrimMode 100;
BA_ "GenSigStartValue" SG_ 949 APM_ESCReqAir_CtrlTrimMode 15;
BA_ "Platform_VMCU1_Sig" SG_ 949 APM_ESCReqAir_CtrlTrimMode 1;
BA_ "GenSigCycleTime" SG_ 949 APM_ESCReqAir_CtrlTrimStat 100;
BA_ "GenSigCycleTimeActive" SG_ 949 APM_ESCReqAir_CtrlTrimStat 100;
BA_ "GenSigStartValue" SG_ 949 APM_ESCReqAir_CtrlTrimStat 7;
BA_ "Platform_VMCU1_Sig" SG_ 949 APM_ESCReqAir_CtrlTrimStat 1;
BA_ "GenSigCycleTime" SG_ 949 APM_PBChamberAirPressure 100;
BA_ "GenSigCycleTimeActive" SG_ 949 APM_PBChamberAirPressure 100;
BA_ "GenSigStartValue" SG_ 949 APM_PBChamberAirPressure 255;
BA_ "Platform_VMCU1_Sig" SG_ 949 APM_PBChamberAirPressure 1;
BA_ "GenSigCycleTime" SG_ 949 APM_LowAirPressureAlert 100;
BA_ "GenSigCycleTimeActive" SG_ 949 APM_LowAirPressureAlert 100;
BA_ "GenSigStartValue" SG_ 949 APM_LowAirPressureAlert 3;
BA_ "Platform_VMCU1_Sig" SG_ 949 APM_LowAirPressureAlert 1;
BA_ "GenSigCycleTime" SG_ 949 APM_TrailerTest_stat 100;
BA_ "GenSigCycleTimeActive" SG_ 949 APM_TrailerTest_stat 100;
BA_ "GenSigStartValue" SG_ 949 APM_TrailerTest_stat 7;
BA_ "Platform_VMCU1_Sig" SG_ 949 APM_TrailerTest_stat 1;
BA_ "GenSigCycleTime" SG_ 949 XPRsystemstate_ISig_6 100;
BA_ "GenSigCycleTimeActive" SG_ 949 XPRsystemstate_ISig_6 100;
BA_ "GenSigStartValue" SG_ 949 XPRsystemstate_ISig_6 255;
BA_ "Platform_VMCU1_Sig" SG_ 949 XPRsystemstate_ISig_6 1;
BA_ "GenSigCycleTime" SG_ 949 EPBBackupMode_ISig_6 100;
BA_ "GenSigCycleTimeActive" SG_ 949 EPBBackupMode_ISig_6 100;
BA_ "GenSigStartValue" SG_ 949 EPBBackupMode_ISig_6 15;
BA_ "GenSigMaxLatency" SG_ 949 EPBBackupMode_ISig_6 36;
BA_ "Platform_VMCU1_Sig" SG_ 949 EPBBackupMode_ISig_6 1;
BA_ "GenSigCycleTime" SG_ 949 APM_ESCReqAir_CtrlTrimValue 100;
BA_ "GenSigCycleTimeActive" SG_ 949 APM_ESCReqAir_CtrlTrimValue 100;
BA_ "GenSigStartValue" SG_ 949 APM_ESCReqAir_CtrlTrimValue 255;
BA_ "Platform_VMCU1_Sig" SG_ 949 APM_ESCReqAir_CtrlTrimValue 1;
BA_ "GenSigCycleTime" SG_ 949 APM_ESCReqAir_CtrlTrimReq 100;
BA_ "GenSigCycleTimeActive" SG_ 949 APM_ESCReqAir_CtrlTrimReq 100;
BA_ "GenSigStartValue" SG_ 949 APM_ESCReqAir_CtrlTrimReq 7;
BA_ "Platform_VMCU1_Sig" SG_ 949 APM_ESCReqAir_CtrlTrimReq 1;
BA_ "GenSigCycleTime" SG_ 949 PBReleaseAcceptance_stat_ISig_6 100;
BA_ "GenSigCycleTimeActive" SG_ 949 PBReleaseAcceptance_stat_ISig_6 100;
BA_ "GenSigStartValue" SG_ 949 PBReleaseAcceptance_stat_ISig_6 7;
BA_ "Platform_VMCU1_Sig" SG_ 949 PBReleaseAcceptance_stat_ISig_6 1;
BA_ "GenSigSendType" SG_ 949 APM_ParkBrakeActuationStatus_UB 7;
BA_ "GenSigCycleTime" SG_ 949 APM_ParkBrakeActuationStatus_UB 100;
BA_ "GenSigCycleTimeActive" SG_ 949 APM_ParkBrakeActuationStatus_UB 100;
BA_ "Platform_VMCU1_Sig" SG_ 949 APM_ParkBrakeActuationStatus_UB 1;
BA_ "GenSigCycleTime" SG_ 949 EPBHSARequest 100;
BA_ "GenSigCycleTimeActive" SG_ 949 EPBHSARequest 100;
BA_ "GenSigStartValue" SG_ 949 EPBHSARequest 7;
BA_ "GenSigMaxLatency" SG_ 949 EPBHSARequest 59;
BA_ "Platform_VMCU1_Sig" SG_ 949 EPBHSARequest 1;
BA_ "SeToolAncestorID_SIGNAL" SG_ 949 EPBHSARequest "x0000001D04297EC4";
BA_ "SeToolItemID_SIGNAL" SG_ 949 EPBHSARequest "x0000001D04297EC4";
BA_ "SeToolName_SIGNAL" SG_ 949 EPBHSARequest "EPBHSARequest";
BA_ "SeToolVersion_SIGNAL" SG_ 949 EPBHSARequest "1";
BA_REL_ "GenSigFirstTimeoutTime" BU_SG_REL_ BPMU SG_ 1251 LivBatteryCharging_stat_ISig_6 3000;
BA_REL_ "GenSigTimeoutTime" BU_SG_REL_ BPMU SG_ 1251 LivBatteryCharging_stat_ISig_6 600;
BA_REL_ "GenSigFirstTimeoutTime" BU_SG_REL_ VMCU SG_ 1251 LivBatteryCharging_stat_ISig_6 3000;
BA_REL_ "GenSigTimeoutTime" BU_SG_REL_ VMCU SG_ 1251 LivBatteryCharging_stat_ISig_6 600;
BA_REL_ "GenSigFirstTimeoutTime" BU_SG_REL_ VMCU SG_ 1251 LivBatDisconnectDetectStat_ISig_ 3000;
BA_REL_ "GenSigTimeoutTime" BU_SG_REL_ VMCU SG_ 1251 LivBatDisconnectDetectStat_ISig_ 600;
BA_REL_ "GenSigFirstTimeoutTime" BU_SG_REL_ VMCU SG_ 1251 DiffLockInterWhlStatSplitBox2 3000;
BA_REL_ "GenSigTimeoutTime" BU_SG_REL_ VMCU SG_ 1251 DiffLockInterWhlStatSplitBox2 600;
BA_REL_ "GenSigFirstTimeoutTime" BU_SG_REL_ VMCU SG_ 1251 GearRangeUnengaged_ISig_6 3000;
BA_REL_ "GenSigTimeoutTime" BU_SG_REL_ VMCU SG_ 1251 GearRangeUnengaged_ISig_6 600;
BA_REL_ "GenSigFirstTimeoutTime" BU_SG_REL_ VMCU SG_ 1251 SideMarkersLight4_FailStat 3000;
BA_REL_ "GenSigTimeoutTime" BU_SG_REL_ VMCU SG_ 1251 SideMarkersLight4_FailStat 600;
BA_REL_ "GenSigFirstTimeoutTime" BU_SG_REL_ VMCU SG_ 1251 GChargerStatus_ISig_6 3000;
BA_REL_ "GenSigTimeoutTime" BU_SG_REL_ VMCU SG_ 1251 GChargerStatus_ISig_6 600;
BA_REL_ "GenSigFirstTimeoutTime" BU_SG_REL_ RCIOM SG_ 1251 FrontOffsetLampCalib 3000;
BA_REL_ "GenSigTimeoutTime" BU_SG_REL_ RCIOM SG_ 1251 FrontOffsetLampCalib 600;
BA_REL_ "GenSigFirstTimeoutTime" BU_SG_REL_ EBS SG_ 1251 CCIOM_LowVMPBInfoReq 3000;
BA_REL_ "GenSigTimeoutTime" BU_SG_REL_ EBS SG_ 1251 CCIOM_LowVMPBInfoReq 600;
BA_REL_ "GenSigFirstTimeoutTime" BU_SG_REL_ VMCU SG_ 1251 DiffLockInterWhlStatusFrAxle2 3000;
BA_REL_ "GenSigTimeoutTime" BU_SG_REL_ VMCU SG_ 1251 DiffLockInterWhlStatusFrAxle2 600;
BA_REL_ "GenSigFirstTimeoutTime" BU_SG_REL_ BPMU SG_ 1251 BatterySensorVoltage 3000;
BA_REL_ "GenSigTimeoutTime" BU_SG_REL_ BPMU SG_ 1251 BatterySensorVoltage 600;
BA_REL_ "GenSigFirstTimeoutTime" BU_SG_REL_ VMCU SG_ 950 CCIOM_AirCompressorStatus 3000;
BA_REL_ "GenSigTimeoutTime" BU_SG_REL_ VMCU SG_ 950 CCIOM_AirCompressorStatus 300;
BA_REL_ "GenSigFirstTimeoutTime" BU_SG_REL_ RCIOM SG_ 950 CCIOM_ServiceBrakeAirPCircuit2 3000;
BA_REL_ "GenSigTimeoutTime" BU_SG_REL_ RCIOM SG_ 950 CCIOM_ServiceBrakeAirPCircuit2 300;
BA_REL_ "GenSigFirstTimeoutTime" BU_SG_REL_ VMCU SG_ 950 CCIOM_ServiceBrakeAirPCircuit2 3000;
BA_REL_ "GenSigTimeoutTime" BU_SG_REL_ VMCU SG_ 950 CCIOM_ServiceBrakeAirPCircuit2 300;
BA_REL_ "GenSigFirstTimeoutTime" BU_SG_REL_ VMCU SG_ 950 CCIOM_AirDryerCoolFanSpd_rqst 3000;
BA_REL_ "GenSigTimeoutTime" BU_SG_REL_ VMCU SG_ 950 CCIOM_AirDryerCoolFanSpd_rqst 500;
BA_REL_ "GenSigFirstTimeoutTime" BU_SG_REL_ VMCU SG_ 950 CCIOM_PoorAirPressureInfo 3000;
BA_REL_ "GenSigTimeoutTime" BU_SG_REL_ VMCU SG_ 950 CCIOM_PoorAirPressureInfo 500;
BA_REL_ "GenSigFirstTimeoutTime" BU_SG_REL_ VMCU SG_ 950 CCIOM_AirDryerCtrReset_ack 3000;
BA_REL_ "GenSigTimeoutTime" BU_SG_REL_ VMCU SG_ 950 CCIOM_AirDryerCtrReset_ack 300;
BA_REL_ "GenSigFirstTimeoutTime" BU_SG_REL_ EBS SG_ 950 CCIOM_LowAirPressureAlert 3000;
BA_REL_ "GenSigTimeoutTime" BU_SG_REL_ EBS SG_ 950 CCIOM_LowAirPressureAlert 300;
BA_REL_ "GenSigFirstTimeoutTime" BU_SG_REL_ VMCU SG_ 950 CCIOM_LowAirPressureAlert 3000;
BA_REL_ "GenSigTimeoutTime" BU_SG_REL_ VMCU SG_ 950 CCIOM_LowAirPressureAlert 300;
BA_REL_ "GenSigFirstTimeoutTime" BU_SG_REL_ RCIOM SG_ 950 CCIOM_ServiceBrakeAirPCircuit1 3000;
BA_REL_ "GenSigTimeoutTime" BU_SG_REL_ RCIOM SG_ 950 CCIOM_ServiceBrakeAirPCircuit1 300;
BA_REL_ "GenSigFirstTimeoutTime" BU_SG_REL_ VMCU SG_ 950 CCIOM_ServiceBrakeAirPCircuit1 3000;
BA_REL_ "GenSigTimeoutTime" BU_SG_REL_ VMCU SG_ 950 CCIOM_ServiceBrakeAirPCircuit1 300;
BA_REL_ "GenSigFirstTimeoutTime" BU_SG_REL_ VMCU SG_ 950 CCIOM_OverrunMode_stat 3000;
BA_REL_ "GenSigTimeoutTime" BU_SG_REL_ VMCU SG_ 950 CCIOM_OverrunMode_stat 300;
BA_REL_ "GenSigFirstTimeoutTime" BU_SG_REL_ VMCU SG_ 950 CCIOM_ParkingBrake_stat 3000;
BA_REL_ "GenSigTimeoutTime" BU_SG_REL_ VMCU SG_ 950 CCIOM_ParkingBrake_stat 500;
BA_REL_ "GenSigFirstTimeoutTime" BU_SG_REL_ RCIOM SG_ 950 CCIOM_ParkingBrake_stat 3000;
BA_REL_ "GenSigTimeoutTime" BU_SG_REL_ RCIOM SG_ 950 CCIOM_ParkingBrake_stat 500;
BA_REL_ "GenSigFirstTimeoutTime" BU_SG_REL_ VMCU SG_ 950 CCIOM_ParkBrakeApplicationMode 3000;
BA_REL_ "GenSigTimeoutTime" BU_SG_REL_ VMCU SG_ 950 CCIOM_ParkBrakeApplicationMode 300;
BA_REL_ "GenSigFirstTimeoutTime" BU_SG_REL_ VMCU SG_ 950 CCIOM_ParkBrakeAlert_ISig_6 3000;
BA_REL_ "GenSigTimeoutTime" BU_SG_REL_ VMCU SG_ 950 CCIOM_ParkBrakeAlert_ISig_6 300;
BA_REL_ "GenSigFirstTimeoutTime" BU_SG_REL_ EBS SG_ 950 CCIOM_ParkBrakeActuationStatus 3000;
BA_REL_ "GenSigTimeoutTime" BU_SG_REL_ EBS SG_ 950 CCIOM_ParkBrakeActuationStatus 500;
BA_REL_ "GenSigFirstTimeoutTime" BU_SG_REL_ VMCU SG_ 950 CCIOM_ParkBrakeActuationStatus 3000;
BA_REL_ "GenSigTimeoutTime" BU_SG_REL_ VMCU SG_ 950 CCIOM_ParkBrakeActuationStatus 500;
BA_REL_ "GenSigFirstTimeoutTime" BU_SG_REL_ RCIOM SG_ 950 CCIOM_ParkBrakeActuationStatus 3000;
BA_REL_ "GenSigTimeoutTime" BU_SG_REL_ RCIOM SG_ 950 CCIOM_ParkBrakeActuationStatus 300;
BA_REL_ "GenSigFirstTimeoutTime" BU_SG_REL_ VMCU SG_ 1495 CCIOM_AirCtrMileagePrediction 48000;
BA_REL_ "GenSigTimeoutTime" BU_SG_REL_ VMCU SG_ 1495 CCIOM_AirCtrMileagePrediction 12000;
BA_REL_ "GenSigFirstTimeoutTime" BU_SG_REL_ VMCU SG_ 1495 CCIOM_AirCtrWearingPercentage 48000;
BA_REL_ "GenSigTimeoutTime" BU_SG_REL_ VMCU SG_ 1495 CCIOM_AirCtrWearingPercentage 12000;
BA_REL_ "GenSigFirstTimeoutTime" BU_SG_REL_ VMCU SG_ 1242 BatterySOCactCriticalAlert_ISig_ 3000;
BA_REL_ "GenSigTimeoutTime" BU_SG_REL_ VMCU SG_ 1242 BatterySOCactCriticalAlert_ISig_ 300;
BA_REL_ "GenSigFirstTimeoutTime" BU_SG_REL_ BPMU SG_ 1242 BatteryTemp_ISig_6 3000;
BA_REL_ "GenSigTimeoutTime" BU_SG_REL_ BPMU SG_ 1242 BatteryTemp_ISig_6 300;
BA_REL_ "GenSigFirstTimeoutTime" BU_SG_REL_ VMCU SG_ 1242 BatteryTemp_ISig_6 3000;
BA_REL_ "GenSigTimeoutTime" BU_SG_REL_ VMCU SG_ 1242 BatteryTemp_ISig_6 300;
BA_REL_ "GenSigFirstTimeoutTime" BU_SG_REL_ VMCU SG_ 1242 BatteryTempAlert_rqst_ISig_6 3000;
BA_REL_ "GenSigTimeoutTime" BU_SG_REL_ VMCU SG_ 1242 BatteryTempAlert_rqst_ISig_6 300;
BA_REL_ "GenSigFirstTimeoutTime" BU_SG_REL_ VMCU SG_ 1242 BatteryTempAlertRawData_rqst_ISi 3000;
BA_REL_ "GenSigTimeoutTime" BU_SG_REL_ VMCU SG_ 1242 BatteryTempAlertRawData_rqst_ISi 300;
BA_REL_ "GenSigFirstTimeoutTime" BU_SG_REL_ VMCU SG_ 1242 BatterySOCact_ISig_6 3000;
BA_REL_ "GenSigTimeoutTime" BU_SG_REL_ VMCU SG_ 1242 BatterySOCact_ISig_6 300;
BA_REL_ "GenSigFirstTimeoutTime" BU_SG_REL_ RCIOM SG_ 1242 RelativeLevelFrontAxleLeftRaw 3000;
BA_REL_ "GenSigTimeoutTime" BU_SG_REL_ RCIOM SG_ 1242 RelativeLevelFrontAxleLeftRaw 300;
BA_REL_ "GenSigFirstTimeoutTime" BU_SG_REL_ RCIOM SG_ 1242 RelativeLevelFrontAxleRightRaw 3000;
BA_REL_ "GenSigTimeoutTime" BU_SG_REL_ RCIOM SG_ 1242 RelativeLevelFrontAxleRightRaw 300;
BA_REL_ "GenSigFirstTimeoutTime" BU_SG_REL_ RCIOM SG_ 1510 ECSFrontCRC_CRC 48000;
BA_REL_ "GenSigTimeoutTime" BU_SG_REL_ RCIOM SG_ 1510 ECSFrontCRC_CRC 12000;
BA_REL_ "GenSigFirstTimeoutTime" BU_SG_REL_ BPMU SG_ 1510 WantedLBChargingVoltage 48000;
BA_REL_ "GenSigTimeoutTime" BU_SG_REL_ BPMU SG_ 1510 WantedLBChargingVoltage 12000;
BA_REL_ "GenSigFirstTimeoutTime" BU_SG_REL_ RCIOM SG_ 1510 ECSFrontCRC_Status 48000;
BA_REL_ "GenSigTimeoutTime" BU_SG_REL_ RCIOM SG_ 1510 ECSFrontCRC_Status 12000;
BA_REL_ "GenSigFirstTimeoutTime" BU_SG_REL_ VMCU SG_ 1250 BatterySOHTrustLevel 3000;
BA_REL_ "GenSigTimeoutTime" BU_SG_REL_ VMCU SG_ 1250 BatterySOHTrustLevel 600;
BA_REL_ "GenSigFirstTimeoutTime" BU_SG_REL_ VMCU SG_ 1250 BatterySOH_ISig_6 3000;
BA_REL_ "GenSigTimeoutTime" BU_SG_REL_ VMCU SG_ 1250 BatterySOH_ISig_6 600;
BA_REL_ "GenSigFirstTimeoutTime" BU_SG_REL_ VMCU SG_ 1250 BatteryVoltageDisplayValue_ISig_ 3000;
BA_REL_ "GenSigTimeoutTime" BU_SG_REL_ VMCU SG_ 1250 BatteryVoltageDisplayValue_ISig_ 600;
BA_REL_ "GenSigFirstTimeoutTime" BU_SG_REL_ VMCU SG_ 1250 BatterySOF 3000;
BA_REL_ "GenSigTimeoutTime" BU_SG_REL_ VMCU SG_ 1250 BatterySOF 600;
BA_REL_ "GenSigFirstTimeoutTime" BU_SG_REL_ VMCU SG_ 1250 BatteryCurrent_ISig_6 3000;
BA_REL_ "GenSigTimeoutTime" BU_SG_REL_ VMCU SG_ 1250 BatteryCurrent_ISig_6 600;
BA_REL_ "GenSigFirstTimeoutTime" BU_SG_REL_ BPMU SG_ 1250 BatterySOCnom_ISig_6 3000;
BA_REL_ "GenSigTimeoutTime" BU_SG_REL_ BPMU SG_ 1250 BatterySOCnom_ISig_6 600;
BA_REL_ "GenSigFirstTimeoutTime" BU_SG_REL_ VMCU SG_ 1250 BatterySOCnom_ISig_6 3000;
BA_REL_ "GenSigTimeoutTime" BU_SG_REL_ VMCU SG_ 1250 BatterySOCnom_ISig_6 600;
BA_REL_ "GenSigFirstTimeoutTime" BU_SG_REL_ RCIOM SG_ 823 FifthWheelLockingInformation_ISi 3000;
BA_REL_ "GenSigTimeoutTime" BU_SG_REL_ RCIOM SG_ 823 FifthWheelLockingInformation_ISi 500;
BA_REL_ "GenSigFirstTimeoutTime" BU_SG_REL_ VMCU SG_ 823 FifthWheelLockingInformation_ISi 3000;
BA_REL_ "GenSigTimeoutTime" BU_SG_REL_ VMCU SG_ 823 FifthWheelLockingInformation_ISi 500;
BA_REL_ "GenSigFirstTimeoutTime" BU_SG_REL_ VMCU SG_ 823 DoubleFrontAxleSteeringWarning_I 3000;
BA_REL_ "GenSigTimeoutTime" BU_SG_REL_ VMCU SG_ 823 DoubleFrontAxleSteeringWarning_I 180;
BA_REL_ "GenSigFirstTimeoutTime" BU_SG_REL_ VMCU SG_ 823 DifferentialLockStateFrAxle1_ISi 3000;
BA_REL_ "GenSigTimeoutTime" BU_SG_REL_ VMCU SG_ 823 DifferentialLockStateFrAxle1_ISi 500;
BA_REL_ "GenSigFirstTimeoutTime" BU_SG_REL_ VMCU SG_ 823 DirInd_MiddleSide_Status 3000;
BA_REL_ "GenSigTimeoutTime" BU_SG_REL_ VMCU SG_ 823 DirInd_MiddleSide_Status 180;
BA_REL_ "GenSigFirstTimeoutTime" BU_SG_REL_ VMCU SG_ 823 ExtendedTrailerBrakeValveStat 3000;
BA_REL_ "GenSigTimeoutTime" BU_SG_REL_ VMCU SG_ 823 ExtendedTrailerBrakeValveStat 180;
BA_REL_ "GenSigFirstTimeoutTime" BU_SG_REL_ VMCU SG_ 823 TransmLowRangeSenseSwitch_ISig_6 3000;
BA_REL_ "GenSigTimeoutTime" BU_SG_REL_ VMCU SG_ 823 TransmLowRangeSenseSwitch_ISig_6 180;
BA_REL_ "GenSigFirstTimeoutTime" BU_SG_REL_ RCIOM SG_ 823 ElectricalLoadReduction_rqst_ISi 3000;
BA_REL_ "GenSigTimeoutTime" BU_SG_REL_ RCIOM SG_ 823 ElectricalLoadReduction_rqst_ISi 500;
BA_REL_ "GenSigFirstTimeoutTime" BU_SG_REL_ VMCU SG_ 823 ElectricalLoadReduction_rqst_ISi 3000;
BA_REL_ "GenSigTimeoutTime" BU_SG_REL_ VMCU SG_ 823 ElectricalLoadReduction_rqst_ISi 500;
BA_REL_ "GenSigFirstTimeoutTime" BU_SG_REL_ VMCU SG_ 823 WrknLghtChassisOutpFalr_stat 3000;
BA_REL_ "GenSigTimeoutTime" BU_SG_REL_ VMCU SG_ 823 WrknLghtChassisOutpFalr_stat 180;
BA_REL_ "GenSigFirstTimeoutTime" BU_SG_REL_ VMCU SG_ 823 ManTransmiOilTemp_ISig_6 3000;
BA_REL_ "GenSigTimeoutTime" BU_SG_REL_ VMCU SG_ 823 ManTransmiOilTemp_ISig_6 500;
BA_REL_ "GenSigFirstTimeoutTime" BU_SG_REL_ VMCU SG_ 823 LoadCutOffIndication_cmd_ISig_6 3000;
BA_REL_ "GenSigTimeoutTime" BU_SG_REL_ VMCU SG_ 823 LoadCutOffIndication_cmd_ISig_6 180;
BA_REL_ "GenSigFirstTimeoutTime" BU_SG_REL_ VMCU SG_ 823 TransmReverseDirectionSw_stat_IS 3000;
BA_REL_ "GenSigTimeoutTime" BU_SG_REL_ VMCU SG_ 823 TransmReverseDirectionSw_stat_IS 180;
BA_REL_ "GenSigFirstTimeoutTime" BU_SG_REL_ VMCU SG_ 823 BatterySOCAlert_rqst_ISig_6 3000;
BA_REL_ "GenSigTimeoutTime" BU_SG_REL_ VMCU SG_ 823 BatterySOCAlert_rqst_ISig_6 180;
BA_REL_ "GenSigFirstTimeoutTime" BU_SG_REL_ VMCU SG_ 823 BatteryCapacity_Ack 3000;
BA_REL_ "GenSigTimeoutTime" BU_SG_REL_ VMCU SG_ 823 BatteryCapacity_Ack 180;
BA_REL_ "GenSigFirstTimeoutTime" BU_SG_REL_ RCIOM SG_ 823 FrontLimpHomeTrigger 3000;
BA_REL_ "GenSigTimeoutTime" BU_SG_REL_ RCIOM SG_ 823 FrontLimpHomeTrigger 180;
BA_REL_ "GenSigFirstTimeoutTime" BU_SG_REL_ VMCU SG_ 823 GearSplit_Status_ISig_6 3000;
BA_REL_ "GenSigTimeoutTime" BU_SG_REL_ VMCU SG_ 823 GearSplit_Status_ISig_6 500;
BA_REL_ "GenSigFirstTimeoutTime" BU_SG_REL_ VMCU SG_ 823 DiffLockInterWhlStatusSplitBox_I 3000;
BA_REL_ "GenSigTimeoutTime" BU_SG_REL_ VMCU SG_ 823 DiffLockInterWhlStatusSplitBox_I 180;
BA_REL_ "GenSigFirstTimeoutTime" BU_SG_REL_ VMCU SG_ 823 FifthWheelHandleLock_ind 3000;
BA_REL_ "GenSigTimeoutTime" BU_SG_REL_ VMCU SG_ 823 FifthWheelHandleLock_ind 180;
BA_REL_ "GenSigFirstTimeoutTime" BU_SG_REL_ VMCU SG_ 823 DifferentialLockStateCentral_ISi 3000;
BA_REL_ "GenSigTimeoutTime" BU_SG_REL_ VMCU SG_ 823 DifferentialLockStateCentral_ISi 180;
BA_REL_ "GenSigFirstTimeoutTime" BU_SG_REL_ VMCU SG_ 1244 TrailerBrakePres_stat 3000;
BA_REL_ "GenSigTimeoutTime" BU_SG_REL_ VMCU SG_ 1244 TrailerBrakePres_stat 600;
BA_REL_ "GenSigFirstTimeoutTime" BU_SG_REL_ VMCU SG_ 1244 ExtraBBContUnlockFeedback 3000;
BA_REL_ "GenSigTimeoutTime" BU_SG_REL_ VMCU SG_ 1244 ExtraBBContUnlockFeedback 600;
BA_REL_ "GenSigFirstTimeoutTime" BU_SG_REL_ RCIOM SG_ 1244 FrontAxle1Load_ISig_6 3000;
BA_REL_ "GenSigTimeoutTime" BU_SG_REL_ RCIOM SG_ 1244 FrontAxle1Load_ISig_6 600;
BA_REL_ "GenSigFirstTimeoutTime" BU_SG_REL_ VMCU SG_ 1244 FrontAxle1Load_ISig_6 3000;
BA_REL_ "GenSigTimeoutTime" BU_SG_REL_ VMCU SG_ 1244 FrontAxle1Load_ISig_6 600;
BA_REL_ "GenSigFirstTimeoutTime" BU_SG_REL_ EBS SG_ 1244 FrontAxle1Load_ISig_6 3000;
BA_REL_ "GenSigTimeoutTime" BU_SG_REL_ EBS SG_ 1244 FrontAxle1Load_ISig_6 600;
BA_REL_ "GenSigFirstTimeoutTime" BU_SG_REL_ APM SG_ 1244 FrontAxle1Load_ISig_6 3000;
BA_REL_ "GenSigTimeoutTime" BU_SG_REL_ APM SG_ 1244 FrontAxle1Load_ISig_6 600;
BA_REL_ "GenSigFirstTimeoutTime" BU_SG_REL_ FAS SG_ 1244 FrontAxle1Load_ISig_6 3000;
BA_REL_ "GenSigTimeoutTime" BU_SG_REL_ FAS SG_ 1244 FrontAxle1Load_ISig_6 600;
BA_REL_ "GenSigFirstTimeoutTime" BU_SG_REL_ VMCU SG_ 1244 ExtraBBSlidable5WFeedback 3000;
BA_REL_ "GenSigTimeoutTime" BU_SG_REL_ VMCU SG_ 1244 ExtraBBSlidable5WFeedback 600;
BA_REL_ "GenSigFirstTimeoutTime" BU_SG_REL_ RCIOM SG_ 1244 FrontAxleGrpBellowTorque 3000;
BA_REL_ "GenSigTimeoutTime" BU_SG_REL_ RCIOM SG_ 1244 FrontAxleGrpBellowTorque 600;
BA_REL_ "GenSigFirstTimeoutTime" BU_SG_REL_ RCIOM SG_ 1244 TrailerRevAndFogOutput_stat_ISig 3000;
BA_REL_ "GenSigTimeoutTime" BU_SG_REL_ RCIOM SG_ 1244 TrailerRevAndFogOutput_stat_ISig 600;
BA_REL_ "GenSigFirstTimeoutTime" BU_SG_REL_ VMCU SG_ 1244 TrailerRevAndFogOutput_stat_ISig 3000;
BA_REL_ "GenSigTimeoutTime" BU_SG_REL_ VMCU SG_ 1244 TrailerRevAndFogOutput_stat_ISig 600;
BA_REL_ "GenSigFirstTimeoutTime" BU_SG_REL_ VMCU SG_ 1244 ShortStopHeater_status_ISig_6 3000;
BA_REL_ "GenSigTimeoutTime" BU_SG_REL_ VMCU SG_ 1244 ShortStopHeater_status_ISig_6 600;
BA_REL_ "GenSigFirstTimeoutTime" BU_SG_REL_ APM SG_ 1244 FrontAxle2Load_ISig_6 3000;
BA_REL_ "GenSigTimeoutTime" BU_SG_REL_ APM SG_ 1244 FrontAxle2Load_ISig_6 600;
BA_REL_ "GenSigFirstTimeoutTime" BU_SG_REL_ FAS SG_ 1244 FrontAxle2Load_ISig_6 3000;
BA_REL_ "GenSigTimeoutTime" BU_SG_REL_ FAS SG_ 1244 FrontAxle2Load_ISig_6 600;
BA_REL_ "GenSigFirstTimeoutTime" BU_SG_REL_ VMCU SG_ 1244 FrontAxle2Load_ISig_6 3000;
BA_REL_ "GenSigTimeoutTime" BU_SG_REL_ VMCU SG_ 1244 FrontAxle2Load_ISig_6 600;
BA_REL_ "GenSigFirstTimeoutTime" BU_SG_REL_ RCIOM SG_ 1244 FrontAxle2Load_ISig_6 3000;
BA_REL_ "GenSigTimeoutTime" BU_SG_REL_ RCIOM SG_ 1244 FrontAxle2Load_ISig_6 600;
BA_REL_ "GenSigFirstTimeoutTime" BU_SG_REL_ EBS SG_ 1244 FrontAxle2Load_ISig_6 3000;
BA_REL_ "GenSigTimeoutTime" BU_SG_REL_ EBS SG_ 1244 FrontAxle2Load_ISig_6 600;
BA_REL_ "GenSigFirstTimeoutTime" BU_SG_REL_ RCIOM SG_ 1238 FrontAxleGroupLoad_ISig_6 3000;
BA_REL_ "GenSigTimeoutTime" BU_SG_REL_ RCIOM SG_ 1238 FrontAxleGroupLoad_ISig_6 300;
BA_REL_ "GenSigFirstTimeoutTime" BU_SG_REL_ VMCU SG_ 1238 FrontAxleGroupLoad_ISig_6 3000;
BA_REL_ "GenSigTimeoutTime" BU_SG_REL_ VMCU SG_ 1238 FrontAxleGroupLoad_ISig_6 300;
BA_REL_ "GenSigFirstTimeoutTime" BU_SG_REL_ RCIOM SG_ 1238 FrontStabilizerSpringRate 3000;
BA_REL_ "GenSigTimeoutTime" BU_SG_REL_ RCIOM SG_ 1238 FrontStabilizerSpringRate 300;
BA_REL_ "GenSigFirstTimeoutTime" BU_SG_REL_ FAS SG_ 1238 RelativeLevelFrontAxleLeft_ISig_ 3000;
BA_REL_ "GenSigTimeoutTime" BU_SG_REL_ FAS SG_ 1238 RelativeLevelFrontAxleLeft_ISig_ 300;
BA_REL_ "GenSigFirstTimeoutTime" BU_SG_REL_ EBS SG_ 1238 RelativeLevelFrontAxleLeft_ISig_ 3000;
BA_REL_ "GenSigTimeoutTime" BU_SG_REL_ EBS SG_ 1238 RelativeLevelFrontAxleLeft_ISig_ 300;
BA_REL_ "GenSigFirstTimeoutTime" BU_SG_REL_ VMCU SG_ 1238 RelativeLevelFrontAxleLeft_ISig_ 3000;
BA_REL_ "GenSigTimeoutTime" BU_SG_REL_ VMCU SG_ 1238 RelativeLevelFrontAxleLeft_ISig_ 300;
BA_REL_ "GenSigFirstTimeoutTime" BU_SG_REL_ RCIOM SG_ 1238 RelativeLevelFrontAxleLeft_ISig_ 3000;
BA_REL_ "GenSigTimeoutTime" BU_SG_REL_ RCIOM SG_ 1238 RelativeLevelFrontAxleLeft_ISig_ 300;
BA_REL_ "GenSigFirstTimeoutTime" BU_SG_REL_ RCIOM SG_ 1238 RelativeLevelFrontAxleRight_ISig 3000;
BA_REL_ "GenSigTimeoutTime" BU_SG_REL_ RCIOM SG_ 1238 RelativeLevelFrontAxleRight_ISig 300;
BA_REL_ "GenSigFirstTimeoutTime" BU_SG_REL_ VMCU SG_ 1238 RelativeLevelFrontAxleRight_ISig 3000;
BA_REL_ "GenSigTimeoutTime" BU_SG_REL_ VMCU SG_ 1238 RelativeLevelFrontAxleRight_ISig 300;
BA_REL_ "GenSigFirstTimeoutTime" BU_SG_REL_ EBS SG_ 1238 RelativeLevelFrontAxleRight_ISig 3000;
BA_REL_ "GenSigTimeoutTime" BU_SG_REL_ EBS SG_ 1238 RelativeLevelFrontAxleRight_ISig 300;
BA_REL_ "GenSigFirstTimeoutTime" BU_SG_REL_ RCIOM SG_ 1237 TotalFrBellowTrqMaxCapacity 3000;
BA_REL_ "GenSigTimeoutTime" BU_SG_REL_ RCIOM SG_ 1237 TotalFrBellowTrqMaxCapacity 300;
BA_REL_ "GenSigFirstTimeoutTime" BU_SG_REL_ VMCU SG_ 1237 BatterySOCTrustLevel_ISig_6 3000;
BA_REL_ "GenSigTimeoutTime" BU_SG_REL_ VMCU SG_ 1237 BatterySOCTrustLevel_ISig_6 300;
BA_REL_ "GenSigFirstTimeoutTime" BU_SG_REL_ RCIOM SG_ 1237 FrontAxleGrpUsedTorqueRef 3000;
BA_REL_ "GenSigTimeoutTime" BU_SG_REL_ RCIOM SG_ 1237 FrontAxleGrpUsedTorqueRef 300;
BA_REL_ "GenSigFirstTimeoutTime" BU_SG_REL_ BPMU SG_ 1237 BatterySOCAlertRawData_rqst_ISig 3000;
BA_REL_ "GenSigTimeoutTime" BU_SG_REL_ BPMU SG_ 1237 BatterySOCAlertRawData_rqst_ISig 300;
BA_REL_ "GenSigFirstTimeoutTime" BU_SG_REL_ VMCU SG_ 1237 BatterySOCAlertRawData_rqst_ISig 3000;
BA_REL_ "GenSigTimeoutTime" BU_SG_REL_ VMCU SG_ 1237 BatterySOCAlertRawData_rqst_ISig 300;
BA_REL_ "GenSigFirstTimeoutTime" BU_SG_REL_ RCIOM SG_ 1237 TotalFrontLoadTorque 3000;
BA_REL_ "GenSigTimeoutTime" BU_SG_REL_ RCIOM SG_ 1237 TotalFrontLoadTorque 300;
BA_REL_ "GenSigFirstTimeoutTime" BU_SG_REL_ VMCU SG_ 774 FuelVolume_ISig_6 3000;
BA_REL_ "GenSigTimeoutTime" BU_SG_REL_ VMCU SG_ 774 FuelVolume_ISig_6 500;
BA_REL_ "GenSigFirstTimeoutTime" BU_SG_REL_ APM SG_ 774 MainSwitch_Status 3000;
BA_REL_ "GenSigTimeoutTime" BU_SG_REL_ APM SG_ 774 MainSwitch_Status 150;
BA_REL_ "GenSigFirstTimeoutTime" BU_SG_REL_ BPMU SG_ 774 MainSwitch_Status 3000;
BA_REL_ "GenSigTimeoutTime" BU_SG_REL_ BPMU SG_ 774 MainSwitch_Status 150;
BA_REL_ "GenSigFirstTimeoutTime" BU_SG_REL_ VMCU SG_ 774 MainSwitch_Status 3000;
BA_REL_ "GenSigTimeoutTime" BU_SG_REL_ VMCU SG_ 774 MainSwitch_Status 150;
BA_REL_ "GenSigFirstTimeoutTime" BU_SG_REL_ VMCU SG_ 774 Pto1FeedbackStatus_ISig_6 3000;
BA_REL_ "GenSigTimeoutTime" BU_SG_REL_ VMCU SG_ 774 Pto1FeedbackStatus_ISig_6 500;
BA_REL_ "GenSigFirstTimeoutTime" BU_SG_REL_ RCIOM SG_ 774 SWBrakeSwitch2 3000;
BA_REL_ "GenSigTimeoutTime" BU_SG_REL_ RCIOM SG_ 774 SWBrakeSwitch2 600;
BA_REL_ "GenSigFirstTimeoutTime" BU_SG_REL_ VMCU SG_ 774 ReverseGearEngaged_ISig_6 3000;
BA_REL_ "GenSigTimeoutTime" BU_SG_REL_ VMCU SG_ 774 ReverseGearEngaged_ISig_6 500;
BA_REL_ "GenSigFirstTimeoutTime" BU_SG_REL_ FAS SG_ 774 ReverseGearEngaged_ISig_6 3000;
BA_REL_ "GenSigTimeoutTime" BU_SG_REL_ FAS SG_ 774 ReverseGearEngaged_ISig_6 500;
BA_REL_ "GenSigFirstTimeoutTime" BU_SG_REL_ APM SG_ 774 ReverseGearEngaged_ISig_6 3000;
BA_REL_ "GenSigTimeoutTime" BU_SG_REL_ APM SG_ 774 ReverseGearEngaged_ISig_6 500;
BA_REL_ "GenSigFirstTimeoutTime" BU_SG_REL_ RCIOM SG_ 774 ReverseGearEngaged_ISig_6 3000;
BA_REL_ "GenSigTimeoutTime" BU_SG_REL_ RCIOM SG_ 774 ReverseGearEngaged_ISig_6 500;
BA_REL_ "GenSigFirstTimeoutTime" BU_SG_REL_ VMCU SG_ 774 SecuredNeutralPosition_ISig_6 3000;
BA_REL_ "GenSigTimeoutTime" BU_SG_REL_ VMCU SG_ 774 SecuredNeutralPosition_ISig_6 500;
BA_REL_ "GenSigFirstTimeoutTime" BU_SG_REL_ EBS SG_ 774 SecuredNeutralPosition_ISig_6 3000;
BA_REL_ "GenSigTimeoutTime" BU_SG_REL_ EBS SG_ 774 SecuredNeutralPosition_ISig_6 500;
BA_REL_ "GenSigFirstTimeoutTime" BU_SG_REL_ APM SG_ 774 SecuredNeutralPosition_ISig_6 3000;
BA_REL_ "GenSigTimeoutTime" BU_SG_REL_ APM SG_ 774 SecuredNeutralPosition_ISig_6 500;
BA_REL_ "GenSigFirstTimeoutTime" BU_SG_REL_ VMCU SG_ 774 FuelLevel_ISig_6 3000;
BA_REL_ "GenSigTimeoutTime" BU_SG_REL_ VMCU SG_ 774 FuelLevel_ISig_6 500;
BA_REL_ "GenSigFirstTimeoutTime" BU_SG_REL_ VMCU SG_ 774 TransmSecuredForCrank_stat 3000;
BA_REL_ "GenSigTimeoutTime" BU_SG_REL_ VMCU SG_ 774 TransmSecuredForCrank_stat 150;
BA_REL_ "GenSigFirstTimeoutTime" BU_SG_REL_ RCIOM SG_ 774 FrontTargetLevelReached 3000;
BA_REL_ "GenSigTimeoutTime" BU_SG_REL_ RCIOM SG_ 774 FrontTargetLevelReached 150;
BA_REL_ "GenSigFirstTimeoutTime" BU_SG_REL_ VMCU SG_ 774 TransmissionNeutralSwitch_ISig_6 3000;
BA_REL_ "GenSigTimeoutTime" BU_SG_REL_ VMCU SG_ 774 TransmissionNeutralSwitch_ISig_6 500;
BA_REL_ "GenSigFirstTimeoutTime" BU_SG_REL_ APM SG_ 774 TransmissionNeutralSwitch_ISig_6 3000;
BA_REL_ "GenSigTimeoutTime" BU_SG_REL_ APM SG_ 774 TransmissionNeutralSwitch_ISig_6 500;
BA_REL_ "GenSigFirstTimeoutTime" BU_SG_REL_ RCIOM SG_ 774 BrakePressureSensorDemand2 3000;
BA_REL_ "GenSigTimeoutTime" BU_SG_REL_ RCIOM SG_ 774 BrakePressureSensorDemand2 600;
BA_REL_ "GenSigFirstTimeoutTime" BU_SG_REL_ VMCU SG_ 1245 StartBatterySOH 3000;
BA_REL_ "GenSigTimeoutTime" BU_SG_REL_ VMCU SG_ 1245 StartBatterySOH 600;
BA_REL_ "GenSigFirstTimeoutTime" BU_SG_REL_ VMCU SG_ 1245 JumpChargeAlert_stat_ISig_6 3000;
BA_REL_ "GenSigTimeoutTime" BU_SG_REL_ VMCU SG_ 1245 JumpChargeAlert_stat_ISig_6 600;
BA_REL_ "GenSigFirstTimeoutTime" BU_SG_REL_ VMCU SG_ 1245 StartBatteryDisplay_stat_ISig_6 3000;
BA_REL_ "GenSigTimeoutTime" BU_SG_REL_ VMCU SG_ 1245 StartBatteryDisplay_stat_ISig_6 600;
BA_REL_ "GenSigFirstTimeoutTime" BU_SG_REL_ VMCU SG_ 1245 StartBatteryReset_ack 3000;
BA_REL_ "GenSigTimeoutTime" BU_SG_REL_ VMCU SG_ 1245 StartBatteryReset_ack 600;
BA_REL_ "GenSigFirstTimeoutTime" BU_SG_REL_ VMCU SG_ 1245 SelfStartAssistSwitch_Input_ISig 3000;
BA_REL_ "GenSigTimeoutTime" BU_SG_REL_ VMCU SG_ 1245 SelfStartAssistSwitch_Input_ISig 600;
BA_REL_ "GenSigFirstTimeoutTime" BU_SG_REL_ VMCU SG_ 1245 SelfStartAssist_stat_ISig_6 3000;
BA_REL_ "GenSigTimeoutTime" BU_SG_REL_ VMCU SG_ 1245 SelfStartAssist_stat_ISig_6 600;
BA_REL_ "GenSigFirstTimeoutTime" BU_SG_REL_ VMCU SG_ 1245 StartBatterySOHTrustLevel 3000;
BA_REL_ "GenSigTimeoutTime" BU_SG_REL_ VMCU SG_ 1245 StartBatterySOHTrustLevel 600;
BA_REL_ "GenSigFirstTimeoutTime" BU_SG_REL_ CCIOM SG_ 1245 JumpChargeInterface_stat 3000;
BA_REL_ "GenSigTimeoutTime" BU_SG_REL_ CCIOM SG_ 1245 JumpChargeInterface_stat 600;
BA_REL_ "GenSigFirstTimeoutTime" BU_SG_REL_ CCIOM SG_ 1245 GridCharger_stat 3000;
BA_REL_ "GenSigTimeoutTime" BU_SG_REL_ CCIOM SG_ 1245 GridCharger_stat 600;
BA_REL_ "GenSigFirstTimeoutTime" BU_SG_REL_ VMCU SG_ 1246 APM_OBDRelDTC_PB_DtcIdB 3000;
BA_REL_ "GenSigTimeoutTime" BU_SG_REL_ VMCU SG_ 1246 APM_OBDRelDTC_PB_DtcIdB 600;
BA_REL_ "GenSigFirstTimeoutTime" BU_SG_REL_ VMCU SG_ 1246 PBStatusDisplay_cmd_ISig_6 3000;
BA_REL_ "GenSigTimeoutTime" BU_SG_REL_ VMCU SG_ 1246 PBStatusDisplay_cmd_ISig_6 600;
BA_REL_ "GenSigFirstTimeoutTime" BU_SG_REL_ VMCU SG_ 1246 APM_OBDRelDTC_PB_DrvngCycleB 3000;
BA_REL_ "GenSigTimeoutTime" BU_SG_REL_ VMCU SG_ 1246 APM_OBDRelDTC_PB_DrvngCycleB 600;
BA_REL_ "GenSigFirstTimeoutTime" BU_SG_REL_ VMCU SG_ 1246 AutoPBRelease_stat_ISig_6 3000;
BA_REL_ "GenSigTimeoutTime" BU_SG_REL_ VMCU SG_ 1246 AutoPBRelease_stat_ISig_6 600;
BA_REL_ "GenSigFirstTimeoutTime" BU_SG_REL_ VMCU SG_ 1246 APM_OBDRelDTC_PB_DtcIdA 3000;
BA_REL_ "GenSigTimeoutTime" BU_SG_REL_ VMCU SG_ 1246 APM_OBDRelDTC_PB_DtcIdA 600;
BA_REL_ "GenSigFirstTimeoutTime" BU_SG_REL_ VMCU SG_ 1246 APM_OBDRelDTC_PB_FailTB 3000;
BA_REL_ "GenSigTimeoutTime" BU_SG_REL_ VMCU SG_ 1246 APM_OBDRelDTC_PB_FailTB 600;
BA_REL_ "GenSigFirstTimeoutTime" BU_SG_REL_ VMCU SG_ 1246 APM_OBDRelDTC_PB_DrvngCycleA 3000;
BA_REL_ "GenSigTimeoutTime" BU_SG_REL_ VMCU SG_ 1246 APM_OBDRelDTC_PB_DrvngCycleA 600;
BA_REL_ "GenSigFirstTimeoutTime" BU_SG_REL_ VMCU SG_ 1246 APM_OBDRelDTC_PB_EvalResultB 3000;
BA_REL_ "GenSigTimeoutTime" BU_SG_REL_ VMCU SG_ 1246 APM_OBDRelDTC_PB_EvalResultB 600;
BA_REL_ "GenSigFirstTimeoutTime" BU_SG_REL_ VMCU SG_ 1246 APM_OBDRelDTC_PB_EvalStatA 3000;
BA_REL_ "GenSigTimeoutTime" BU_SG_REL_ VMCU SG_ 1246 APM_OBDRelDTC_PB_EvalStatA 600;
BA_REL_ "GenSigFirstTimeoutTime" BU_SG_REL_ VMCU SG_ 1246 APM_OBDRelDTC_PB_EvalStatB 3000;
BA_REL_ "GenSigTimeoutTime" BU_SG_REL_ VMCU SG_ 1246 APM_OBDRelDTC_PB_EvalStatB 600;
BA_REL_ "GenSigFirstTimeoutTime" BU_SG_REL_ VMCU SG_ 1246 APM_OBDRelDTC_PB_EvalResultA 3000;
BA_REL_ "GenSigTimeoutTime" BU_SG_REL_ VMCU SG_ 1246 APM_OBDRelDTC_PB_EvalResultA 600;
BA_REL_ "GenSigFirstTimeoutTime" BU_SG_REL_ VMCU SG_ 1246 APM_OBDRelDTC_PB_FailTA 3000;
BA_REL_ "GenSigTimeoutTime" BU_SG_REL_ VMCU SG_ 1246 APM_OBDRelDTC_PB_FailTA 600;
BA_REL_ "GenSigFirstTimeoutTime" BU_SG_REL_ VMCU SG_ 1492 APM_AirCtrMileagePrediction 48000;
BA_REL_ "GenSigTimeoutTime" BU_SG_REL_ VMCU SG_ 1492 APM_AirCtrMileagePrediction 12000;
BA_REL_ "GenSigFirstTimeoutTime" BU_SG_REL_ VMCU SG_ 1492 APM_AirCtrWearingPercentage 48000;
BA_REL_ "GenSigTimeoutTime" BU_SG_REL_ VMCU SG_ 1492 APM_AirCtrWearingPercentage 12000;
BA_REL_ "GenSigFirstTimeoutTime" BU_SG_REL_ VMCU SG_ 822 ParkBrakeWorkshopMode_ISig_6 3000;
BA_REL_ "GenSigTimeoutTime" BU_SG_REL_ VMCU SG_ 822 ParkBrakeWorkshopMode_ISig_6 180;
BA_REL_ "GenSigFirstTimeoutTime" BU_SG_REL_ EBS SG_ 822 APM_TrailerCircPressureStatus_IS 3000;
BA_REL_ "GenSigTimeoutTime" BU_SG_REL_ EBS SG_ 822 APM_TrailerCircPressureStatus_IS 180;
BA_REL_ "GenSigFirstTimeoutTime" BU_SG_REL_ VMCU SG_ 822 APM_TrailerCircPressureStatus_IS 3000;
BA_REL_ "GenSigTimeoutTime" BU_SG_REL_ VMCU SG_ 822 APM_TrailerCircPressureStatus_IS 180;
BA_REL_ "GenSigFirstTimeoutTime" BU_SG_REL_ EBS SG_ 822 APM_ParkingBrake_stat 3000;
BA_REL_ "GenSigTimeoutTime" BU_SG_REL_ EBS SG_ 822 APM_ParkingBrake_stat 500;
BA_REL_ "GenSigFirstTimeoutTime" BU_SG_REL_ VMCU SG_ 822 APM_ParkingBrake_stat 3000;
BA_REL_ "GenSigTimeoutTime" BU_SG_REL_ VMCU SG_ 822 APM_ParkingBrake_stat 500;
BA_REL_ "GenSigFirstTimeoutTime" BU_SG_REL_ RCIOM SG_ 822 APM_ParkingBrake_stat 3000;
BA_REL_ "GenSigTimeoutTime" BU_SG_REL_ RCIOM SG_ 822 APM_ParkingBrake_stat 500;
BA_REL_ "GenSigFirstTimeoutTime" BU_SG_REL_ FAS SG_ 822 APM_ParkingBrake_stat 3000;
BA_REL_ "GenSigTimeoutTime" BU_SG_REL_ FAS SG_ 822 APM_ParkingBrake_stat 500;
BA_REL_ "GenSigFirstTimeoutTime" BU_SG_REL_ VMCU SG_ 822 APM_OverrunMode_stat 3000;
BA_REL_ "GenSigTimeoutTime" BU_SG_REL_ VMCU SG_ 822 APM_OverrunMode_stat 180;
BA_REL_ "GenSigFirstTimeoutTime" BU_SG_REL_ VMCU SG_ 822 APM_AirCompressorStatus 3000;
BA_REL_ "GenSigTimeoutTime" BU_SG_REL_ VMCU SG_ 822 APM_AirCompressorStatus 180;
BA_REL_ "GenSigFirstTimeoutTime" BU_SG_REL_ EBS SG_ 822 ParkBrakeReleaseMode2_ISig_6 3000;
BA_REL_ "GenSigTimeoutTime" BU_SG_REL_ EBS SG_ 822 ParkBrakeReleaseMode2_ISig_6 180;
BA_REL_ "GenSigFirstTimeoutTime" BU_SG_REL_ VMCU SG_ 822 ParkBrakeReleaseMode2_ISig_6 3000;
BA_REL_ "GenSigTimeoutTime" BU_SG_REL_ VMCU SG_ 822 ParkBrakeReleaseMode2_ISig_6 180;
BA_REL_ "GenSigFirstTimeoutTime" BU_SG_REL_ VMCU SG_ 822 APM_PBReleasePossible_stat 3000;
BA_REL_ "GenSigTimeoutTime" BU_SG_REL_ VMCU SG_ 822 APM_PBReleasePossible_stat 180;
BA_REL_ "GenSigFirstTimeoutTime" BU_SG_REL_ EBS SG_ 822 APM_LowVMPBInfoReq 3000;
BA_REL_ "GenSigTimeoutTime" BU_SG_REL_ EBS SG_ 822 APM_LowVMPBInfoReq 180;
BA_REL_ "GenSigFirstTimeoutTime" BU_SG_REL_ VMCU SG_ 822 APM_PoorAirPressureInfo 3000;
BA_REL_ "GenSigTimeoutTime" BU_SG_REL_ VMCU SG_ 822 APM_PoorAirPressureInfo 500;
BA_REL_ "GenSigFirstTimeoutTime" BU_SG_REL_ VMCU SG_ 822 APM_ParkBrakeApplicationMode2 3000;
BA_REL_ "GenSigTimeoutTime" BU_SG_REL_ VMCU SG_ 822 APM_ParkBrakeApplicationMode2 180;
BA_REL_ "GenSigFirstTimeoutTime" BU_SG_REL_ EBS SG_ 822 APM_ParkBrakeApplicationMode2 3000;
BA_REL_ "GenSigTimeoutTime" BU_SG_REL_ EBS SG_ 822 APM_ParkBrakeApplicationMode2 180;
BA_REL_ "GenSigFirstTimeoutTime" BU_SG_REL_ CCIOM SG_ 822 EPBPowerFeedRequest 3000;
BA_REL_ "GenSigTimeoutTime" BU_SG_REL_ CCIOM SG_ 822 EPBPowerFeedRequest 180;
BA_REL_ "GenSigFirstTimeoutTime" BU_SG_REL_ VMCU SG_ 822 PBReleaseInhibit_EPBState_ISig_6 3000;
BA_REL_ "GenSigTimeoutTime" BU_SG_REL_ VMCU SG_ 822 PBReleaseInhibit_EPBState_ISig_6 180;
BA_REL_ "GenSigFirstTimeoutTime" BU_SG_REL_ VMCU SG_ 822 APM_AirDryerCtrReset_ack 3000;
BA_REL_ "GenSigTimeoutTime" BU_SG_REL_ VMCU SG_ 822 APM_AirDryerCtrReset_ack 180;
BA_REL_ "GenSigFirstTimeoutTime" BU_SG_REL_ VMCU SG_ 822 ParkBrakeAlert_ISig_6 3000;
BA_REL_ "GenSigTimeoutTime" BU_SG_REL_ VMCU SG_ 822 ParkBrakeAlert_ISig_6 180;
BA_REL_ "GenSigFirstTimeoutTime" BU_SG_REL_ RCIOM SG_ 1345 APM_ServiceBrakeAirPrsCircuit2 3000;
BA_REL_ "GenSigTimeoutTime" BU_SG_REL_ RCIOM SG_ 1345 APM_ServiceBrakeAirPrsCircuit2 1500;
BA_REL_ "GenSigFirstTimeoutTime" BU_SG_REL_ EAS SG_ 1345 APM_ServiceBrakeAirPrsCircuit2 6000;
BA_REL_ "GenSigTimeoutTime" BU_SG_REL_ EAS SG_ 1345 APM_ServiceBrakeAirPrsCircuit2 1500;
BA_REL_ "GenSigFirstTimeoutTime" BU_SG_REL_ VMCU SG_ 1345 APM_ServiceBrakeAirPrsCircuit2 6000;
BA_REL_ "GenSigTimeoutTime" BU_SG_REL_ VMCU SG_ 1345 APM_ServiceBrakeAirPrsCircuit2 1500;
BA_REL_ "GenSigFirstTimeoutTime" BU_SG_REL_ RCIOM SG_ 1345 APM_ServiceBrakeAirPrsCircuit1 3000;
BA_REL_ "GenSigTimeoutTime" BU_SG_REL_ RCIOM SG_ 1345 APM_ServiceBrakeAirPrsCircuit1 1500;
BA_REL_ "GenSigFirstTimeoutTime" BU_SG_REL_ VMCU SG_ 1345 APM_ServiceBrakeAirPrsCircuit1 6000;
BA_REL_ "GenSigTimeoutTime" BU_SG_REL_ VMCU SG_ 1345 APM_ServiceBrakeAirPrsCircuit1 1500;
BA_REL_ "GenSigFirstTimeoutTime" BU_SG_REL_ EAS SG_ 1345 APM_ServiceBrakeAirPrsCircuit1 6000;
BA_REL_ "GenSigTimeoutTime" BU_SG_REL_ EAS SG_ 1345 APM_ServiceBrakeAirPrsCircuit1 1500;
BA_REL_ "GenSigFirstTimeoutTime" BU_SG_REL_ VMCU SG_ 1345 APM_ParkAndTrailerAirPressure 6000;
BA_REL_ "GenSigTimeoutTime" BU_SG_REL_ VMCU SG_ 1345 APM_ParkAndTrailerAirPressure 1500;
BA_REL_ "GenSigFirstTimeoutTime" BU_SG_REL_ VMCU SG_ 1345 ExhManifAirInjectionInhibit_ISig 6000;
BA_REL_ "GenSigTimeoutTime" BU_SG_REL_ VMCU SG_ 1345 ExhManifAirInjectionInhibit_ISig 1500;
BA_REL_ "GenSigFirstTimeoutTime" BU_SG_REL_ VMCU SG_ 1345 APM_AirDryerCoolFanSpd_rqst 6000;
BA_REL_ "GenSigTimeoutTime" BU_SG_REL_ VMCU SG_ 1345 APM_AirDryerCoolFanSpd_rqst 1500;
BA_REL_ "GenSigFirstTimeoutTime" BU_SG_REL_ CCIOM SG_ 949 APM_ParkBrakeActuationStatus 3000;
BA_REL_ "GenSigTimeoutTime" BU_SG_REL_ CCIOM SG_ 949 APM_ParkBrakeActuationStatus 500;
BA_REL_ "GenSigFirstTimeoutTime" BU_SG_REL_ VMCU SG_ 949 APM_ParkBrakeActuationStatus 3000;
BA_REL_ "GenSigTimeoutTime" BU_SG_REL_ VMCU SG_ 949 APM_ParkBrakeActuationStatus 500;
BA_REL_ "GenSigFirstTimeoutTime" BU_SG_REL_ RCIOM SG_ 949 APM_ParkBrakeActuationStatus 3000;
BA_REL_ "GenSigTimeoutTime" BU_SG_REL_ RCIOM SG_ 949 APM_ParkBrakeActuationStatus 300;
BA_REL_ "GenSigFirstTimeoutTime" BU_SG_REL_ EBS SG_ 949 APM_ParkBrakeActuationStatus 3000;
BA_REL_ "GenSigTimeoutTime" BU_SG_REL_ EBS SG_ 949 APM_ParkBrakeActuationStatus 300;
BA_REL_ "GenSigFirstTimeoutTime" BU_SG_REL_ EAS SG_ 949 APM_ParkBrakeActuationStatus 3000;
BA_REL_ "GenSigTimeoutTime" BU_SG_REL_ EAS SG_ 949 APM_ParkBrakeActuationStatus 500;
BA_REL_ "GenSigFirstTimeoutTime" BU_SG_REL_ VMCU SG_ 949 EPBEngineStopAllowed 3000;
BA_REL_ "GenSigTimeoutTime" BU_SG_REL_ VMCU SG_ 949 EPBEngineStopAllowed 300;
BA_REL_ "GenSigFirstTimeoutTime" BU_SG_REL_ VMCU SG_ 949 APM_ESCReqAir_CtrlTrimMode 3000;
BA_REL_ "GenSigTimeoutTime" BU_SG_REL_ VMCU SG_ 949 APM_ESCReqAir_CtrlTrimMode 300;
BA_REL_ "GenSigFirstTimeoutTime" BU_SG_REL_ VMCU SG_ 949 APM_ESCReqAir_CtrlTrimStat 3000;
BA_REL_ "GenSigTimeoutTime" BU_SG_REL_ VMCU SG_ 949 APM_ESCReqAir_CtrlTrimStat 300;
BA_REL_ "GenSigFirstTimeoutTime" BU_SG_REL_ EBS SG_ 949 APM_PBChamberAirPressure 3000;
BA_REL_ "GenSigTimeoutTime" BU_SG_REL_ EBS SG_ 949 APM_PBChamberAirPressure 300;
BA_REL_ "GenSigFirstTimeoutTime" BU_SG_REL_ VMCU SG_ 949 APM_LowAirPressureAlert 3000;
BA_REL_ "GenSigTimeoutTime" BU_SG_REL_ VMCU SG_ 949 APM_LowAirPressureAlert 300;
BA_REL_ "GenSigFirstTimeoutTime" BU_SG_REL_ EBS SG_ 949 APM_LowAirPressureAlert 3000;
BA_REL_ "GenSigTimeoutTime" BU_SG_REL_ EBS SG_ 949 APM_LowAirPressureAlert 300;
BA_REL_ "GenSigFirstTimeoutTime" BU_SG_REL_ VMCU SG_ 949 APM_TrailerTest_stat 3000;
BA_REL_ "GenSigTimeoutTime" BU_SG_REL_ VMCU SG_ 949 APM_TrailerTest_stat 300;
BA_REL_ "GenSigFirstTimeoutTime" BU_SG_REL_ EBS SG_ 949 XPRsystemstate_ISig_6 3000;
BA_REL_ "GenSigTimeoutTime" BU_SG_REL_ EBS SG_ 949 XPRsystemstate_ISig_6 300;
BA_REL_ "GenSigFirstTimeoutTime" BU_SG_REL_ VMCU SG_ 949 XPRsystemstate_ISig_6 3000;
BA_REL_ "GenSigTimeoutTime" BU_SG_REL_ VMCU SG_ 949 XPRsystemstate_ISig_6 300;
BA_REL_ "GenSigFirstTimeoutTime" BU_SG_REL_ CCIOM SG_ 949 EPBBackupMode_ISig_6 3000;
BA_REL_ "GenSigTimeoutTime" BU_SG_REL_ CCIOM SG_ 949 EPBBackupMode_ISig_6 300;
BA_REL_ "GenSigFirstTimeoutTime" BU_SG_REL_ VMCU SG_ 949 EPBBackupMode_ISig_6 3000;
BA_REL_ "GenSigTimeoutTime" BU_SG_REL_ VMCU SG_ 949 EPBBackupMode_ISig_6 300;
BA_REL_ "GenSigFirstTimeoutTime" BU_SG_REL_ VMCU SG_ 949 APM_ESCReqAir_CtrlTrimValue 3000;
BA_REL_ "GenSigTimeoutTime" BU_SG_REL_ VMCU SG_ 949 APM_ESCReqAir_CtrlTrimValue 300;
BA_REL_ "GenSigFirstTimeoutTime" BU_SG_REL_ VMCU SG_ 949 APM_ESCReqAir_CtrlTrimReq 3000;
BA_REL_ "GenSigTimeoutTime" BU_SG_REL_ VMCU SG_ 949 APM_ESCReqAir_CtrlTrimReq 300;
BA_REL_ "GenSigFirstTimeoutTime" BU_SG_REL_ VMCU SG_ 949 PBReleaseAcceptance_stat_ISig_6 3000;
BA_REL_ "GenSigTimeoutTime" BU_SG_REL_ VMCU SG_ 949 PBReleaseAcceptance_stat_ISig_6 300;
BA_REL_ "GenSigFirstTimeoutTime" BU_SG_REL_ EBS SG_ 949 EPBHSARequest 3000;
BA_REL_ "GenSigTimeoutTime" BU_SG_REL_ EBS SG_ 949 EPBHSARequest 300;
VAL_ 1251 LivBatteryCharging_stat_ISig_6 3 "NotConfirmedConfirmed_NotAvailable" 2 "NotConfirmedConfirmed_Error" 1 "NotConfirmedConfirmed_Confirmed" 0 "NotConfirmedConfirmed_NotConfirmed" ;
VAL_ 1251 LivBatDisconnectDetectStat_ISig_ 3 "LivBatDisconnectDetectStat_Not_Available" 2 "LivBatDisconnectDetectStat_Error" 1 "LivBatDisconnectDetectStat_Battery_Disconnected" 0 "LivBatDisconnectDetectStat_Battery_NotDisconnected" ;
VAL_ 1251 DiffLockInterWhlStatSplitBox2 3 "DisengageEngage_NotAvailable" 2 "DisengageEngage_Error" 1 "DisengageEngage_Engage" 0 "DisengageEngage_Disengage" ;
VAL_ 1251 GearRangeUnengaged_ISig_6 3 "GearInhibation_NotAvailable" 2 "GearInhibation_Error" 1 "GearInhibation_GearChangeInhibited" 0 "GearInhibation_NoInhibation" ;
VAL_ 1251 SideMarkersLight4_FailStat 7 "FailStat_NotAvailable" 6 "FailStat_Error" 5 "FailStat_Spare2" 4 "FailStat_ShortCircuitToBatteryOrOpen" 3 "FailStat_ShortCircuitToBattery" 2 "FailStat_ShortCircuitToGround" 1 "FailStat_OpenCircuit" 0 "FailStat_NoError" ;
VAL_ 1251 GChargerStatus_ISig_6 7 "GridCharger_stat_NotAvailable" 6 "GridCharger_stat_Error" 5 "GridCharger_stat_Spare3" 4 "GridCharger_stat_GridChargerFailure" 3 "GridCharger_stat_MaintenanceCharging" 2 "GridCharger_stat_Charging" 1 "GridCharger_stat_Connected" 0 "GridCharger_stat_NotConnected" ;
VAL_ 1251 CCIOM_LowVMPBInfoReq 7 "LevelLow3bit_NotAvailable" 6 "LevelLow3bit_Error" 5 "LevelLow3bit_LowLevel5" 4 "LevelLow3bit_LowLevel4" 3 "LevelLow3bit_LowLevel3" 2 "LevelLow3bit_LowLevel2" 1 "LevelLow3bit_LowLevel1" 0 "LevelLow3bit_NoRequest" ;
VAL_ 1251 DiffLockInterWhlStatusFrAxle2 3 "DisengageEngage_NotAvailable" 2 "DisengageEngage_Error" 1 "DisengageEngage_Engage" 0 "DisengageEngage_Disengage" ;
VAL_ 950 CCIOM_AirCompressorStatus 3 "InactiveActive_NotAvailable" 2 "InactiveActive_Error" 1 "InactiveActive_Active" 0 "InactiveActive_Inactive" ;
VAL_ 950 CCIOM_PoorAirPressureInfo 3 "PoorAirPressureInfo_NotAvailable" 2 "PoorAirPressureInfo_Error" 1 "PoorAirPressureInfo_PoorAirPressure" 0 "PoorAirPressureInfo_NormalPressure" ;
VAL_ 950 CCIOM_AirDryerCtrReset_ack 3 "NokOk_NotAvailable" 2 "NokOk_Error" 1 "NokOk_OK" 0 "NokOk_NOK" ;
VAL_ 950 CCIOM_LowAirPressureAlert 3 "LowAirPressureAlert_NotAvailable" 2 "LowAirPressureAlert_Error" 1 "LowAirPressureAlert_LowPressure" 0 "LowAirPressureAlert_NormalPressure" ;
VAL_ 950 CCIOM_OverrunMode_stat 3 "InactiveActive_NotAvailable" 2 "InactiveActive_Error" 1 "InactiveActive_Active" 0 "InactiveActive_Inactive" ;
VAL_ 950 CCIOM_ParkingBrake_stat 3 "ParkingBrake_stat_NotAvailable" 2 "ParkingBrake_stat_Error" 1 "ParkingBrake_stat_ParkingBrakeActivated" 0 "ParkingBrake_stat_ParkingBrakeReleased" ;
VAL_ 950 CCIOM_ParkBrakeApplicationMode 7 "ParkBrakeApplicationMode_NotAvailable" 6 "ParkBrakeApplicationMode_Error" 5 "ParkBrakeApplicationMode_AutomaticInBackup" 4 "ParkBrakeApplicationMode_ExternalDemand" 3 "ParkBrakeApplicationMode_Automatically" 2 "ParkBrakeApplicationMode_ManuallyAtStandstill" 1 "ParkBrakeApplicationMode_ManuallyInDriving" 0 "ParkBrakeApplicationMode_Idle" ;
VAL_ 950 CCIOM_ParkBrakeAlert_ISig_6 3 "Alert_NotAvailable" 2 "Alert_Error" 1 "Alert_Alert" 0 "Alert_NoAlert" ;
VAL_ 950 CCIOM_ParkBrakeActuationStatus 7 "ParkBrakeActuationStatus_NotAvailable" 6 "ParkBrakeActuationStatus_Error" 5 "ParkBrakeActuationStatus_SpareValue_01" 4 "ParkBrakeActuationStatus_SpareValue" 3 "ParkBrakeActuationStatus_AntiCompound" 2 "ParkBrakeActuationStatus_Parked" 1 "ParkBrakeActuationStatus_PartiallyParked" 0 "ParkBrakeActuationStatus_Released" ;
VAL_ 1242 BatteryTempAlert_rqst_ISig_6 7 "BatteryTempAlert_rqst_NotAvailable" 6 "BatteryTempAlert_rqst_Error" 5 "BatteryTempAlert_rqst_Spare3" 4 "BatteryTempAlert_rqst_Spare2" 3 "BatteryTempAlert_rqst_Spare1" 2 "BatteryTempAlert_rqst_CriticalAlertLowTemp" 1 "BatteryTempAlert_rqst_PreAlertLowTemp" 0 "BatteryTempAlert_rqst_NoAlertRequested" ;
VAL_ 1242 BatteryTempAlertRawData_rqst_ISi 7 "BatteryTempAlert_rqst_NotAvailable" 6 "BatteryTempAlert_rqst_Error" 5 "BatteryTempAlert_rqst_Spare3" 4 "BatteryTempAlert_rqst_Spare2" 3 "BatteryTempAlert_rqst_Spare1" 2 "BatteryTempAlert_rqst_CriticalAlertLowTemp" 1 "BatteryTempAlert_rqst_PreAlertLowTemp" 0 "BatteryTempAlert_rqst_NoAlertRequested" ;
VAL_ 1510 ECSFrontCRC_Status 3 "CRCStatus_NotAvailable" 2 "CRCStatus_Error" 1 "CRCStatus_CRCCalculated" 0 "CRCStatus_CRCCalculationInProcess" ;
VAL_ 823 FifthWheelLockingInformation_ISi 15 "FifthWheelLockingInformation_NotAvailable" 14 "FifthWheelLockingInformation_Error" 13 "FifthWheelLockingInformation_Spare_07" 12 "FifthWheelLockingInformation_Spare_06" 11 "FifthWheelLockingInformation_Spare_05" 10 "FifthWheelLockingInformation_Spare_04" 9 "FifthWheelLockingInformation_Spare_03" 8 "FifthWheelLockingInformation_Spare_02" 7 "FifthWheelLockingInformation_Spare_01" 6 "FifthWheelLockingInformation_Spare" 5 "FifthWheelLockingInformation_5thWheelSystemError" 4 "FifthWheelLockingInformation_TrailerNotCorrectlyCoupled" 3 "FifthWheelLockingInformation_HandleLockedTrailerRightConnected" 2 "FifthWheelLockingInformation_KingPinEndPosTrailerPlateInContact" 1 "FifthWheelLockingInformation_TrailerPlateInContactW_semitrailer" 0 "FifthWheelLockingInformation_TractorAlone" ;
VAL_ 823 DoubleFrontAxleSteeringWarning_I 3 "DoubleFrontAxleSteeringWarning_NotAvailiable" 2 "DoubleFrontAxleSteeringWarning_Error" 1 "DoubleFrontAxleSteeringWarning_DoubleFrAxleSteeringBackupMode" 0 "DoubleFrontAxleSteeringWarning_NoRequest" ;
VAL_ 823 DifferentialLockStateFrAxle1_ISi 3 "DisengageEngage_NotAvailable" 2 "DisengageEngage_Error" 1 "DisengageEngage_Engage" 0 "DisengageEngage_Disengage" ;
VAL_ 823 DirInd_MiddleSide_Status 7 "DirIndFaultStatus_NotAvailable" 6 "DirIndFaultStatus_Error" 5 "DirIndFaultStatus_SpareValue_01" 4 "DirIndFaultStatus_SpareValue" 3 "DirIndFaultStatus_BothLeftAndRightDirectionIndicatorsFault" 2 "DirIndFaultStatus_RightDirectionIndicatorLampFault" 1 "DirIndFaultStatus_LeftDirectionIndicatorLampFault" 0 "DirIndFaultStatus_NoError" ;
VAL_ 823 ExtendedTrailerBrakeValveStat 3 "DeactivateActivateSpare_NotAvailable" 2 "DeactivateActivateSpare_Spare" 1 "DeactivateActivateSpare_Activate" 0 "DeactivateActivateSpare_Deactivate" ;
VAL_ 823 TransmLowRangeSenseSwitch_ISig_6 3 "OffOn_NotAvailable" 2 "OffOn_Error" 1 "OffOn_On" 0 "OffOn_Off" ;
VAL_ 823 ElectricalLoadReduction_rqst_ISi 7 "ElectricalLoadReduction_rqst_NotAvailable" 6 "ElectricalLoadReduction_rqst_Error" 5 "ElectricalLoadReduction_rqst_SpareValue_02" 4 "ElectricalLoadReduction_rqst_SpareValue_01" 3 "ElectricalLoadReduction_rqst_SpareValue" 2 "ElectricalLoadReduction_rqst_Level2Request" 1 "ElectricalLoadReduction_rqst_Level1Request" 0 "ElectricalLoadReduction_rqst_NoRequest" ;
VAL_ 823 WrknLghtChassisOutpFalr_stat 7 "ElectricalStatus_NotAvailable" 6 "ElectricalStatus_Error" 5 "ElectricalStatus_Spare_01" 4 "ElectricalStatus_Spare" 3 "ElectricalStatus_ShortCircuitToBattery" 2 "ElectricalStatus_ShortCircuitToGround" 1 "ElectricalStatus_OpenCircuit" 0 "ElectricalStatus_NoError" ;
VAL_ 823 LoadCutOffIndication_cmd_ISig_6 3 "LoadCutOffIndication_cmd_NotAvailable" 2 "LoadCutOffIndication_cmd_Error" 1 "LoadCutOffIndication_cmd_LoadCutOffIndication" 0 "LoadCutOffIndication_cmd_NoIndication" ;
VAL_ 823 TransmReverseDirectionSw_stat_IS 3 "OffOn_NotAvailable" 2 "OffOn_Error" 1 "OffOn_On" 0 "OffOn_Off" ;
VAL_ 823 BatterySOCAlert_rqst_ISig_6 7 "BatterySOCAlert_rqst_NotAvailable" 6 "BatterySOCAlert_rqst_ErrorIndicator" 5 "BatterySOCAlert_rqst_SpareValue_02" 4 "BatterySOCAlert_rqst_SpareValue_01" 3 "BatterySOCAlert_rqst_SpareValue" 2 "BatterySOCAlert_rqst_CriticalAlert" 1 "BatterySOCAlert_rqst_PreAlert" 0 "BatterySOCAlert_rqst_NoAlertRequested" ;
VAL_ 823 BatteryCapacity_Ack 3 "NokOk_NotAvailable" 2 "NokOk_Error" 1 "NokOk_OK" 0 "NokOk_NOK" ;
VAL_ 823 FrontLimpHomeTrigger 7 "LimpHomeTrigger_NotAvailable" 6 "LimpHomeTrigger_Error" 5 "LimpHomeTrigger_Spare_02" 4 "LimpHomeTrigger_Spare_01" 3 "LimpHomeTrigger_Spare" 2 "LimpHomeTrigger_NoControlLH" 1 "LimpHomeTrigger_ManualControlLH" 0 "LimpHomeTrigger_InactiveLH" ;
VAL_ 823 GearSplit_Status_ISig_6 3 "GearSplit_Status_NotAvailable" 2 "GearSplit_Status_Error" 1 "GearSplit_Status_HighSplit" 0 "GearSplit_Status_LowSplit" ;
VAL_ 823 DiffLockInterWhlStatusSplitBox_I 3 "DisengageEngage_NotAvailable" 2 "DisengageEngage_Error" 1 "DisengageEngage_Engage" 0 "DisengageEngage_Disengage" ;
VAL_ 823 FifthWheelHandleLock_ind 3 "UnlockedLocked_NotAvailable" 2 "UnlockedLocked_Error" 1 "UnlockedLocked_Locked" 0 "UnlockedLocked_Unlocked" ;
VAL_ 823 DifferentialLockStateCentral_ISi 3 "DisengageEngage_NotAvailable" 2 "DisengageEngage_Error" 1 "DisengageEngage_Engage" 0 "DisengageEngage_Disengage" ;
VAL_ 1244 TrailerBrakePres_stat 3 "InactiveActive_NotAvailable" 2 "InactiveActive_Error" 1 "InactiveActive_Active" 0 "InactiveActive_Inactive" ;
VAL_ 1244 ExtraBBContUnlockFeedback 3 "InactiveActive_NotAvailable" 2 "InactiveActive_Error" 1 "InactiveActive_Active" 0 "InactiveActive_Inactive" ;
VAL_ 1244 ExtraBBSlidable5WFeedback 3 "InactiveActive_NotAvailable" 2 "InactiveActive_Error" 1 "InactiveActive_Active" 0 "InactiveActive_Inactive" ;
VAL_ 1244 TrailerRevAndFogOutput_stat_ISig 3 "LightOutput_stat_NotAvailable" 2 "LightOutput_stat_OCOnAllActiveOutputs" 1 "LightOutput_stat_AtLeastOneOutputActive" 0 "LightOutput_stat_AllOutputsInactive" ;
VAL_ 1244 ShortStopHeater_status_ISig_6 7 "ShortStopHeaterStatus_NotAvailable" 6 "ShortStopHeaterStatus_Error" 5 "ShortStopHeaterStatus_Spare3" 4 "ShortStopHeaterStatus_Spare2" 3 "ShortStopHeaterStatus_Spare1" 2 "ShortStopHeaterStatus_ActivatedAndPumpNotEngaged" 1 "ShortStopHeaterStatus_ActivatedAndPumpEngaged" 0 "ShortStopHeaterStatus_NotActivated" ;
VAL_ 1237 BatterySOCAlertRawData_rqst_ISig 7 "BatterySOCAlert_rqst_NotAvailable" 6 "BatterySOCAlert_rqst_ErrorIndicator" 5 "BatterySOCAlert_rqst_SpareValue_02" 4 "BatterySOCAlert_rqst_SpareValue_01" 3 "BatterySOCAlert_rqst_SpareValue" 2 "BatterySOCAlert_rqst_CriticalAlert" 1 "BatterySOCAlert_rqst_PreAlert" 0 "BatterySOCAlert_rqst_NoAlertRequested" ;
VAL_ 774 MainSwitch_Status 3 "ClosedOpen_NotAvailable" 2 "ClosedOpen_Error" 1 "ClosedOpen_Open" 0 "ClosedOpen_Closed" ;
VAL_ 774 Pto1FeedbackStatus_ISig_6 3 "OffOn_NotAvailable" 2 "OffOn_Error" 1 "OffOn_On" 0 "OffOn_Off" ;
VAL_ 774 SWBrakeSwitch2 3 "BrakeSwitch_NotAvailable" 2 "BrakeSwitch_Error" 1 "BrakeSwitch_BrakePedalDepressed" 0 "BrakeSwitch_BrakePedalReleased" ;
VAL_ 774 ReverseGearEngaged_ISig_6 3 "ReverseGearEngaged_NotAvailable" 2 "ReverseGearEngaged_Error" 1 "ReverseGearEngaged_ReverseGearEngaged" 0 "ReverseGearEngaged_ReverseGearNotEngaged" ;
VAL_ 774 SecuredNeutralPosition_ISig_6 3 "SecuredNeutralPosition_NotAvailable" 2 "SecuredNeutralPosition_Error" 1 "SecuredNeutralPosition_SecuredNeutralPosition" 0 "SecuredNeutralPosition_NotInSecuredNeutralPosition" ;
VAL_ 774 TransmSecuredForCrank_stat 3 "TransmSecuredForCrank_stat_NotAvailable" 2 "TransmSecuredForCrank_stat_Error" 1 "TransmSecuredForCrank_stat_TransmissionReadyForCrank" 0 "TransmSecuredForCrank_stat_TransmissionNotReadyForCrank" ;
VAL_ 774 FrontTargetLevelReached 3 "InactiveActive_NotAvailable" 2 "InactiveActive_Error" 1 "InactiveActive_Active" 0 "InactiveActive_Inactive" ;
VAL_ 774 TransmissionNeutralSwitch_ISig_6 3 "TransmissionNeutralSwitch_NotAvailable" 2 "TransmissionNeutralSwitch_Error" 1 "TransmissionNeutralSwitch_TransmissionInNeutral" 0 "TransmissionNeutralSwitch_TransmissionNotInNeutral" ;
VAL_ 1245 JumpChargeAlert_stat_ISig_6 7 "JumpChargeAlert_stat_NotAvailable" 6 "JumpChargeAlert_stat_Error" 5 "JumpChargeAlert_stat_Spare3" 4 "JumpChargeAlert_stat_Spare2" 3 "JumpChargeAlert_stat_Spare1" 2 "JumpChargeAlert_stat_InternalFailure" 1 "JumpChargeAlert_stat_JumpVoltage_tooHigh" 0 "JumpChargeAlert_stat_NoAlert" ;
VAL_ 1245 StartBatteryDisplay_stat_ISig_6 7 "StartBatteryDisplay_NotAvailable" 6 "StartBatteryDisplay_Error" 5 "StartBatteryDisplay_StartBattery_ShortCircuit" 4 "StartBatteryDisplay_StartBattery_OverVoltage" 3 "StartBatteryDisplay_StartBattery_OpenCircuit" 2 "StartBatteryDisplay_StartBattery_Idle" 1 "StartBatteryDisplay_StartBattery_Charged" 0 "StartBatteryDisplay_StartBattery_Charging" ;
VAL_ 1245 StartBatteryReset_ack 3 "NokOk_NotAvailable" 2 "NokOk_Error" 1 "NokOk_OK" 0 "NokOk_NOK" ;
VAL_ 1245 SelfStartAssistSwitch_Input_ISig 3 "Request_NotAvailable" 2 "Request_Error" 1 "Request_RequestActive" 0 "Request_NotRequested" ;
VAL_ 1245 SelfStartAssist_stat_ISig_6 3 "Request_NotAvailable" 2 "Request_Error" 1 "Request_RequestActive" 0 "Request_NotRequested" ;
VAL_ 1245 JumpChargeInterface_stat 3 "Connection_Status_NotAvailable" 2 "Connection_Status_Error" 1 "Connection_Status_Connected" 0 "Connection_Status_NotConnected" ;
VAL_ 1245 GridCharger_stat 7 "GridCharger_stat_NotAvailable" 6 "GridCharger_stat_Error" 5 "GridCharger_stat_Spare3" 4 "GridCharger_stat_GridChargerFailure" 3 "GridCharger_stat_MaintenanceCharging" 2 "GridCharger_stat_Charging" 1 "GridCharger_stat_Connected" 0 "GridCharger_stat_NotConnected" ;
VAL_ 1246 PBStatusDisplay_cmd_ISig_6 3 "DisableEnable_NotAvailable" 2 "DisableEnable_Error" 1 "DisableEnable_Enable" 0 "DisableEnable_Disable" ;
VAL_ 1246 APM_OBDRelDTC_PB_DrvngCycleB 3 "DrivingCycleLSBB_NotAvailable" 2 "DrivingCycleLSBB_Error" 1 "DrivingCycleLSBB_Value1" 0 "DrivingCycleLSBB_Value0" ;
VAL_ 1246 AutoPBRelease_stat_ISig_6 3 "AutoPBRelease_stat_NotAvailable" 2 "AutoPBRelease_stat_Error" 1 "AutoPBRelease_stat_FunctionInhibited" 0 "AutoPBRelease_stat_FunctionArmed" ;
VAL_ 1246 APM_OBDRelDTC_PB_DrvngCycleA 3 "DrivingCycleLSBA_NotAvailable" 2 "DrivingCycleLSBA_Error" 1 "DrivingCycleLSBA_Value1" 0 "DrivingCycleLSBA_Value0" ;
VAL_ 1246 APM_OBDRelDTC_PB_EvalResultB 3 "DTCEvalResultB_NotAvailable" 2 "DTCEvalResultB_Error" 1 "DTCEvalResultB_Passed" 0 "DTCEvalResultB_Failed" ;
VAL_ 1246 APM_OBDRelDTC_PB_EvalStatA 3 "DTCEvalStatA_NotAvailable" 2 "DTCEvalStatA_Error" 1 "DTCEvalStatA_Complete" 0 "DTCEvalStatA_Incomplete" ;
VAL_ 1246 APM_OBDRelDTC_PB_EvalStatB 3 "DTCEvalStatB_NotAvailable" 2 "DTCEvalStatB_Error" 1 "DTCEvalStatB_Complete" 0 "DTCEvalStatB_Incomplete" ;
VAL_ 1246 APM_OBDRelDTC_PB_EvalResultA 3 "DTCEvalResultA_NotAvailable" 2 "DTCEvalResultA_Error" 1 "DTCEvalResultA_Passed" 0 "DTCEvalResultA_Failed" ;
VAL_ 822 ParkBrakeWorkshopMode_ISig_6 3 "ParkBrakeWorkshopMode_NotAvailable" 2 "ParkBrakeWorkshopMode_Error" 1 "ParkBrakeWorkshopMode_WorkshopMode" 0 "ParkBrakeWorkshopMode_NormalMode" ;
VAL_ 822 APM_TrailerCircPressureStatus_IS 3 "TrailerCircuitPressureStatus_NotAvailable" 2 "TrailerCircuitPressureStatus_Error" 1 "TrailerCircuitPressureStatus_EnabledLowPressureAlert" 0 "TrailerCircuitPressureStatus_DisabledLowPressureAlert" ;
VAL_ 822 APM_ParkingBrake_stat 3 "ParkingBrake_stat_NotAvailable" 2 "ParkingBrake_stat_Error" 1 "ParkingBrake_stat_ParkingBrakeActivated" 0 "ParkingBrake_stat_ParkingBrakeReleased" ;
VAL_ 822 APM_OverrunMode_stat 3 "InactiveActive_NotAvailable" 2 "InactiveActive_Error" 1 "InactiveActive_Active" 0 "InactiveActive_Inactive" ;
VAL_ 822 APM_AirCompressorStatus 3 "InactiveActive_NotAvailable" 2 "InactiveActive_Error" 1 "InactiveActive_Active" 0 "InactiveActive_Inactive" ;
VAL_ 822 ParkBrakeReleaseMode2_ISig_6 15 "ParkBrakeReleaseMode2_NotAvailable" 14 "ParkBrakeReleaseMode2_Error" 13 "ParkBrakeReleaseMode2_Reserved7" 12 "ParkBrakeReleaseMode2_Reserved6" 11 "ParkBrakeReleaseMode2_Reserved5" 10 "ParkBrakeReleaseMode2_Reserved4" 9 "ParkBrakeReleaseMode2_Reserved3" 8 "ParkBrakeReleaseMode2_Reserved2" 7 "ParkBrakeReleaseMode2_Reserved1" 6 "ParkBrakeReleaseMode2_AutomaticallyinHillHolder" 5 "ParkBrakeReleaseMode2_AutomaticInBackup" 4 "ParkBrakeReleaseMode2_ExternalDemand" 3 "ParkBrakeReleaseMode2_AutomaticallyAccelPedal" 2 "ParkBrakeReleaseMode2_ManuallyAtStandstill" 1 "ParkBrakeReleaseMode2_ManuallyInDriving" 0 "ParkBrakeReleaseMode2_Idle" ;
VAL_ 822 APM_PBReleasePossible_stat 3 "ParkBrakeReleasePossible_stat_NotAvailable" 2 "ParkBrakeReleasePossible_stat_Error" 1 "ParkBrakeReleasePossible_stat_Possible_PressureOK" 0 "ParkBrakeReleasePossible_stat_NotPossible_LowerPressure" ;
VAL_ 822 APM_LowVMPBInfoReq 7 "LevelLow3bit_NotAvailable" 6 "LevelLow3bit_Error" 5 "LevelLow3bit_LowLevel5" 4 "LevelLow3bit_LowLevel4" 3 "LevelLow3bit_LowLevel3" 2 "LevelLow3bit_LowLevel2" 1 "LevelLow3bit_LowLevel1" 0 "LevelLow3bit_NoRequest" ;
VAL_ 822 APM_PoorAirPressureInfo 3 "PoorAirPressureInfo_NotAvailable" 2 "PoorAirPressureInfo_Error" 1 "PoorAirPressureInfo_PoorAirPressure" 0 "PoorAirPressureInfo_NormalPressure" ;
VAL_ 822 APM_ParkBrakeApplicationMode2 15 "ParkBrakeApplicationMode2_NotAvailable" 14 "ParkBrakeApplicationMode2_Error" 13 "ParkBrakeApplicationMode2_Reserved5" 12 "ParkBrakeApplicationMode2_Reserved4" 11 "ParkBrakeApplicationMode2_Reserved3" 10 "ParkBrakeApplicationMode2_Reserved2" 9 "ParkBrakeApplicationMode2_Reserved1" 8 "ParkBrakeApplicationMode2_AutomaticcallyDoorOpen" 7 "ParkBrakeApplicationMode2_ParkBrakeBlending" 6 "ParkBrakeApplicationMode2_AutomaticallyHillHolder" 5 "ParkBrakeApplicationMode2_AutomaticInBackup" 4 "ParkBrakeApplicationMode2_ExternalDemand" 3 "ParkBrakeApplicationMode2_AutomaticallyKeyOff" 2 "ParkBrakeApplicationMode2_ManuallyAtStandstill" 1 "ParkBrakeApplicationMode2_ManuallyInDriving" 0 "ParkBrakeApplicationMode2_Idle" ;
VAL_ 822 EPBPowerFeedRequest 3 "Request_NotAvailable" 2 "Request_Error" 1 "Request_RequestActive" 0 "Request_NotRequested" ;
VAL_ 822 PBReleaseInhibit_EPBState_ISig_6 7 "PBReleaseInhibit_State_NotAvailable" 6 "PBReleaseInhibit_State_Error" 5 "PBReleaseInhibit_State_AutoReleaseCommandBeingInhibited" 4 "PBReleaseInhibit_State_XPRReleaseCommandBeingInhibited" 3 "PBReleaseInhibit_State_ManualReleaseCommandBeingInhibited" 2 "PBReleaseInhibit_State_Active" 1 "PBReleaseInhibit_State_FullyOperationalNotActive" 0 "PBReleaseInhibit_State_NotOperational" ;
VAL_ 822 APM_AirDryerCtrReset_ack 3 "NokOk_NotAvailable" 2 "NokOk_Error" 1 "NokOk_OK" 0 "NokOk_NOK" ;
VAL_ 822 ParkBrakeAlert_ISig_6 3 "Alert_NotAvailable" 2 "Alert_Error" 1 "Alert_Alert" 0 "Alert_NoAlert" ;
VAL_ 1345 ExhManifAirInjectionInhibit_ISig 3 "InhibitedStatus_NotAvailable" 2 "InhibitedStatus_Error" 1 "InhibitedStatus_Inhibited" 0 "InhibitedStatus_NotInhibited" ;
VAL_ 949 APM_ParkBrakeActuationStatus 7 "ParkBrakeActuationStatus_NotAvailable" 6 "ParkBrakeActuationStatus_Error" 5 "ParkBrakeActuationStatus_SpareValue_01" 4 "ParkBrakeActuationStatus_SpareValue" 3 "ParkBrakeActuationStatus_AntiCompound" 2 "ParkBrakeActuationStatus_Parked" 1 "ParkBrakeActuationStatus_PartiallyParked" 0 "ParkBrakeActuationStatus_Released" ;
VAL_ 949 EPBEngineStopAllowed 7 "EPBEngineStopAllowed_NotAvailable" 6 "EPBEngineStopAllowed_Error" 5 "EPBEngineStopAllowed_Spare_03" 4 "EPBEngineStopAllowed_Spare_02" 3 "EPBEngineStopAllowed_Spare_01" 2 "EPBEngineStopAllowed_TemporarilyAllowed" 1 "EPBEngineStopAllowed_Allowed" 0 "EPBEngineStopAllowed_NotAllowed" ;
VAL_ 949 APM_ESCReqAir_CtrlTrimMode 15 "CtrlTrimMode_NotAvailable" 14 "CtrlTrimMode_Error" 13 "CtrlTrimMode_Spare_08" 12 "CtrlTrimMode_Spare_07" 11 "CtrlTrimMode_Spare_06" 10 "CtrlTrimMode_Spare_05" 9 "CtrlTrimMode_Spare_04" 8 "CtrlTrimMode_Spare_03" 7 "CtrlTrimMode_Spare_02" 6 "CtrlTrimMode_Spare_01" 5 "CtrlTrimMode_Spare" 4 "CtrlTrimMode_MuddySiteEngineSpeedControl" 3 "CtrlTrimMode_AirManagementEngineSpeedControl" 2 "CtrlTrimMode_IdleAdjust" 1 "CtrlTrimMode_PTOEngineSpeedControl" 0 "CtrlTrimMode_NoRequest" ;
VAL_ 949 APM_ESCReqAir_CtrlTrimStat 7 "CtrlTrimStat_NotAvailable" 6 "CtrlTrimStat_Error" 5 "CtrlTrimStat_Spare_02" 4 "CtrlTrimStat_Spare_01" 3 "CtrlTrimStat_Spare" 2 "CtrlTrimStat_TrimActive" 1 "CtrlTrimStat_ControlActive" 0 "CtrlTrimStat_NoRequestActive" ;
VAL_ 949 APM_LowAirPressureAlert 3 "LowAirPressureAlert_NotAvailable" 2 "LowAirPressureAlert_Error" 1 "LowAirPressureAlert_LowPressure" 0 "LowAirPressureAlert_NormalPressure" ;
VAL_ 949 APM_TrailerTest_stat 7 "TrailerTest_stat_NotAvailable" 6 "TrailerTest_stat_Error" 5 "TrailerTest_stat_InProgress_TrailerNotConnected" 4 "TrailerTest_stat_NotPossibleLowVoltgeOrLowPressure" 3 "TrailerTest_stat_TrailerTestIncentive" 2 "TrailerTest_stat_NotPossibleServiceBrakeApplied" 1 "TrailerTest_stat_InProgress" 0 "TrailerTest_stat_IdleNoTrailerTest" ;
VAL_ 949 EPBBackupMode_ISig_6 15 "EPBBackupMode_NotAvailable" 14 "EPBBackupMode_Error" 13 "EPBBackupMode_Level13" 12 "EPBBackupMode_Level12" 11 "EPBBackupMode_Level11" 10 "EPBBackupMode_Level10" 9 "EPBBackupMode_Level9" 8 "EPBBackupMode_Level8" 7 "EPBBackupMode_Level7" 6 "EPBBackupMode_Level6" 5 "EPBBackupMode_Level5" 4 "EPBBackupMode_Level4" 3 "EPBBackupMode_Level3" 2 "EPBBackupMode_Level2" 1 "EPBBackupMode_Level1" 0 "EPBBackupMode_Level0_NoBackUp" ;
VAL_ 949 APM_ESCReqAir_CtrlTrimReq 7 "CtrlTrimReq_NotAvailable" 6 "CtrlTrimReq_Error" 5 "CtrlTrimReq_Spare_02" 4 "CtrlTrimReq_Spare_01" 3 "CtrlTrimReq_Spare" 2 "CtrlTrimReq_TrimRampDown" 1 "CtrlTrimReq_TrimRampUp" 0 "CtrlTrimReq_NoRamp" ;
VAL_ 949 PBReleaseAcceptance_stat_ISig_6 7 "PBReleaseAcceptance_stat_NotAvailable" 6 "PBReleaseAcceptance_stat_Error" 5 "PBReleaseAcceptance_stat_Spare_03" 4 "PBReleaseAcceptance_stat_AccelPedalOrHCURequested" 3 "PBReleaseAcceptance_stat_ReleaseRequestAccepted" 2 "PBReleaseAcceptance_stat_BrakeOrAccelPedalRequested" 1 "PBReleaseAcceptance_stat_BrakePedalRequested" 0 "PBReleaseAcceptance_stat_NoRequestDetectedOrRequestAborted" ;
VAL_ 949 EPBHSARequest 7 "EPBHSARequest_NotAvailable" 6 "EPBHSARequest_Error" 5 "EPBHSARequest_Spare_3" 4 "EPBHSARequest_Spare_2" 3 "EPBHSARequest_Spare_1" 2 "EPBHSARequest_Requested" 1 "EPBHSARequest_NotRequestedReleaseWhenPossible" 0 "EPBHSARequest_NotRequestedReleaseImmediately" ;
SIG_GROUP_ 1510 ECSFrontCRC_sg 1 : ECSFrontCRC_CRC ECSFrontCRC_Status;
SIG_GROUP_ 1246 APM_OBDRelDTC_PB_sg 1 : APM_OBDRelDTC_PB_DtcIdB APM_OBDRelDTC_PB_DrvngCycleB APM_OBDRelDTC_PB_DtcIdA APM_OBDRelDTC_PB_FailTB APM_OBDRelDTC_PB_DrvngCycleA APM_OBDRelDTC_PB_EvalResultB APM_OBDRelDTC_PB_EvalStatA APM_OBDRelDTC_PB_EvalStatB APM_OBDRelDTC_PB_EvalResultA APM_OBDRelDTC_PB_FailTA;
SIG_GROUP_ 949 APM_ESCReqAir_sg 1 : APM_ESCReqAir_CtrlTrimMode APM_ESCReqAir_CtrlTrimStat APM_ESCReqAir_CtrlTrimValue APM_ESCReqAir_CtrlTrimReq;
